VERSION ""

NS_ :

BS_:

BU_: CLU AMP H_U CGW TMU

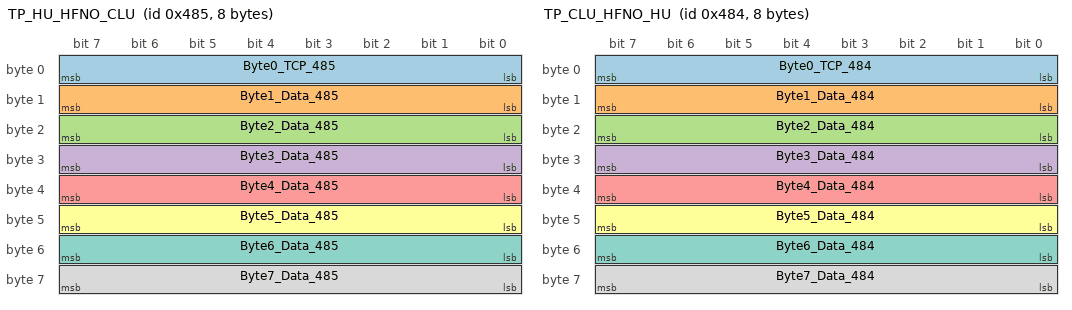
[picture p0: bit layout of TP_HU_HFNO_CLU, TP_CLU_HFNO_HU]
BO_ 1157 TP_HU_HFNO_CLU: 8 H_U
 SG_ Byte0_TCP_485 : 7|8@0+ (1,0) [0|0] ""  CLU
 SG_ Byte1_Data_485 : 15|8@0+ (1,0) [0|0] ""  CLU
 SG_ Byte2_Data_485 : 23|8@0+ (1,0) [0|0] ""  CLU
 SG_ Byte3_Data_485 : 31|8@0+ (1,0) [0|0] ""  CLU
 SG_ Byte4_Data_485 : 39|8@0+ (1,0) [0|0] ""  CLU
 SG_ Byte5_Data_485 : 47|8@0+ (1,0) [0|0] ""  CLU
 SG_ Byte6_Data_485 : 55|8@0+ (1,0) [0|0] ""  CLU
 SG_ Byte7_Data_485 : 63|8@0+ (1,0) [0|0] ""  CLU

BO_ 1156 TP_CLU_HFNO_HU: 8 CLU
 SG_ Byte0_TCP_484 : 7|8@0+ (1,0) [0|0] ""  H_U
 SG_ Byte1_Data_484 : 15|8@0+ (1,0) [0|0] ""  H_U
 SG_ Byte2_Data_484 : 23|8@0+ (1,0) [0|0] ""  H_U
 SG_ Byte3_Data_484 : 31|8@0+ (1,0) [0|0] ""  H_U
 SG_ Byte4_Data_484 : 39|8@0+ (1,0) [0|0] ""  H_U
 SG_ Byte5_Data_484 : 47|8@0+ (1,0) [0|0] ""  H_U
 SG_ Byte6_Data_484 : 55|8@0+ (1,0) [0|0] ""  H_U
 SG_ Byte7_Data_484 : 63|8@0+ (1,0) [0|0] ""  H_U

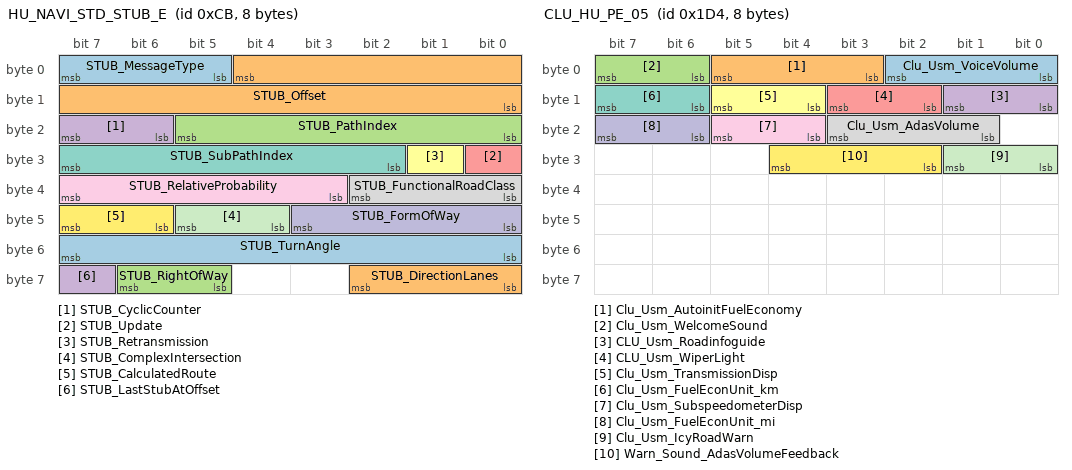
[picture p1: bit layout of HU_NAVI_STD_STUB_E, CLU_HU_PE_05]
BO_ 203 HU_NAVI_STD_STUB_E: 8 H_U
 SG_ STUB_MessageType : 7|3@0+ (1,0) [0|0] ""  CGW,CLU
 SG_ STUB_Offset : 4|13@0+ (1,0) [0|0] "m"  CGW,CLU
 SG_ STUB_PathIndex : 21|6@0+ (1,0) [0|0] ""  CGW,CLU
 SG_ STUB_CyclicCounter : 23|2@0+ (1,0) [0|0] ""  CGW,CLU
 SG_ STUB_Update : 24|1@0+ (1,0) [0|0] ""  CGW,CLU
 SG_ STUB_Retransmission : 25|1@0+ (1,0) [0|0] ""  CGW,CLU
 SG_ STUB_SubPathIndex : 31|6@0+ (1,0) [0|0] ""  CGW,CLU
 SG_ STUB_FunctionalRoadClass : 34|3@0+ (1,0) [0|0] ""  CGW,CLU
 SG_ STUB_RelativeProbability : 39|5@0+ (3.333,0) [0|0] "%"  CGW,CLU
 SG_ STUB_FormOfWay : 43|4@0+ (1,0) [0|0] ""  CGW,CLU
 SG_ STUB_ComplexIntersection : 45|2@0+ (1,0) [0|0] ""  CGW,CLU
 SG_ STUB_CalculatedRoute : 47|2@0+ (1,0) [0|0] ""  CGW,CLU
 SG_ STUB_TurnAngle : 55|8@0+ (1.417,0) [0|0] ""  CGW,CLU
 SG_ STUB_DirectionLanes : 58|3@0+ (1,0) [0|0] ""  CGW,CLU
 SG_ STUB_RightOfWay : 62|2@0+ (1,0) [0|0] ""  CGW,CLU
 SG_ STUB_LastStubAtOffset : 63|1@0+ (1,0) [0|0] ""  CGW,CLU

BO_ 202 HU_NAVI_STD_SEG_E: 8 H_U
 SG_ SEG_MessageType : 7|3@0+ (1,0) [0|0] ""  CGW,CLU
 SG_ SEG_Offset : 4|13@0+ (1,0) [0|0] "m"  CGW,CLU
 SG_ SEG_PathIndex : 21|6@0+ (1,0) [0|0] ""  CGW,CLU
 SG_ SEG_CyclicCounter : 23|2@0+ (1,0) [0|0] ""  CGW,CLU
 SG_ SEG_Update : 24|1@0+ (1,0) [0|0] ""  CGW,CLU
 SG_ SEG_Retransmission : 25|1@0+ (1,0) [0|0] ""  CGW,CLU
 SG_ SEG_BuiltUpArea : 27|2@0+ (1,0) [0|0] ""  CGW,CLU
 SG_ SEG_Bridge : 29|2@0+ (1,0) [0|0] ""  CGW,CLU
 SG_ SEG_Tunnel : 31|2@0+ (1,0) [0|0] ""  CGW,CLU
 SG_ SEG_FunctionalRoadClass : 34|3@0+ (1,0) [0|0] ""  CGW,CLU
 SG_ SEG_RelativeProbability : 39|5@0+ (3.333,0) [0|0] "%"  CGW,CLU
 SG_ SEG_FormOfWay : 43|4@0+ (1,0) [0|0] ""  CGW,CLU
 SG_ SEG_ComplexIntersection : 45|2@0+ (1,0) [0|0] ""  CGW,CLU
 SG_ SEG_CalculatedRoute : 47|2@0+ (1,0) [0|0] ""  CGW,CLU
 SG_ SEG_SpeedLimitType : 50|3@0+ (1,0) [0|0] ""  CGW,CLU
 SG_ SEG_SpeedLimit : 55|5@0+ (1,0) [0|0] ""  CGW,CLU
 SG_ SEG_DirectionLanes : 58|3@0+ (1,0) [0|0] ""  CGW,CLU
 SG_ SEG_SpeedLimitUnder5 : 62|3@0+ (1,0) [0|0] ""  CGW,CLU

BO_ 468 CLU_HU_PE_05: 8 CLU
 SG_ Clu_Usm_VoiceVolume : 2|3@0+ (1,0) [0|7] ""  H_U
 SG_ Clu_Usm_AutoinitFuelEconomy : 5|3@0+ (1,0) [0|7] ""  H_U
 SG_ Clu_Usm_WelcomeSound : 7|2@0+ (1,0) [0|3] ""  H_U
 SG_ CLU_Usm_Roadinfoguide : 9|2@0+ (1,0) [0|3] ""  H_U
 SG_ CLU_Usm_WiperLight : 11|2@0+ (1,0) [0|3] ""  H_U
 SG_ Clu_Usm_TransmissionDisp : 13|2@0+ (1,0) [0|3] ""  H_U
 SG_ Clu_Usm_FuelEconUnit_km : 15|2@0+ (1,0) [0|3] ""  H_U
 SG_ Clu_Usm_AdasVolume : 19|3@0+ (1,0) [0|7] ""  AMP,H_U
 SG_ Clu_Usm_SubspeedometerDisp : 21|2@0+ (1,0) [0|3] ""  H_U
 SG_ Clu_Usm_FuelEconUnit_mi : 23|2@0+ (1,0) [0|3] ""  H_U
 SG_ Clu_Usm_IcyRoadWarn : 25|2@0+ (1,0) [0|0] ""  H_U
 SG_ Warn_Sound_AdasVolumeFeedback : 28|3@0+ (1,0) [0|7] ""  AMP,H_U

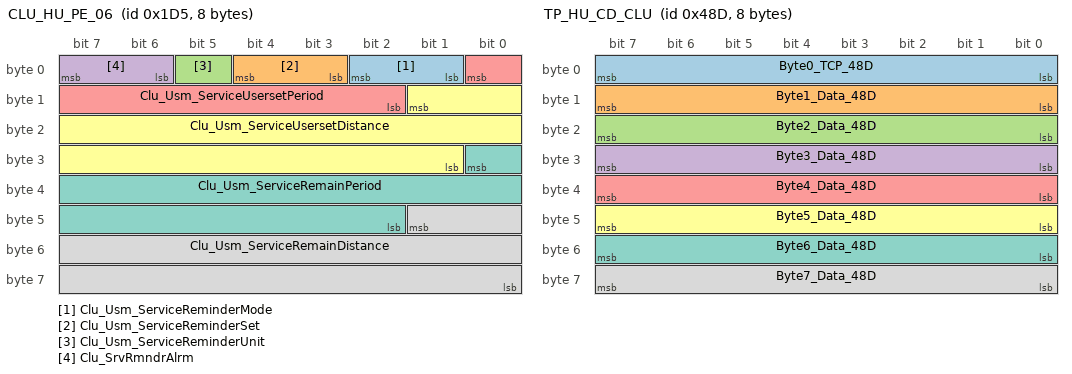
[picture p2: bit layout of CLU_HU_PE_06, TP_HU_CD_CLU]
BO_ 469 CLU_HU_PE_06: 8 CLU
 SG_ Clu_Usm_ServiceReminderMode : 2|2@0+ (1,0) [0|3] ""  H_U
 SG_ Clu_Usm_ServiceReminderSet : 4|2@0+ (1,0) [0|3] ""  H_U
 SG_ Clu_Usm_ServiceReminderUnit : 5|1@0+ (1,0) [0|1] ""  H_U
 SG_ Clu_SrvRmndrAlrm : 7|2@0+ (1,0) [0|0] ""  H_U
 SG_ Clu_Usm_ServiceUsersetPeriod : 0|7@0+ (1,0) [0|127] ""  H_U
 SG_ Clu_Usm_ServiceUsersetDistance : 9|17@0+ (1,0) [0|131071] ""  H_U
 SG_ Clu_Usm_ServiceRemainPeriod : 24|15@0+ (1,0) [0|32767] ""  H_U
 SG_ Clu_Usm_ServiceRemainDistance : 41|18@0+ (1,0) [0|262143] ""  H_U

BO_ 1165 TP_HU_CD_CLU: 8 H_U
 SG_ Byte0_TCP_48D : 7|8@0+ (1,0) [0|0] ""  CLU
 SG_ Byte1_Data_48D : 15|8@0+ (1,0) [0|0] ""  CLU
 SG_ Byte2_Data_48D : 23|8@0+ (1,0) [0|0] ""  CLU
 SG_ Byte3_Data_48D : 31|8@0+ (1,0) [0|0] ""  CLU
 SG_ Byte4_Data_48D : 39|8@0+ (1,0) [0|0] ""  CLU
 SG_ Byte5_Data_48D : 47|8@0+ (1,0) [0|0] ""  CLU
 SG_ Byte6_Data_48D : 55|8@0+ (1,0) [0|0] ""  CLU
 SG_ Byte7_Data_48D : 63|8@0+ (1,0) [0|0] ""  CLU

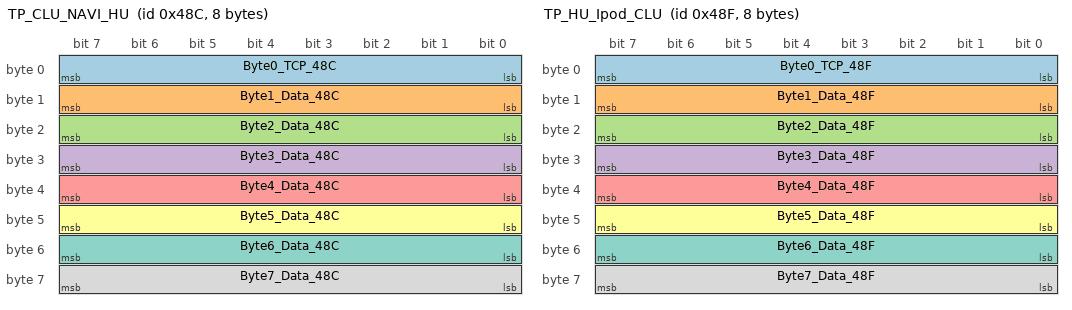
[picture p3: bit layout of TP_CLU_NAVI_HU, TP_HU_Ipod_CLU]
BO_ 1164 TP_CLU_NAVI_HU: 8 CLU
 SG_ Byte0_TCP_48C : 7|8@0+ (1,0) [0|0] ""  H_U
 SG_ Byte1_Data_48C : 15|8@0+ (1,0) [0|0] ""  H_U
 SG_ Byte2_Data_48C : 23|8@0+ (1,0) [0|0] ""  H_U
 SG_ Byte3_Data_48C : 31|8@0+ (1,0) [0|0] ""  H_U
 SG_ Byte4_Data_48C : 39|8@0+ (1,0) [0|0] ""  H_U
 SG_ Byte5_Data_48C : 47|8@0+ (1,0) [0|0] ""  H_U
 SG_ Byte6_Data_48C : 55|8@0+ (1,0) [0|0] ""  H_U
 SG_ Byte7_Data_48C : 63|8@0+ (1,0) [0|0] ""  H_U

BO_ 1167 TP_HU_Ipod_CLU: 8 H_U
 SG_ Byte0_TCP_48F : 7|8@0+ (1,0) [0|0] ""  CLU
 SG_ Byte1_Data_48F : 15|8@0+ (1,0) [0|0] ""  CLU
 SG_ Byte2_Data_48F : 23|8@0+ (1,0) [0|0] ""  CLU
 SG_ Byte3_Data_48F : 31|8@0+ (1,0) [0|0] ""  CLU
 SG_ Byte4_Data_48F : 39|8@0+ (1,0) [0|0] ""  CLU
 SG_ Byte5_Data_48F : 47|8@0+ (1,0) [0|0] ""  CLU
 SG_ Byte6_Data_48F : 55|8@0+ (1,0) [0|0] ""  CLU
 SG_ Byte7_Data_48F : 63|8@0+ (1,0) [0|0] ""  CLU

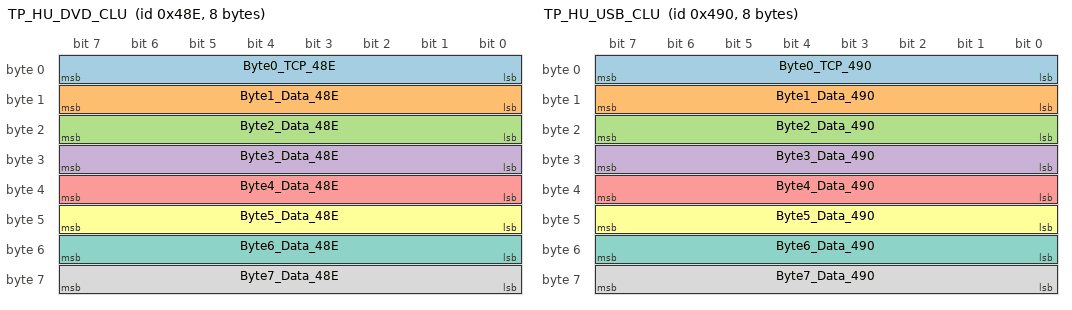
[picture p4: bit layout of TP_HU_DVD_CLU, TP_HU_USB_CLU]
BO_ 1166 TP_HU_DVD_CLU: 8 H_U
 SG_ Byte0_TCP_48E : 7|8@0+ (1,0) [0|0] ""  CLU
 SG_ Byte1_Data_48E : 15|8@0+ (1,0) [0|0] ""  CLU
 SG_ Byte2_Data_48E : 23|8@0+ (1,0) [0|0] ""  CLU
 SG_ Byte3_Data_48E : 31|8@0+ (1,0) [0|0] ""  CLU
 SG_ Byte4_Data_48E : 39|8@0+ (1,0) [0|0] ""  CLU
 SG_ Byte5_Data_48E : 47|8@0+ (1,0) [0|0] ""  CLU
 SG_ Byte6_Data_48E : 55|8@0+ (1,0) [0|0] ""  CLU
 SG_ Byte7_Data_48E : 63|8@0+ (1,0) [0|0] ""  CLU

BO_ 1168 TP_HU_USB_CLU: 8 H_U
 SG_ Byte0_TCP_490 : 7|8@0+ (1,0) [0|0] ""  CLU
 SG_ Byte1_Data_490 : 15|8@0+ (1,0) [0|0] ""  CLU
 SG_ Byte2_Data_490 : 23|8@0+ (1,0) [0|0] ""  CLU
 SG_ Byte3_Data_490 : 31|8@0+ (1,0) [0|0] ""  CLU
 SG_ Byte4_Data_490 : 39|8@0+ (1,0) [0|0] ""  CLU
 SG_ Byte5_Data_490 : 47|8@0+ (1,0) [0|0] ""  CLU
 SG_ Byte6_Data_490 : 55|8@0+ (1,0) [0|0] ""  CLU
 SG_ Byte7_Data_490 : 63|8@0+ (1,0) [0|0] ""  CLU

BO_ 1408 AMP_HU_P_01: 8 AMP
 SG_ AMP_Support_ElecSound : 57|2@0+ (1,0) [0|0] ""  CLU,H_U

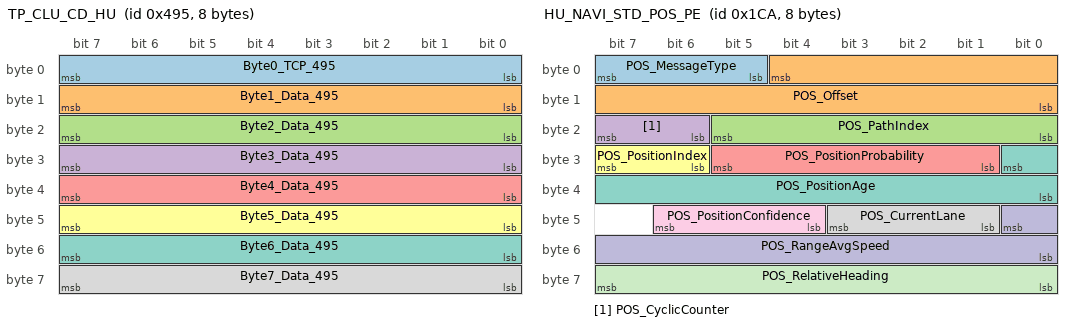
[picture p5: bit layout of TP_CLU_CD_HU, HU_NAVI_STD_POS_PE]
BO_ 1173 TP_CLU_CD_HU: 8 CLU
 SG_ Byte0_TCP_495 : 7|8@0+ (1,0) [0|0] ""  H_U
 SG_ Byte1_Data_495 : 15|8@0+ (1,0) [0|0] ""  H_U
 SG_ Byte2_Data_495 : 23|8@0+ (1,0) [0|0] ""  H_U
 SG_ Byte3_Data_495 : 31|8@0+ (1,0) [0|0] ""  H_U
 SG_ Byte4_Data_495 : 39|8@0+ (1,0) [0|0] ""  H_U
 SG_ Byte5_Data_495 : 47|8@0+ (1,0) [0|0] ""  H_U
 SG_ Byte6_Data_495 : 55|8@0+ (1,0) [0|0] ""  H_U
 SG_ Byte7_Data_495 : 63|8@0+ (1,0) [0|0] ""  H_U

BO_ 458 HU_NAVI_STD_POS_PE: 8 H_U
 SG_ POS_MessageType : 7|3@0+ (1,0) [0|0] ""  CGW,CLU
 SG_ POS_Offset : 4|13@0+ (1,0) [0|0] "m"  CGW,CLU
 SG_ POS_PathIndex : 21|6@0+ (1,0) [0|0] ""  CGW,CLU
 SG_ POS_CyclicCounter : 23|2@0+ (1,0) [0|0] ""  CGW,CLU
 SG_ POS_PositionProbability : 29|5@0+ (3.333,0) [0|0] "%"  CGW,CLU
 SG_ POS_PositionIndex : 31|2@0+ (1,0) [0|0] ""  CGW,CLU
 SG_ POS_PositionAge : 24|9@0+ (5,0) [0|0] "ms"  CGW,CLU
 SG_ POS_CurrentLane : 43|3@0+ (1,0) [0|0] ""  CGW,CLU
 SG_ POS_PositionConfidence : 46|3@0+ (1,0) [0|0] ""  CGW,CLU
 SG_ POS_RangeAvgSpeed : 40|9@0+ (1,0) [0|0] "km/h"  CGW,CLU
 SG_ POS_RelativeHeading : 63|8@0+ (1.417,0) [0|0] ""  CGW,CLU

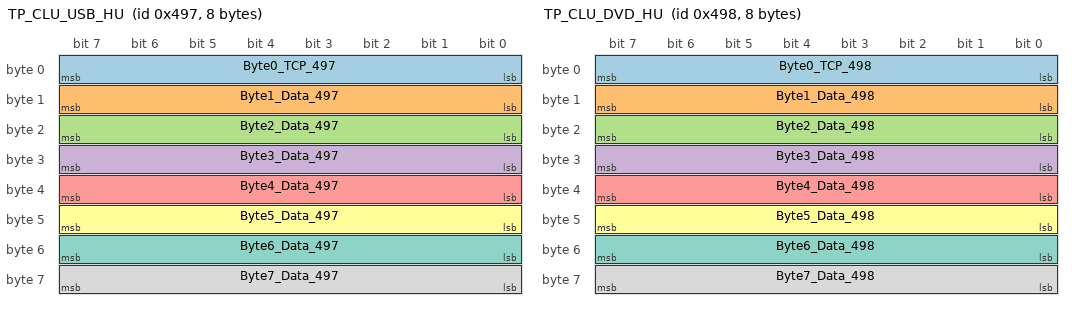
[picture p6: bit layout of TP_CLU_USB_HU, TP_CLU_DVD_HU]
BO_ 1175 TP_CLU_USB_HU: 8 CLU
 SG_ Byte0_TCP_497 : 7|8@0+ (1,0) [0|0] ""  H_U
 SG_ Byte1_Data_497 : 15|8@0+ (1,0) [0|0] ""  H_U
 SG_ Byte2_Data_497 : 23|8@0+ (1,0) [0|0] ""  H_U
 SG_ Byte3_Data_497 : 31|8@0+ (1,0) [0|0] ""  H_U
 SG_ Byte4_Data_497 : 39|8@0+ (1,0) [0|0] ""  H_U
 SG_ Byte5_Data_497 : 47|8@0+ (1,0) [0|0] ""  H_U
 SG_ Byte6_Data_497 : 55|8@0+ (1,0) [0|0] ""  H_U
 SG_ Byte7_Data_497 : 63|8@0+ (1,0) [0|0] ""  H_U

BO_ 1176 TP_CLU_DVD_HU: 8 CLU
 SG_ Byte0_TCP_498 : 7|8@0+ (1,0) [0|0] ""  H_U
 SG_ Byte1_Data_498 : 15|8@0+ (1,0) [0|0] ""  H_U
 SG_ Byte2_Data_498 : 23|8@0+ (1,0) [0|0] ""  H_U
 SG_ Byte3_Data_498 : 31|8@0+ (1,0) [0|0] ""  H_U
 SG_ Byte4_Data_498 : 39|8@0+ (1,0) [0|0] ""  H_U
 SG_ Byte5_Data_498 : 47|8@0+ (1,0) [0|0] ""  H_U
 SG_ Byte6_Data_498 : 55|8@0+ (1,0) [0|0] ""  H_U
 SG_ Byte7_Data_498 : 63|8@0+ (1,0) [0|0] ""  H_U

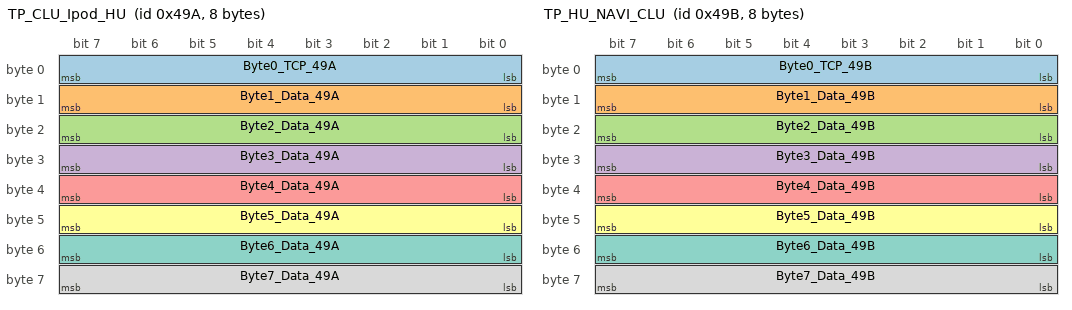
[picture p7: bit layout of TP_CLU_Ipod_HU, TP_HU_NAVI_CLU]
BO_ 1178 TP_CLU_Ipod_HU: 8 CLU
 SG_ Byte0_TCP_49A : 7|8@0+ (1,0) [0|0] ""  H_U
 SG_ Byte1_Data_49A : 15|8@0+ (1,0) [0|0] ""  H_U
 SG_ Byte2_Data_49A : 23|8@0+ (1,0) [0|0] ""  H_U
 SG_ Byte3_Data_49A : 31|8@0+ (1,0) [0|0] ""  H_U
 SG_ Byte4_Data_49A : 39|8@0+ (1,0) [0|0] ""  H_U
 SG_ Byte5_Data_49A : 47|8@0+ (1,0) [0|0] ""  H_U
 SG_ Byte6_Data_49A : 55|8@0+ (1,0) [0|0] ""  H_U
 SG_ Byte7_Data_49A : 63|8@0+ (1,0) [0|0] ""  H_U

BO_ 1179 TP_HU_NAVI_CLU: 8 H_U
 SG_ Byte0_TCP_49B : 7|8@0+ (1,0) [0|0] ""  CLU
 SG_ Byte1_Data_49B : 15|8@0+ (1,0) [0|0] ""  CLU
 SG_ Byte2_Data_49B : 23|8@0+ (1,0) [0|0] ""  CLU
 SG_ Byte3_Data_49B : 31|8@0+ (1,0) [0|0] ""  CLU
 SG_ Byte4_Data_49B : 39|8@0+ (1,0) [0|0] ""  CLU
 SG_ Byte5_Data_49B : 47|8@0+ (1,0) [0|0] ""  CLU
 SG_ Byte6_Data_49B : 55|8@0+ (1,0) [0|0] ""  CLU
 SG_ Byte7_Data_49B : 63|8@0+ (1,0) [0|0] ""  CLU

BO_ 88 HU_RVM_E_00: 8 H_U
 SG_ HU_RVM_CameraOff : 1|2@0+ (1,0) [0|0] ""  CGW,CLU

BO_ 448 HU_DATC_PE_00: 8 H_U
 SG_ HU_VRActivity : 33|2@0+ (1,0) [0|0] ""  CGW,CLU,TMU
 SG_ HU_PhoneActivity : 35|2@0+ (1,0) [0|0] ""  CGW,CLU,TMU

BO_ 102 HU_USM_E_02: 8 H_U
 SG_ CF_AVN_PTGSpeedNValueSet : 39|2@0+ (1,0) [0|0] ""  CGW,CLU
 SG_ CF_Avn_HAPTICWARNINGNValueSet : 54|3@0+ (1,0) [0|0] ""  CGW,CLU

BO_ 101 HU_USM_E_01: 8 H_U
 SG_ CF_AVN_LFANValueSet : 4|2@0+ (1,0) [0|0] ""  CGW,CLU
 SG_ CF_AVN_FCANValueSet : 7|3@0+ (1,0) [0|0] ""  CGW,CLU
 SG_ CF_AVN_HDANValueSet : 9|2@0+ (1,0) [0|0] ""  CGW,CLU
 SG_ CF_AVN_DAWModeNValueSet : 12|3@0+ (1,0) [0|0] ""  CGW,CLU
 SG_ CF_AVN_SCCDrvModeNValueSet : 15|3@0+ (1,0) [0|0] ""  CGW,CLU
 SG_ CF_AVN_NSCCCamNValueSet : 19|2@0+ (1,0) [0|0] ""  CGW,CLU
 SG_ CF_AVN_SEANValueSet : 21|2@0+ (1,0) [0|0] ""  CGW,CLU
 SG_ CF_AVN_BCWNValueSet : 23|2@0+ (1,0) [0|0] ""  CGW,CLU
 SG_ CF_AVN_WarningTimingNValueSet : 26|3@0+ (1,0) [0|0] ""  CGW,CLU
 SG_ CF_AVN_ISLWNValueSet : 28|2@0+ (1,0) [0|0] ""  CGW,CLU
 SG_ CF_AVN_BCANValueSet : 31|3@0+ (1,0) [0|0] ""  CGW,CLU
 SG_ CF_AVN_RCCWNValueSet : 41|2@0+ (1,0) [0|0] ""  CGW,CLU
 SG_ CF_AVN_BCWSndWanNValueSet : 43|2@0+ (1,0) [0|0] ""  CGW,CLU
 SG_ CF_AVN_NSCCCrvNValueSet : 45|2@0+ (1,0) [0|0] ""  CGW,CLU
 SG_ CF_SccFrVehDptNotiNValueSet : 49|2@0+ (1,0) [0|0] ""  CGW,CLU
 SG_ CF_AVN_LkaModeNValueSet : 54|3@0+ (1,0) [0|0] ""  CGW,CLU
 SG_ CF_AVN_AdasVolumeNValueSet : 58|3@0+ (1,0) [0|0] ""  CLU

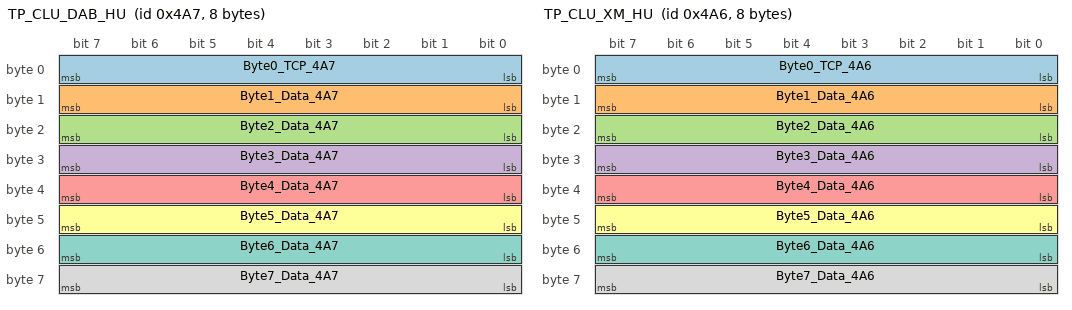
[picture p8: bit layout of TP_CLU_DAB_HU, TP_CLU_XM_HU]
BO_ 1191 TP_CLU_DAB_HU: 8 CLU
 SG_ Byte0_TCP_4A7 : 7|8@0+ (1,0) [0|0] ""  H_U
 SG_ Byte1_Data_4A7 : 15|8@0+ (1,0) [0|0] ""  H_U
 SG_ Byte2_Data_4A7 : 23|8@0+ (1,0) [0|0] ""  H_U
 SG_ Byte3_Data_4A7 : 31|8@0+ (1,0) [0|0] ""  H_U
 SG_ Byte4_Data_4A7 : 39|8@0+ (1,0) [0|0] ""  H_U
 SG_ Byte5_Data_4A7 : 47|8@0+ (1,0) [0|0] ""  H_U
 SG_ Byte6_Data_4A7 : 55|8@0+ (1,0) [0|0] ""  H_U
 SG_ Byte7_Data_4A7 : 63|8@0+ (1,0) [0|0] ""  H_U

BO_ 369 HU_Car_PE_01: 8 H_U
 SG_ HU_VehiclePwr : 3|4@0+ (1,0) [0|0] ""  AMP,CLU,TMU

BO_ 1190 TP_CLU_XM_HU: 8 CLU
 SG_ Byte0_TCP_4A6 : 7|8@0+ (1,0) [0|0] ""  H_U
 SG_ Byte1_Data_4A6 : 15|8@0+ (1,0) [0|0] ""  H_U
 SG_ Byte2_Data_4A6 : 23|8@0+ (1,0) [0|0] ""  H_U
 SG_ Byte3_Data_4A6 : 31|8@0+ (1,0) [0|0] ""  H_U
 SG_ Byte4_Data_4A6 : 39|8@0+ (1,0) [0|0] ""  H_U
 SG_ Byte5_Data_4A6 : 47|8@0+ (1,0) [0|0] ""  H_U
 SG_ Byte6_Data_4A6 : 55|8@0+ (1,0) [0|0] ""  H_U
 SG_ Byte7_Data_4A6 : 63|8@0+ (1,0) [0|0] ""  H_U

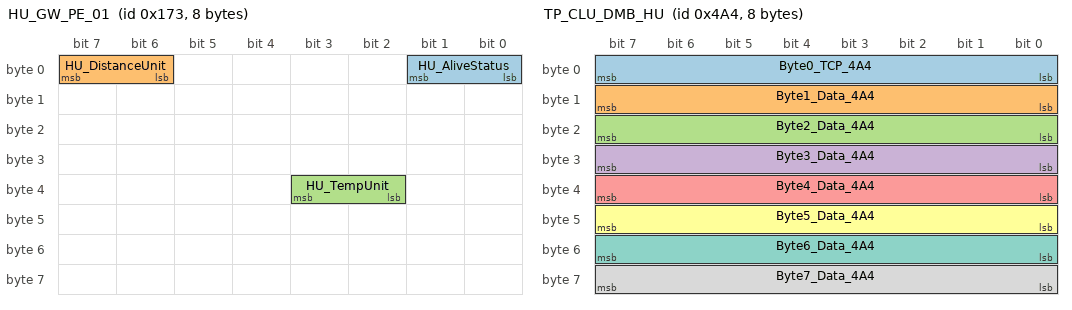
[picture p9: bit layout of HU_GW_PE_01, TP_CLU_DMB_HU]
BO_ 371 HU_GW_PE_01: 8 H_U
 SG_ HU_AliveStatus : 1|2@0+ (1,0) [0|0] ""  CGW,CLU,TMU
 SG_ HU_DistanceUnit : 7|2@0+ (1,0) [0|0] ""  CLU,TMU
 SG_ HU_TempUnit : 35|2@0+ (1,0) [0|0] ""  CGW,CLU

BO_ 1188 TP_CLU_DMB_HU: 8 CLU
 SG_ Byte0_TCP_4A4 : 7|8@0+ (1,0) [0|0] ""  H_U
 SG_ Byte1_Data_4A4 : 15|8@0+ (1,0) [0|0] ""  H_U
 SG_ Byte2_Data_4A4 : 23|8@0+ (1,0) [0|0] ""  H_U
 SG_ Byte3_Data_4A4 : 31|8@0+ (1,0) [0|0] ""  H_U
 SG_ Byte4_Data_4A4 : 39|8@0+ (1,0) [0|0] ""  H_U
 SG_ Byte5_Data_4A4 : 47|8@0+ (1,0) [0|0] ""  H_U
 SG_ Byte6_Data_4A4 : 55|8@0+ (1,0) [0|0] ""  H_U
 SG_ Byte7_Data_4A4 : 63|8@0+ (1,0) [0|0] ""  H_U

BO_ 104 HU_USM_E_04: 8 H_U
 SG_ CF_AVN_CluVoiceVolume : 2|3@0+ (1,0) [0|0] ""  CLU
 SG_ CF_AVN_CluAutoInitFuelEconomy : 5|3@0+ (1,0) [0|0] ""  CLU
 SG_ CF_AVN_CluWelcomeSnd : 7|2@0+ (1,0) [0|0] ""  CLU
 SG_ CF_AVN_CluRoadInfoGuide : 9|2@0+ (1,0) [0|0] ""  CLU
 SG_ CF_AVN_CluWiperLight : 11|2@0+ (1,0) [0|0] ""  CLU
 SG_ CF_AVN_CluTransmissionDisp : 13|2@0+ (1,0) [0|0] ""  CLU
 SG_ CF_AVN_CluServiceReminderSet : 15|2@0+ (1,0) [0|0] ""  CLU
 SG_ CF_AVN_CluUserSettingPeriod : 22|7@0+ (1,0) [0|0] ""  CLU
 SG_ CF_AVN_CluFuelEconUnit_km : 26|2@0+ (1,0) [0|0] ""  CGW,CLU
 SG_ CF_AVN_CluFuelEconUnit_mi : 28|2@0+ (1,0) [0|0] ""  CGW,CLU
 SG_ CF_AVN_CluSubspeedOdometerDisp : 30|2@0+ (1,0) [0|0] ""  CGW,CLU
 SG_ CF_AVN_CluUserSettingDistance : 24|17@0+ (1,0) [0|0] ""  CLU
 SG_ CF_AVN_EVReset : 49|2@0+ (1,0) [0|0] ""  CGW,CLU
 SG_ CF_AVN_CluUSMReset : 57|2@0+ (1,0) [0|0] ""  CGW,CLU
 SG_ CF_AVN_CluServiceReminderReset : 59|2@0+ (1,0) [0|0] ""  CLU
 SG_ CF_AVN_IcyRoadWarn : 61|2@0+ (1,0) [0|0] ""  CLU
 SG_ CF_AVN_UnitReset : 63|2@0+ (1,0) [0|0] ""  CGW,CLU

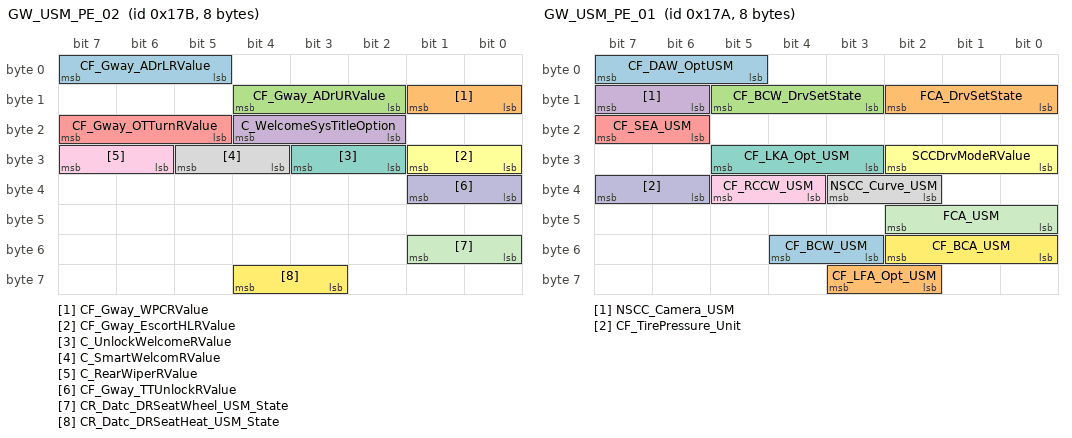
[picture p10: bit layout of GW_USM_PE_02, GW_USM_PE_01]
BO_ 379 GW_USM_PE_02: 8 CGW
 SG_ CF_Gway_ADrLRValue : 7|3@0+ (1,0) [0|0] ""  CLU,H_U
 SG_ CF_Gway_WPCRValue : 9|2@0+ (1,0) [0|0] ""  CLU,H_U
 SG_ CF_Gway_ADrURValue : 12|3@0+ (1,0) [0|0] ""  CLU,H_U
 SG_ C_WelcomeSysTitleOption : 20|3@0+ (1,0) [0|0] ""  CLU,H_U
 SG_ CF_Gway_OTTurnRValue : 23|3@0+ (1,0) [0|0] ""  CLU,H_U
 SG_ CF_Gway_EscortHLRValue : 25|2@0+ (1,0) [0|0] ""  CLU,H_U
 SG_ C_UnlockWelcomeRValue : 27|2@0+ (1,0) [0|0] ""  CLU,H_U
 SG_ C_SmartWelcomRValue : 29|2@0+ (1,0) [0|0] ""  CLU,H_U
 SG_ C_RearWiperRValue : 31|2@0+ (1,0) [0|0] ""  CLU,H_U
 SG_ CF_Gway_TTUnlockRValue : 33|2@0+ (1,0) [0|0] ""  CLU,H_U
 SG_ CR_Datc_DRSeatWheel_USM_State : 49|2@0+ (1,0) [0|0] ""  CLU,H_U
 SG_ CR_Datc_DRSeatHeat_USM_State : 60|2@0+ (1,0) [0|0] ""  CLU,H_U

BO_ 378 GW_USM_PE_01: 8 CGW
 SG_ CF_DAW_OptUSM : 7|3@0+ (1,0) [0|0] ""  CLU,H_U
 SG_ FCA_DrvSetState : 10|3@0+ (1,0) [0|0] ""  CLU,H_U
 SG_ CF_BCW_DrvSetState : 13|3@0+ (1,0) [0|0] ""  CLU,H_U
 SG_ NSCC_Camera_USM : 15|2@0+ (1,0) [0|0] ""  CLU,H_U
 SG_ CF_SEA_USM : 23|2@0+ (1,0) [0|0] ""  CLU,H_U
 SG_ SCCDrvModeRValue : 26|3@0+ (1,0) [0|0] ""  CLU,H_U
 SG_ CF_LKA_Opt_USM : 29|3@0+ (1,0) [0|0] ""  CLU,H_U
 SG_ NSCC_Curve_USM : 35|2@0+ (1,0) [0|0] ""  CLU,H_U
 SG_ CF_RCCW_USM : 37|2@0+ (1,0) [0|0] ""  CLU,H_U
 SG_ CF_TirePressure_Unit : 39|2@0+ (1,0) [0|0] ""  CLU,H_U
 SG_ FCA_USM : 42|3@0+ (1,0) [0|0] ""  CLU,H_U
 SG_ CF_BCA_USM : 50|3@0+ (1,0) [0|0] ""  CLU,H_U
 SG_ CF_BCW_USM : 52|2@0+ (1,0) [0|0] ""  CLU,H_U
 SG_ CF_LFA_Opt_USM : 59|2@0+ (1,0) [0|0] ""  CLU,H_U

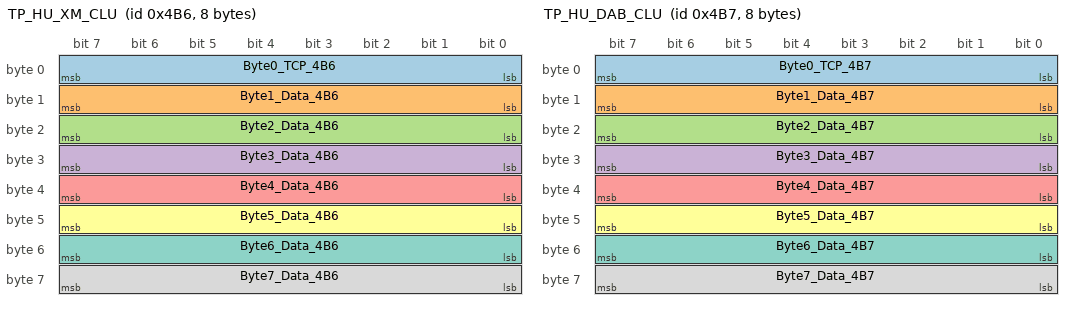
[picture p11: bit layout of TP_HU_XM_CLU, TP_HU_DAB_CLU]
BO_ 1206 TP_HU_XM_CLU: 8 H_U
 SG_ Byte0_TCP_4B6 : 7|8@0+ (1,0) [0|0] ""  CLU
 SG_ Byte1_Data_4B6 : 15|8@0+ (1,0) [0|0] ""  CLU
 SG_ Byte2_Data_4B6 : 23|8@0+ (1,0) [0|0] ""  CLU
 SG_ Byte3_Data_4B6 : 31|8@0+ (1,0) [0|0] ""  CLU
 SG_ Byte4_Data_4B6 : 39|8@0+ (1,0) [0|0] ""  CLU
 SG_ Byte5_Data_4B6 : 47|8@0+ (1,0) [0|0] ""  CLU
 SG_ Byte6_Data_4B6 : 55|8@0+ (1,0) [0|0] ""  CLU
 SG_ Byte7_Data_4B6 : 63|8@0+ (1,0) [0|0] ""  CLU

BO_ 1207 TP_HU_DAB_CLU: 8 H_U
 SG_ Byte0_TCP_4B7 : 7|8@0+ (1,0) [0|0] ""  CLU
 SG_ Byte1_Data_4B7 : 15|8@0+ (1,0) [0|0] ""  CLU
 SG_ Byte2_Data_4B7 : 23|8@0+ (1,0) [0|0] ""  CLU
 SG_ Byte3_Data_4B7 : 31|8@0+ (1,0) [0|0] ""  CLU
 SG_ Byte4_Data_4B7 : 39|8@0+ (1,0) [0|0] ""  CLU
 SG_ Byte5_Data_4B7 : 47|8@0+ (1,0) [0|0] ""  CLU
 SG_ Byte6_Data_4B7 : 55|8@0+ (1,0) [0|0] ""  CLU
 SG_ Byte7_Data_4B7 : 63|8@0+ (1,0) [0|0] ""  CLU

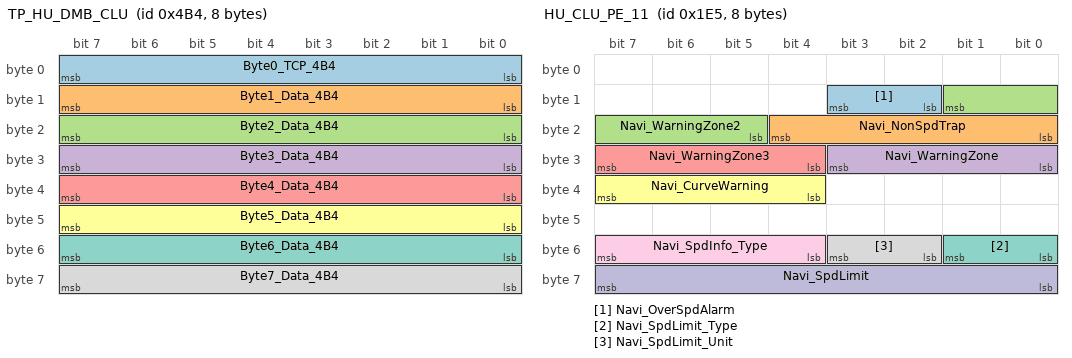
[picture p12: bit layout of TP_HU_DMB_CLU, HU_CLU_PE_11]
BO_ 1204 TP_HU_DMB_CLU: 8 H_U
 SG_ Byte0_TCP_4B4 : 7|8@0+ (1,0) [0|0] ""  CLU
 SG_ Byte1_Data_4B4 : 15|8@0+ (1,0) [0|0] ""  CLU
 SG_ Byte2_Data_4B4 : 23|8@0+ (1,0) [0|0] ""  CLU
 SG_ Byte3_Data_4B4 : 31|8@0+ (1,0) [0|0] ""  CLU
 SG_ Byte4_Data_4B4 : 39|8@0+ (1,0) [0|0] ""  CLU
 SG_ Byte5_Data_4B4 : 47|8@0+ (1,0) [0|0] ""  CLU
 SG_ Byte6_Data_4B4 : 55|8@0+ (1,0) [0|0] ""  CLU
 SG_ Byte7_Data_4B4 : 63|8@0+ (1,0) [0|0] ""  CLU

BO_ 491 GW_DDM_PE: 8 CGW
 SG_ C_OSMirrorStatus : 11|2@0+ (1,0) [0|0] ""  AMP,CLU,H_U,TMU

BO_ 485 HU_CLU_PE_11: 8 H_U
 SG_ Navi_OverSpdAlarm : 11|2@0+ (1,0) [0|0] ""  CGW,CLU
 SG_ Navi_NonSpdTrap : 20|5@0+ (1,0) [0|0] ""  CLU
 SG_ Navi_WarningZone2 : 9|5@0+ (1,0) [0|0] ""  CLU
 SG_ Navi_WarningZone : 27|4@0+ (1,0) [0|0] ""  CLU
 SG_ Navi_WarningZone3 : 31|4@0+ (1,0) [0|0] ""  CLU
 SG_ Navi_CurveWarning : 39|4@0+ (1,0) [0|0] ""  CLU
 SG_ Navi_SpdLimit_Type : 49|2@0+ (1,0) [0|0] ""  CLU
 SG_ Navi_SpdLimit_Unit : 51|2@0+ (1,0) [0|0] ""  CLU
 SG_ Navi_SpdInfo_Type : 55|4@0+ (1,0) [0|0] ""  CLU
 SG_ Navi_SpdLimit : 63|8@0+ (1,0) [1|254] ""  CLU

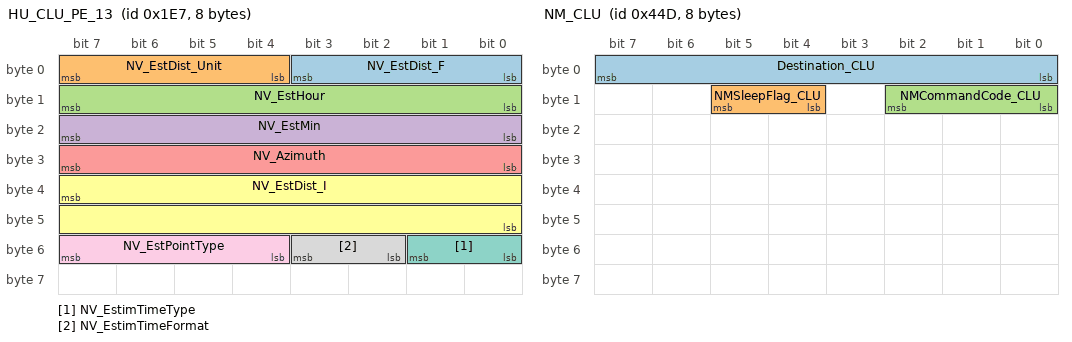
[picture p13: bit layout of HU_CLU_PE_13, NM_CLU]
BO_ 487 HU_CLU_PE_13: 8 H_U
 SG_ NV_EstDist_F : 3|4@0+ (1,0) [0|0] ""  CGW,CLU
 SG_ NV_EstDist_Unit : 7|4@0+ (1,0) [0|0] ""  CGW,CLU
 SG_ NV_EstHour : 15|8@0+ (1,0) [0|0] ""  CGW,CLU
 SG_ NV_EstMin : 23|8@0+ (1,0) [0|0] ""  CGW,CLU
 SG_ NV_Azimuth : 31|8@0+ (7.5,0) [0|352.5] "Degree"  CGW,CLU
 SG_ NV_EstDist_I : 39|16@0+ (1,0) [0|0] ""  CGW,CLU
 SG_ NV_EstimTimeType : 49|2@0+ (1,0) [0|0] ""  CGW,CLU
 SG_ NV_EstimTimeFormat : 51|2@0+ (1,0) [0|0] ""  CGW,CLU
 SG_ NV_EstPointType : 55|4@0+ (1,0) [0|0] ""  CGW,CLU

BO_ 362 GW_CarInfo_PE: 8 CGW
 SG_ C_AV_Tail : 1|2@0+ (1,0) [0|0] ""  AMP,CLU,H_U
 SG_ C_IGN1 : 21|2@0+ (1,0) [0|0] ""  AMP,CLU,H_U,TMU

BO_ 1101 NM_CLU: 8 CLU
 SG_ Destination_CLU : 7|8@0+ (1,0) [0|0] ""  AMP,H_U,CGW,TMU
 SG_ NMSleepFlag_CLU : 13|2@0+ (1,0) [0|0] ""  AMP,H_U,CGW,TMU
 SG_ NMCommandCode_CLU : 10|3@0+ (1,0) [0|0] ""  AMP,H_U,CGW,TMU

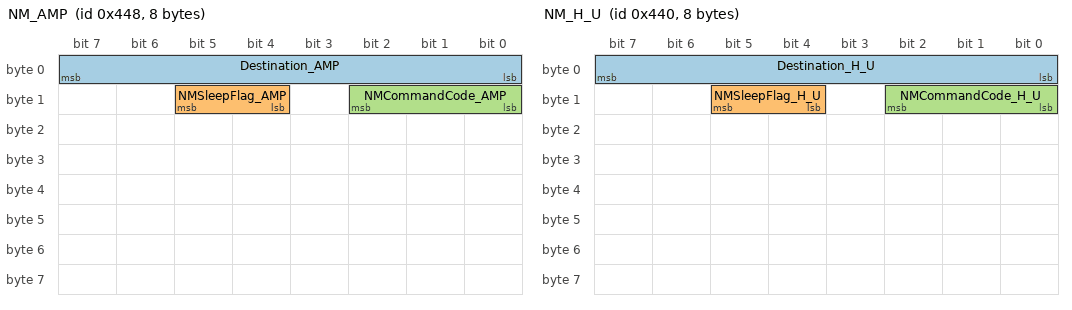
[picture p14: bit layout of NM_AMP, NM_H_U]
BO_ 1096 NM_AMP: 8 AMP
 SG_ Destination_AMP : 7|8@0+ (1,0) [0|0] ""  CLU,H_U,CGW,TMU
 SG_ NMSleepFlag_AMP : 13|2@0+ (1,0) [0|0] ""  CLU,H_U,CGW,TMU
 SG_ NMCommandCode_AMP : 10|3@0+ (1,0) [0|0] ""  CLU,H_U,CGW,TMU

BO_ 1088 NM_H_U: 8 H_U
 SG_ Destination_H_U : 7|8@0+ (1,0) [0|0] ""  CLU,AMP,CGW,TMU
 SG_ NMSleepFlag_H_U : 13|2@0+ (1,0) [0|0] ""  CLU,AMP,CGW,TMU
 SG_ NMCommandCode_H_U : 10|3@0+ (1,0) [0|0] ""  CLU,AMP,CGW,TMU

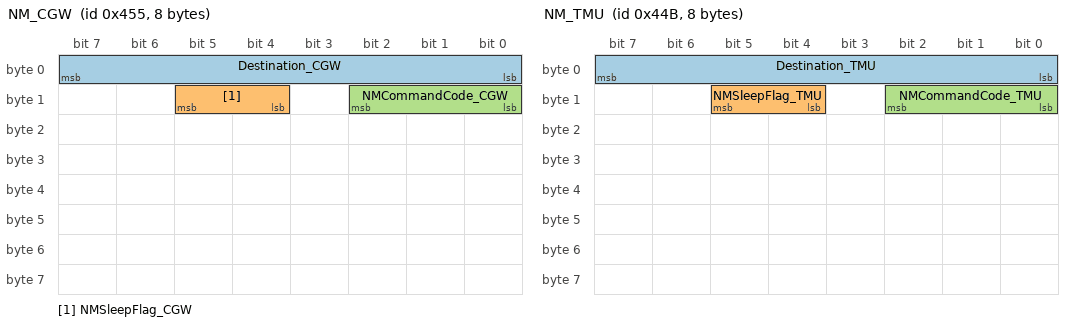
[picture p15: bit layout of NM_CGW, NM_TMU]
BO_ 1109 NM_CGW: 8 CGW
 SG_ Destination_CGW : 7|8@0+ (1,0) [0|0] ""  CLU,AMP,H_U,TMU
 SG_ NMSleepFlag_CGW : 13|2@0+ (1,0) [0|0] ""  CLU,AMP,H_U,TMU
 SG_ NMCommandCode_CGW : 10|3@0+ (1,0) [0|0] ""  CLU,AMP,H_U,TMU

BO_ 1099 NM_TMU: 8 TMU
 SG_ Destination_TMU : 7|8@0+ (1,0) [0|0] ""  CLU,AMP,H_U,CGW
 SG_ NMSleepFlag_TMU : 13|2@0+ (1,0) [0|0] ""  CLU,AMP,H_U,CGW
 SG_ NMCommandCode_TMU : 10|3@0+ (1,0) [0|0] ""  CLU,AMP,H_U,CGW

CM_ BO_ 1408 "[P] Periodic";
CM_ SG_ 1408 AMP_Support_ElecSound "inform to H/U & CLU whether amp support premium electric sound or not";
CM_ BO_ 362 "[PE] Periodic and On Event";
CM_ SG_ 362 C_AV_Tail "Autolight Info";
CM_ SG_ 362 C_IGN1 "Information for IGN1 Status";
CM_ BO_ 491 "[PE] Periodic and On Event";
CM_ SG_ 491 C_OSMirrorStatus "Assist Outside Mirror fold Unfold state";
CM_ BO_ 378 "[PE] Periodic and On Event";
CM_ SG_ 378 CF_DAW_OptUSM "This signal indicates the selected mode of LCA/BSD sound output.";
CM_ SG_ 378 FCA_DrvSetState "This signal represents the lastest FCA setup value of USM.";
CM_ SG_ 378 CF_BCW_DrvSetState "This signal represents the lastest BCW setup value of USM.";
CM_ SG_ 378 NSCC_Camera_USM "This signal describes thes of SCC with Navigation function.(speed camera control)";
CM_ SG_ 378 CF_SEA_USM "This signal represents the lastest SEA setup value of USM.";
CM_ SG_ 378 SCCDrvModeRValue "Drive mode return value";
CM_ SG_ 378 CF_LKA_Opt_USM "LKA System Option & USM setting Information to AVN/Cluster";
CM_ SG_ 378 NSCC_Curve_USM "This signal describes the status fo SCC with Navigation fucntion.(curvature control)";
CM_ SG_ 378 CF_RCCW_USM "This signal is feedback of RCCW USM";
CM_ SG_ 378 CF_TirePressure_Unit "Response of Tire Air Pressure Unit";
CM_ SG_ 378 FCA_USM "This signal is feedback of FCA USM";
CM_ SG_ 378 CF_BCA_USM "This signal is feedback of BCA USM";
CM_ SG_ 378 CF_BCW_USM "This signal is feedback of BCW USM";
CM_ SG_ 378 CF_LFA_Opt_USM "USM response for LFA On/Off";
CM_ BO_ 379 "[PE] Periodic and On Event";
CM_ SG_ 379 CF_Gway_ADrLRValue "This signal is used to send information of current setting value of Auto Door Lock option for UMS function.";
CM_ SG_ 379 CF_Gway_WPCRValue "USM response value of WPC(Wireless Phone Chager)";
CM_ SG_ 379 CF_Gway_ADrURValue "This signal is used to send information of current setting value of Auto Door Unlock option for UMS function.";
CM_ SG_ 379 C_WelcomeSysTitleOption "USM Welcome System Title Option";
CM_ SG_ 379 CF_Gway_OTTurnRValue "This signal is used to send information of current setting value of each option for UMS function.";
CM_ SG_ 379 CF_Gway_EscortHLRValue "This signal is used to send information of current setting value of each option for UMS function.";
CM_ SG_ 379 C_UnlockWelcomeRValue "Current setting value for Door Unlock Welcome Setting Option";
CM_ SG_ 379 C_SmartWelcomRValue "Current setting value for Smart Key Welcome Setting Option";
CM_ SG_ 379 C_RearWiperRValue "Feedback Value for Rear wiper in reverse";
CM_ SG_ 379 CF_Gway_TTUnlockRValue "Feedback Value For Two Turn Unlock";
CM_ SG_ 379 CR_Datc_DRSeatWheel_USM_State "SteeringWheel USM State";
CM_ SG_ 379 CR_Datc_DRSeatHeat_USM_State "Driver Seat Heat/Vent USM State";
CM_ BO_ 468 "[PE] Periodic and On Event";
CM_ SG_ 468 Clu_Usm_VoiceVolume "cluster setting status for cluster voice volume";
CM_ SG_ 468 Clu_Usm_AutoinitFuelEconomy "cluster setting for cluster fuel economy";
CM_ SG_ 468 Clu_Usm_WelcomeSound "cluster setting status for cluster welcome sound";
CM_ SG_ 468 CLU_Usm_Roadinfoguide "Cluster setting status for cluster navi road information(DIS Warning)";
CM_ SG_ 468 CLU_Usm_WiperLight "Cluster setting status for cluster wiper&light switch display.";
CM_ SG_ 468 Clu_Usm_TransmissionDisp "Cluster setting status for cluster transmission display";
CM_ SG_ 468 Clu_Usm_FuelEconUnit_km "Cluster setting status for cluster Fuel Economy unit (km)";
CM_ SG_ 468 Clu_Usm_AdasVolume "cluster setting status for ADAS warning volume";
CM_ SG_ 468 Clu_Usm_SubspeedometerDisp "cluster setting status for cluster subspeedometer display for full-TFT LCD cluster";
CM_ SG_ 468 Clu_Usm_FuelEconUnit_mi "Cluster setting status for cluster Fuel Economy Unit (mile)";
CM_ SG_ 468 Clu_Usm_IcyRoadWarn "Cluster setting status for cluster icy road warning";
CM_ SG_ 468 Warn_Sound_AdasVolumeFeedback "this signal for Amp AdasVolume feedback sound";
CM_ BO_ 469 "[PE] Periodic and On Event";
CM_ SG_ 469 Clu_Usm_ServiceReminderMode "Cluster setting status for cluster service reminder mode";
CM_ SG_ 469 Clu_Usm_ServiceReminderSet "Cluster setting status for cluster service reminder set";
CM_ SG_ 469 Clu_Usm_ServiceReminderUnit "Cluster setting status for cluster service reminder unit";
CM_ SG_ 469 Clu_SrvRmndrAlrm "Request of service reminder alarm";
CM_ SG_ 469 Clu_Usm_ServiceUsersetPeriod "Cluster setting status for cluster service reminder user setting period";
CM_ SG_ 469 Clu_Usm_ServiceUsersetDistance "Cluster setting status for cluster service reminder user setting distance";
CM_ SG_ 469 Clu_Usm_ServiceRemainPeriod "Cluster setting status for cluster service reminder remaining period

BIT 14 : 0(+), 1(-)
BIT 0~13 : 0~9999 days";
CM_ SG_ 469 Clu_Usm_ServiceRemainDistance "Cluster setting status for cluster service reminder remaining distance

BIT 17 : 0(+), 1(-)
BIT 0~16 : 0~99999";
CM_ BO_ 1173 "[TP] TP Message";
CM_ BO_ 1191 "[TP] TP Message";
CM_ BO_ 1188 "[TP] TP Message";
CM_ SG_ 1188 Byte0_TCP_4A4 "Contents releted with DMB";
CM_ SG_ 1188 Byte1_Data_4A4 "Contents releted with DMB";
CM_ SG_ 1188 Byte2_Data_4A4 "Contents releted with DMB";
CM_ SG_ 1188 Byte3_Data_4A4 "Contents releted with DMB";
CM_ SG_ 1188 Byte4_Data_4A4 "Contents releted with DMB";
CM_ SG_ 1188 Byte5_Data_4A4 "Contents releted with DMB";
CM_ SG_ 1188 Byte6_Data_4A4 "Contents releted with DMB";
CM_ SG_ 1188 Byte7_Data_4A4 "Contents releted with DMB";
CM_ BO_ 1176 "[TP] TP Message";
CM_ BO_ 1156 "[TP] TP Message";
CM_ BO_ 1178 "[TP] TP Message";
CM_ BO_ 1164 "[TP] TP Message";
CM_ BO_ 1175 "[TP] TP Message";
CM_ BO_ 1190 "[TP] TP Message";
CM_ SG_ 1190 Byte0_TCP_4A6 "Channel Name of XM Satellite Radio";
CM_ SG_ 1190 Byte1_Data_4A6 "Channel Name of XM Satellite Radio";
CM_ SG_ 1190 Byte2_Data_4A6 "Channel Name of XM Satellite Radio";
CM_ SG_ 1190 Byte3_Data_4A6 "Channel Name of XM Satellite Radio";
CM_ SG_ 1190 Byte4_Data_4A6 "Channel Name of XM Satellite Radio";
CM_ SG_ 1190 Byte5_Data_4A6 "Channel Name of XM Satellite Radio";
CM_ SG_ 1190 Byte6_Data_4A6 "Channel Name of XM Satellite Radio";
CM_ SG_ 1190 Byte7_Data_4A6 "Channel Name of XM Satellite Radio";
CM_ BO_ 485 "[PE] Periodic and On Event";
CM_ SG_ 485 Navi_OverSpdAlarm "Command for Alarm of Over speed";
CM_ SG_ 485 Navi_NonSpdTrap "Inform Non Speed-Traps";
CM_ SG_ 485 Navi_WarningZone2 "Inform warning zones";
CM_ SG_ 485 Navi_WarningZone "Inform warning zones";
CM_ SG_ 485 Navi_WarningZone3 "Inform warning zones";
CM_ SG_ 485 Navi_CurveWarning "Information for Warning a curve";
CM_ SG_ 485 Navi_SpdLimit_Type "Information for Type of Speed Limit Warning";
CM_ SG_ 485 Navi_SpdLimit_Unit "Informatin for Unit of Speed Limit Warning";
CM_ SG_ 485 Navi_SpdInfo_Type "Information for Type of Warning related with Speed";
CM_ SG_ 485 Navi_SpdLimit "Information for Speed of Speed Limit Warning";
CM_ BO_ 487 "[PE] Periodic and On Event";
CM_ SG_ 487 NV_EstDist_F "Information for distance to destination or stops (Under decimal point)";
CM_ SG_ 487 NV_EstDist_Unit "Information for distance unit
Unit for NV_EstDist_F & Nv_EstDist_F";
CM_ SG_ 487 NV_EstHour "Information for Estimate Time of Arrival / Necessary Time (Hour)";
CM_ SG_ 487 NV_EstMin "Information for Estimate Time of Arrival / Necessary Time (Minutes)";
CM_ SG_ 487 NV_Azimuth "Information for north azimuth angle
- 48 directions (7.5 deg. Interval)";
CM_ SG_ 487 NV_EstDist_I "Information for distance to destination or stops (Over decimal point)";
CM_ SG_ 487 NV_EstimTimeType "Information for Estimated time type
1. ETA(Estimated Time to Arrive)
2. RTA(Remaining Time to Arrive) - (Necessary Time)";
CM_ SG_ 487 NV_EstimTimeFormat "Information for Time Format of Estimated Arrival Time (12H/24H)";
CM_ SG_ 487 NV_EstPointType "Informatio for Destination / Waypoint Type";
CM_ BO_ 369 "[PE] Periodic and On Event";
CM_ SG_ 369 HU_VehiclePwr "Information for the H/U power status for ADM(Accessary Delay Mode)";
CM_ BO_ 448 "[PE] Periodic and On Event";
CM_ SG_ 448 HU_VRActivity "Information for Acitivity of VR (For All area)";
CM_ SG_ 448 HU_PhoneActivity "Information for Acitivity of Phone Call (For All area)";
CM_ BO_ 371 "[PE] Periodic and On Event";
CM_ SG_ 371 HU_AliveStatus "Information of the status of Head Unit
0x00 : Headunit is booting so, Headunit cant display any state
0x01 : Headunit is normal state, Headunit could display according to MM CAN  command.
0x02 : Headunit is doing their internal process, so Headunit cant communicate with other node.
For CLU/SCC/eCall
-AVN System transmission signal";
CM_ SG_ 371 HU_DistanceUnit "Request to set CLU Distance Unit";
CM_ SG_ 371 HU_TempUnit "Request to set DATC/CLU temperature unit";
CM_ BO_ 458 "[PE] Periodic and On Event";
CM_ SG_ 458 POS_MessageType "Information for Position Message Type";
CM_ SG_ 458 POS_Offset "Information for Position moving distance during Position Age.
-Transmitting Map Matching Moving Distance(m) of Vehicles for 1000ms by this signal";
CM_ SG_ 458 POS_PathIndex "Information for Index of current path: If this number differs from one specified in previous POSITION message, vehicle left the original path.";
CM_ SG_ 458 POS_CyclicCounter "Information for Cyclic counter of this message type: Reconstructor can use this value to detect missing messages.";
CM_ SG_ 458 POS_PositionProbability "Information for Position Probability calculated by Positioning module of Av2HP(ADASIS Version2 Horizon Provider)";
CM_ SG_ 458 POS_PositionIndex "If Av2HP supports positioning alternatives, contains index of this Position Candidate. Candidate 0 is always most probable position candidate, candidate 1 second etc.
If Av2HP does not support positioning alternatives, it will be always 0";
CM_ SG_ 458 POS_PositionAge "Information for Position transmission age.
Time difference between the moment the message is sent and the moment the vehicle position is calculated by the positioning sub-system.";
CM_ SG_ 458 POS_CurrentLane "Information for Current Lane";
CM_ SG_ 458 POS_PositionConfidence "Information for Position Confidence
This field contains Av2HP implementation specific values. Use 0 for highest confidence, 6 for lowest confidence";
CM_ SG_ 458 POS_RangeAvgSpeed "Information for Range camera average speed
(km/h)
This is used when entering the range camera area.";
CM_ SG_ 458 POS_RelativeHeading "Information for Relative Heading";
CM_ BO_ 202 "[EC] On Event and On Change";
CM_ SG_ 202 SEG_MessageType "Information for Segment Message Type for Map Based ADAS.";
CM_ SG_ 202 SEG_Offset "Information for Offset of this Segment from current position";
CM_ SG_ 202 SEG_PathIndex "Information for Index of path of which this segment is part";
CM_ SG_ 202 SEG_CyclicCounter "Information for Cyclic counter of this message type: Reconstructor can use this value to detect missing messages";
CM_ SG_ 202 SEG_Update "Updated information of already transmitted Segment";
CM_ SG_ 202 SEG_Retransmission "Information for Retransmission Flag: If true, this message was sent already at least once before.";
CM_ SG_ 202 SEG_BuiltUpArea "Information for Segment Built up Area Information";
CM_ SG_ 202 SEG_Bridge "Information for Segment Bridge";
CM_ SG_ 202 SEG_Tunnel "Information for Segment Tunnel";
CM_ SG_ 202 SEG_FunctionalRoadClass "Information for Functional Road Class indicates relative importance of the road in the routing network and lower values indicate higher priority";
CM_ SG_ 202 SEG_RelativeProbability "Information for Relative probability of this segment in relation to the previous segment on the same path";
CM_ SG_ 202 SEG_FormOfWay "Information for Link Class Value of Segment";
CM_ SG_ 202 SEG_ComplexIntersection "Information for Segment Complex Intersection";
CM_ SG_ 202 SEG_CalculatedRoute "Information for Calculated Route: MPP/On Route/Off Route(Recalculating Route)
-MPP: Predicted Route(Not the Link from Searched Route). Used if users don¡¯t set Destination. Used with Current Link Information.
-On Route: Link from Searched Route. Used with Current Link Information.
-Off Route: Used when trying to enter the Rest Area. 'SEG_CalculatedRoute', 'SEG_FormOfWay' and 'SEG_FunctionalRoadClass' are used together. But if it is impossible to decide values of 'SEG_FormOfWay' and 'SEG_FunctionalRoadClass', transmitt Unknown Value. If additional Information happens in forward unit distance, retransmitt it by Event.";
CM_ SG_ 202 SEG_SpeedLimitType "Information for Type of Link Speed Limit in effect";
CM_ SG_ 202 SEG_SpeedLimit "Information for Current Link Speed Limit expressed as km/h or mph according to META_SpeedUnit";
CM_ SG_ 202 SEG_DirectionLanes "Information for the Number of lanes in driving direction";
CM_ SG_ 202 SEG_SpeedLimitUnder5 "Current Link Speed Limit of less than 5 kph or mph (according to META_SpeedUnit)

104 KPH = SEG_SpeedLimit (0x15:100KPH) + SEG_SpeedLimitUnder5(0x4:4KPH)";
CM_ BO_ 203 "[EC] On Event and On Change";
CM_ SG_ 203 STUB_MessageType "Information for Stub Message Type";
CM_ SG_ 203 STUB_Offset "Information for Offset of this Stub from current position";
CM_ SG_ 203 STUB_PathIndex "Information for Index of parent path: zero indicates this STUB starts first path in the Horizon.";
CM_ SG_ 203 STUB_CyclicCounter "Information for Cyclic counter of this message type: Reconstructor can use this value to detect missing messages";
CM_ SG_ 203 STUB_Update "Updated information of already transmitted Stub";
CM_ SG_ 203 STUB_Retransmission "Information for Retransmission Flag: If true, this message has been sent at least once before.";
CM_ SG_ 203 STUB_SubPathIndex "Information for Index of new path";
CM_ SG_ 203 STUB_FunctionalRoadClass "Information for Functional Road Class(Unknown, 0~6, N/A) of new path indicates relative importance of the road in the routing network and lower values indicate higher priority.";
CM_ SG_ 203 STUB_RelativeProbability "Information for Relative probability of the new path on the crossing
-Value of Relative Probability about Predicted Proceeding Direction must be always larger than 50";
CM_ SG_ 203 STUB_FormOfWay "Information for New path Form of Way: Link Class";
CM_ SG_ 203 STUB_ComplexIntersection "Information for Complex Intersection";
CM_ SG_ 203 STUB_CalculatedRoute "Information for Calculated Route: MPP/On Route/Off Route(Recalculating Route)";
CM_ SG_ 203 STUB_TurnAngle "Information for Angle of new path relative to parent path";
CM_ SG_ 203 STUB_DirectionLanes "Information for the Number of lanes in driving direction";
CM_ SG_ 203 STUB_RightOfWay "Information for Right of Way";
CM_ SG_ 203 STUB_LastStubAtOffset "Information for Last Stub Flag in parent path: Value true indicates that this STUB message is last one that refers to given parent path and offset; value false says that more STUB messages will be sent";
CM_ BO_ 88 "[EC] On Event and On Change";
CM_ SG_ 88 HU_RVM_CameraOff "This signal is for rear camera view state off.
This signal is only used in rear camera which support 'Driving Assist View Mode'
HU send 0x1 value to RVM when need to turn off the Driving Assist View Mode";
CM_ BO_ 101 "[EC] On Event and On Change";
CM_ SG_ 101 CF_AVN_LFANValueSet "USM request for LFA On/Off";
CM_ SG_ 101 CF_AVN_FCANValueSet "This signal is used for a request to set the value of USM Menus. This signal requests to change status of AEB.";
CM_ SG_ 101 CF_AVN_HDANValueSet "USM request for HDA On/Off";
CM_ SG_ 101 CF_AVN_DAWModeNValueSet "This signal is used for a request to set the value of USM Menus.

If USM setting is changed, the message is sent 3 times.";
CM_ SG_ 101 CF_AVN_SCCDrvModeNValueSet "This signal is used for a request to set the value of USM Menus. This signal requests to change SCC driving mode.
When this signal change, the message is sent 3 times.";
CM_ SG_ 101 CF_AVN_NSCCCamNValueSet "This signal is used for a request to set the value of USM Menus. This signal requests to change status of SCC interlocked with Navi Camera function.

When this signal change, the message is sent 3 times.";
CM_ SG_ 101 CF_AVN_SEANValueSet "Request to set Safe Exit Assist";
CM_ SG_ 101 CF_AVN_BCWNValueSet "Reqeust to set BCW system state";
CM_ SG_ 101 CF_AVN_WarningTimingNValueSet "Reqeust to set Warning Timing state";
CM_ SG_ 101 CF_AVN_ISLWNValueSet "This signal is used for a request to set the value of USM Menus. This signal requests to set ISLW status.
When this signal change, the message is sent 3 times.";
CM_ SG_ 101 CF_AVN_BCANValueSet "Reqeust to set BCA system state";
CM_ SG_ 101 CF_AVN_RCCWNValueSet "Reqeust to set RCCW system state";
CM_ SG_ 101 CF_AVN_BCWSndWanNValueSet "Request to set BCW Sound Warning System state";
CM_ SG_ 101 CF_AVN_NSCCCrvNValueSet "This signal is used for a request to set the value of USM Menus. This signal requests to change status of SCC interlocked with Navi Curve function. When this signal change, the message is sent 3 times.";
CM_ SG_ 101 CF_SccFrVehDptNotiNValueSet "USM request for SCC front vehicle departure notifiaction On/Off";
CM_ SG_ 101 CF_AVN_LkaModeNValueSet "This signal is used for a request to set the value of USM Menus. This signal requests to set LKA control mode.
When this signal change, the message is sent 3 times.";
CM_ SG_ 101 CF_AVN_AdasVolumeNValueSet "Request to set ADAS warning volume level";
CM_ BO_ 102 "[EC] On Event and On Change";
CM_ SG_ 102 CF_AVN_PTGSpeedNValueSet "Setting Value For Power Tailgate Speed";
CM_ SG_ 102 CF_Avn_HAPTICWARNINGNValueSet "USM request for Steering Wheel Haptic Warning";
CM_ BO_ 104 "[EC] On Event and On Change";
CM_ SG_ 104 CF_AVN_CluVoiceVolume "Request to set CLU Volume level";
CM_ SG_ 104 CF_AVN_CluAutoInitFuelEconomy "Request to set CLU auto initailizing fuel economy";
CM_ SG_ 104 CF_AVN_CluWelcomeSnd "Request to set CLU welcome soun";
CM_ SG_ 104 CF_AVN_CluRoadInfoGuide "Request to set CLU road info guidance";
CM_ SG_ 104 CF_AVN_CluWiperLight "Request to set CLU wiper & light mode";
CM_ SG_ 104 CF_AVN_CluTransmissionDisp "Request to set CLU transmission display";
CM_ SG_ 104 CF_AVN_CluServiceReminderSet "Request to set CLU service notification";
CM_ SG_ 104 CF_AVN_CluUserSettingPeriod "Request to set CLU sservice period set by user";
CM_ SG_ 104 CF_AVN_CluFuelEconUnit_km "Cluster setting status for cluster Fuel Economy unit (km)";
CM_ SG_ 104 CF_AVN_CluFuelEconUnit_mi "Cluster setting status for cluster Fuel Economy Unit (mile)";
CM_ SG_ 104 CF_AVN_CluSubspeedOdometerDisp "Request to set CLU Subscale Odometer";
CM_ SG_ 104 CF_AVN_CluUserSettingDistance "Request to set CLU service distance set by user";
CM_ SG_ 104 CF_AVN_EVReset "Request to reset EV Service (0x1 : EV USM Reset)";
CM_ SG_ 104 CF_AVN_CluUSMReset "Request to reset all USM service";
CM_ SG_ 104 CF_AVN_CluServiceReminderReset "Request to reset CLU service reminder";
CM_ SG_ 104 CF_AVN_IcyRoadWarn "Request to set CLU icy road warning";
CM_ SG_ 104 CF_AVN_UnitReset "Request to reset Unit setting";
CM_ BO_ 1165 "[TP] TP Message";
CM_ BO_ 1207 "[TP] TP Message";
CM_ BO_ 1204 "[TP] TP Message";
CM_ SG_ 1204 Byte0_TCP_4B4 "Contents releted with DMB";
CM_ SG_ 1204 Byte1_Data_4B4 "Contents releted with DMB";
CM_ SG_ 1204 Byte2_Data_4B4 "Contents releted with DMB";
CM_ SG_ 1204 Byte3_Data_4B4 "Contents releted with DMB";
CM_ SG_ 1204 Byte4_Data_4B4 "Contents releted with DMB";
CM_ SG_ 1204 Byte5_Data_4B4 "Contents releted with DMB";
CM_ SG_ 1204 Byte6_Data_4B4 "Contents releted with DMB";
CM_ SG_ 1204 Byte7_Data_4B4 "Contents releted with DMB";
CM_ BO_ 1166 "[TP] TP Message";
CM_ BO_ 1157 "[TP] TP Message";
CM_ BO_ 1167 "[TP] TP Message";
CM_ BO_ 1179 "[TP] TP Message";
CM_ BO_ 1168 "[TP] TP Message";
CM_ BO_ 1206 "[TP] TP Message";
CM_ SG_ 1206 Byte0_TCP_4B6 "Channel Name of XM Satellite Radio";
CM_ SG_ 1206 Byte1_Data_4B6 "Channel Name of XM Satellite Radio";
CM_ SG_ 1206 Byte2_Data_4B6 "Channel Name of XM Satellite Radio";
CM_ SG_ 1206 Byte3_Data_4B6 "Channel Name of XM Satellite Radio";
CM_ SG_ 1206 Byte4_Data_4B6 "Channel Name of XM Satellite Radio";
CM_ SG_ 1206 Byte5_Data_4B6 "Channel Name of XM Satellite Radio";
CM_ SG_ 1206 Byte6_Data_4B6 "Channel Name of XM Satellite Radio";
CM_ SG_ 1206 Byte7_Data_4B6 "Channel Name of XM Satellite Radio";
CM_ BO_ 1101 "NM Message";
CM_ BO_ 1096 "NM Message";
CM_ BO_ 1088 "NM Message";
CM_ BO_ 1109 "NM Message";
CM_ BO_ 1099 "NM Message";
BA_DEF_ SG_ "Gatewaysignal" ENUM "No","M-B","B-M","M-C","C-M","M-C-B" ;
BA_DEF_ SG_ "GenSigEnvVarType" ENUM "Int","Float","undef" ;
BA_DEF_ SG_ "GenSigSendType" ENUM "Cyclic","OnWrite","OnWriteWithRepetition","OnChange","OnChangeWithRepetition","IfActive","IfActiveWithRepetition","NoSigSendType" ;
BA_DEF_ SG_ "GenSigStartValue" INT 0 0 ;
BA_DEF_ SG_ "GwSigLatencyTime" INT 0 65535 ;
BA_DEF_ SG_ "GwSigMissingSourceType" ENUM "Undef","OldValue","DefaultValue","InitialValue" ;
BA_DEF_ SG_ "NmNetworkRequest" ENUM "No","Yes" ;
BA_DEF_ SG_ "NmNetworkRequestHoldingTime" INT 0 65535 ;
BA_DEF_ SG_ "Purpose" ENUM "<t.b.d.>","Function","Diagnostic","Development","NM" ;
BA_DEF_ SG_ "SignalCategory" HEX 10 15 ;
BA_DEF_ SG_ "TimeoutValue" STRING ;
BA_DEF_ SG_ "UpdateRateMax" INT 0 0 ;
BA_DEF_ SG_ "UpdateRateMin" INT 0 0 ;
BA_DEF_ SG_ "Validity" ENUM "B+","ACC","IGN1","IGN2" ;
BA_DEF_ BO_ "DiagState" ENUM "No","Yes" ;
BA_DEF_ BO_ "GenMsgCycleTime" INT 0 100000 ;
BA_DEF_ BO_ "GenMsgCycleTimeFast" INT 0 500 ;
BA_DEF_ BO_ "GenMsgDelayTime" INT 0 20 ;
BA_DEF_ BO_ "GenMsgEVName" STRING ;
BA_DEF_ BO_ "GenMsgILSupport" ENUM "No","Yes" ;
BA_DEF_ BO_ "GenMsgNrOfRepetition" INT 0 3 ;
BA_DEF_ BO_ "GenMsgSendType" ENUM "Cyclic","not_used","not_used","not_used","not_used","not_used","not_used","not_used","NoMsgSendType" ;
BA_DEF_ BO_ "GenMsgStartDelayTime" INT 0 2000 ;
BA_DEF_ BO_ "NmMessage" ENUM "No","Yes" ;
BA_DEF_ BO_ "RoutingType" ENUM "<n.a.>","Direct","Indirect" ;
BA_DEF_ BO_ "TpMessage" ENUM "No","Yes" ;
BA_DEF_ BO_ "TpTxIndex" INT 0 255 ;
BA_DEF_ SG_ "SigDescription" STRING ;
BA_DEF_ SG_ "Platform" STRING ;
BA_DEF_ SG_ "SigOldType" ENUM "No","Yes" ;
BA_DEF_REL_ BU_SG_REL_ "GenSigTimeoutTime" INT 0 7000 ;
BA_DEF_DEF_ "Gatewaysignal" "No" ;
BA_DEF_DEF_ "GenSigEnvVarType" "undef" ;
BA_DEF_DEF_ "GenSigSendType" "NoSigSendType" ;
BA_DEF_DEF_ "GenSigStartValue" 0 ;
BA_DEF_DEF_ "GwSigLatencyTime" 40 ;
BA_DEF_DEF_ "GwSigMissingSourceType" "Undef" ;
BA_DEF_DEF_ "NmNetworkRequest" "No" ;
BA_DEF_DEF_ "NmNetworkRequestHoldingTime" 0 ;
BA_DEF_DEF_ "Purpose" "<t.b.d.>" ;
BA_DEF_DEF_ "SignalCategory" 12 ;
BA_DEF_DEF_ "TimeoutValue" "" ;
BA_DEF_DEF_ "UpdateRateMax" 0 ;
BA_DEF_DEF_ "UpdateRateMin" 0 ;
BA_DEF_DEF_ "Validity" "ACC" ;
BA_DEF_DEF_ "DiagState" "No" ;
BA_DEF_DEF_ "GenMsgCycleTime" 0 ;
BA_DEF_DEF_ "GenMsgCycleTimeFast" 0 ;
BA_DEF_DEF_ "GenMsgDelayTime" 20 ;
BA_DEF_DEF_ "GenMsgEVName" "@Signame" ;
BA_DEF_DEF_ "GenMsgILSupport" "Yes" ;
BA_DEF_DEF_ "GenMsgNrOfRepetition" 0 ;
BA_DEF_DEF_ "GenMsgSendType" "NoMsgSendType" ;
BA_DEF_DEF_ "GenMsgStartDelayTime" 0 ;
BA_DEF_DEF_ "NmMessage" "No" ;
BA_DEF_DEF_ "RoutingType" "<n.a.>" ;
BA_DEF_DEF_ "TpMessage" "No" ;
BA_DEF_DEF_ "TpTxIndex" 0 ;
BA_DEF_DEF_ "SigDescription" "" ;
BA_DEF_DEF_ "Platform" "Standard AVN 4.0,Standard Audio 3.0,Premium AVN 3.0" ;
BA_DEF_DEF_ "SigOldType" "No" ;
BA_DEF_DEF_REL_ "GenSigTimeoutTime" 700 ;
BA_ "GenMsgSendType" BO_ 1408 0;
BA_ "GenMsgCycleTime" BO_ 1408 200;
BA_ "Platform" SG_ 1408 AMP_Support_ElecSound "";
BA_ "GenSigStartValue" SG_ 1408 AMP_Support_ElecSound 3;
BA_ "NmNetworkRequest" SG_ 1408 AMP_Support_ElecSound 1;
BA_ "GenMsgSendType" BO_ 362 0;
BA_ "GenMsgCycleTime" BO_ 362 200;
BA_ "GenMsgStartDelayTime" BO_ 362 90;
BA_ "Platform" SG_ 362 C_AV_Tail "";
BA_ "GenSigSendType" SG_ 362 C_AV_Tail 3;
BA_ "GenSigStartValue" SG_ 362 C_AV_Tail 3;
BA_ "Gatewaysignal" SG_ 362 C_AV_Tail 4;
BA_ "TimeoutValue" SG_ 362 C_AV_Tail "0x3";
BA_ "GenMsgNrOfRepetition" BO_ 362 3;
BA_ "GenMsgCycleTimeFast" BO_ 362 40;
BA_REL_ "GenSigTimeoutTime" BU_SG_REL_ AMP SG_ 362 C_IGN1 1500;
BA_REL_ "GenSigTimeoutTime" BU_SG_REL_ CLU SG_ 362 C_IGN1 1500;
BA_REL_ "GenSigTimeoutTime" BU_SG_REL_ H_U SG_ 362 C_IGN1 1500;
BA_REL_ "GenSigTimeoutTime" BU_SG_REL_ TMU SG_ 362 C_IGN1 1500;
BA_ "Platform" SG_ 362 C_IGN1 "";
BA_ "GenSigSendType" SG_ 362 C_IGN1 4;
BA_ "GenSigStartValue" SG_ 362 C_IGN1 3;
BA_ "Gatewaysignal" SG_ 362 C_IGN1 2;
BA_ "NmNetworkRequest" SG_ 362 C_IGN1 1;
BA_ "TimeoutValue" SG_ 362 C_IGN1 "0x3";
BA_ "Validity" SG_ 362 C_IGN1 0;
BA_ "GenMsgSendType" BO_ 491 0;
BA_ "GenMsgCycleTime" BO_ 491 200;
BA_ "Platform" SG_ 491 C_OSMirrorStatus "";
BA_ "GenSigSendType" SG_ 491 C_OSMirrorStatus 3;
BA_ "GenSigStartValue" SG_ 491 C_OSMirrorStatus 3;
BA_ "Gatewaysignal" SG_ 491 C_OSMirrorStatus 2;
BA_ "TimeoutValue" SG_ 491 C_OSMirrorStatus "Old Value";
BA_ "Validity" SG_ 491 C_OSMirrorStatus 0;
BA_ "GenMsgSendType" BO_ 378 0;
BA_ "GenMsgCycleTime" BO_ 378 200;
BA_ "GenMsgStartDelayTime" BO_ 378 40;
BA_REL_ "GenSigTimeoutTime" BU_SG_REL_ CLU SG_ 378 CF_DAW_OptUSM 2000;
BA_REL_ "GenSigTimeoutTime" BU_SG_REL_ H_U SG_ 378 CF_DAW_OptUSM 2000;
BA_ "Platform" SG_ 378 CF_DAW_OptUSM "D-Audio,Integrated AVN1.0 High,Integrated AVN1.0 Mid,Premium AVN 2.0";
BA_ "GenSigSendType" SG_ 378 CF_DAW_OptUSM 3;
BA_ "TimeoutValue" SG_ 378 CF_DAW_OptUSM "Invalid";
BA_ "Validity" SG_ 378 CF_DAW_OptUSM 2;
BA_REL_ "GenSigTimeoutTime" BU_SG_REL_ CLU SG_ 378 FCA_DrvSetState 2000;
BA_REL_ "GenSigTimeoutTime" BU_SG_REL_ H_U SG_ 378 FCA_DrvSetState 2000;
BA_ "Platform" SG_ 378 FCA_DrvSetState "D-Audio,Integrated AVN1.0 High,Integrated AVN1.0 Mid,Premium AVN 2.0";
BA_ "GenSigSendType" SG_ 378 FCA_DrvSetState 3;
BA_ "TimeoutValue" SG_ 378 FCA_DrvSetState "Invalid";
BA_ "Validity" SG_ 378 FCA_DrvSetState 2;
BA_REL_ "GenSigTimeoutTime" BU_SG_REL_ CLU SG_ 378 CF_BCW_DrvSetState 2000;
BA_REL_ "GenSigTimeoutTime" BU_SG_REL_ H_U SG_ 378 CF_BCW_DrvSetState 2000;
BA_ "Platform" SG_ 378 CF_BCW_DrvSetState "D-Audio,Integrated AVN1.0 High,Integrated AVN1.0 Mid,Premium AVN 2.0";
BA_ "GenSigSendType" SG_ 378 CF_BCW_DrvSetState 3;
BA_ "TimeoutValue" SG_ 378 CF_BCW_DrvSetState "Invalid";
BA_ "Validity" SG_ 378 CF_BCW_DrvSetState 2;
BA_REL_ "GenSigTimeoutTime" BU_SG_REL_ CLU SG_ 378 NSCC_Camera_USM 2000;
BA_REL_ "GenSigTimeoutTime" BU_SG_REL_ H_U SG_ 378 NSCC_Camera_USM 2000;
BA_ "Platform" SG_ 378 NSCC_Camera_USM "D-Audio,Integrated AVN1.0 High,Integrated AVN1.0 Mid,Premium AVN 2.0";
BA_ "GenSigSendType" SG_ 378 NSCC_Camera_USM 3;
BA_ "TimeoutValue" SG_ 378 NSCC_Camera_USM "Invalid";
BA_ "Validity" SG_ 378 NSCC_Camera_USM 2;
BA_REL_ "GenSigTimeoutTime" BU_SG_REL_ CLU SG_ 378 CF_SEA_USM 2000;
BA_REL_ "GenSigTimeoutTime" BU_SG_REL_ H_U SG_ 378 CF_SEA_USM 2000;
BA_ "Platform" SG_ 378 CF_SEA_USM "D-Audio,Integrated AVN1.0 High,Integrated AVN1.0 Mid,Premium AVN 2.0";
BA_ "GenSigSendType" SG_ 378 CF_SEA_USM 3;
BA_ "TimeoutValue" SG_ 378 CF_SEA_USM "Invalid";
BA_ "Validity" SG_ 378 CF_SEA_USM 2;
BA_REL_ "GenSigTimeoutTime" BU_SG_REL_ CLU SG_ 378 SCCDrvModeRValue 2000;
BA_REL_ "GenSigTimeoutTime" BU_SG_REL_ H_U SG_ 378 SCCDrvModeRValue 2000;
BA_ "Platform" SG_ 378 SCCDrvModeRValue "D-Audio,Integrated AVN1.0 High,Integrated AVN1.0 Mid,Premium AVN 2.0";
BA_ "GenSigSendType" SG_ 378 SCCDrvModeRValue 3;
BA_ "Gatewaysignal" SG_ 378 SCCDrvModeRValue 4;
BA_ "TimeoutValue" SG_ 378 SCCDrvModeRValue "Invalid";
BA_ "Validity" SG_ 378 SCCDrvModeRValue 2;
BA_REL_ "GenSigTimeoutTime" BU_SG_REL_ CLU SG_ 378 CF_LKA_Opt_USM 2000;
BA_REL_ "GenSigTimeoutTime" BU_SG_REL_ H_U SG_ 378 CF_LKA_Opt_USM 2000;
BA_ "Platform" SG_ 378 CF_LKA_Opt_USM "D-Audio,Integrated AVN1.0 High,Integrated AVN1.0 Mid,Premium AVN 2.0";
BA_ "GenSigSendType" SG_ 378 CF_LKA_Opt_USM 3;
BA_ "TimeoutValue" SG_ 378 CF_LKA_Opt_USM "Invalid";
BA_ "Validity" SG_ 378 CF_LKA_Opt_USM 2;
BA_REL_ "GenSigTimeoutTime" BU_SG_REL_ CLU SG_ 378 NSCC_Curve_USM 2000;
BA_REL_ "GenSigTimeoutTime" BU_SG_REL_ H_U SG_ 378 NSCC_Curve_USM 2000;
BA_ "Platform" SG_ 378 NSCC_Curve_USM "D-Audio,Integrated AVN1.0 High,Integrated AVN1.0 Mid,Premium AVN 2.0";
BA_ "GenSigSendType" SG_ 378 NSCC_Curve_USM 3;
BA_ "TimeoutValue" SG_ 378 NSCC_Curve_USM "Invalid";
BA_ "Validity" SG_ 378 NSCC_Curve_USM 2;
BA_REL_ "GenSigTimeoutTime" BU_SG_REL_ CLU SG_ 378 CF_RCCW_USM 2000;
BA_REL_ "GenSigTimeoutTime" BU_SG_REL_ H_U SG_ 378 CF_RCCW_USM 2000;
BA_ "Platform" SG_ 378 CF_RCCW_USM "D-Audio,Integrated AVN1.0 High,Integrated AVN1.0 Mid,Premium AVN 2.0";
BA_ "GenSigSendType" SG_ 378 CF_RCCW_USM 3;
BA_ "TimeoutValue" SG_ 378 CF_RCCW_USM "Invalid";
BA_ "Validity" SG_ 378 CF_RCCW_USM 2;
BA_REL_ "GenSigTimeoutTime" BU_SG_REL_ CLU SG_ 378 CF_TirePressure_Unit 2000;
BA_REL_ "GenSigTimeoutTime" BU_SG_REL_ H_U SG_ 378 CF_TirePressure_Unit 2000;
BA_ "Platform" SG_ 378 CF_TirePressure_Unit "D-Audio,Integrated AVN1.0 High,Integrated AVN1.0 Mid,Premium AVN 2.0";
BA_ "GenSigSendType" SG_ 378 CF_TirePressure_Unit 3;
BA_ "TimeoutValue" SG_ 378 CF_TirePressure_Unit "Invalid";
BA_ "Validity" SG_ 378 CF_TirePressure_Unit 2;
BA_REL_ "GenSigTimeoutTime" BU_SG_REL_ CLU SG_ 378 FCA_USM 2000;
BA_REL_ "GenSigTimeoutTime" BU_SG_REL_ H_U SG_ 378 FCA_USM 2000;
BA_ "Platform" SG_ 378 FCA_USM "";
BA_ "GenSigSendType" SG_ 378 FCA_USM 3;
BA_ "TimeoutValue" SG_ 378 FCA_USM "Invalid";
BA_ "Validity" SG_ 378 FCA_USM 2;
BA_REL_ "GenSigTimeoutTime" BU_SG_REL_ CLU SG_ 378 CF_BCA_USM 2000;
BA_REL_ "GenSigTimeoutTime" BU_SG_REL_ H_U SG_ 378 CF_BCA_USM 2000;
BA_ "Platform" SG_ 378 CF_BCA_USM "D-Audio,Integrated AVN1.0 High,Integrated AVN1.0 Mid,Premium AVN 2.0";
BA_ "GenSigSendType" SG_ 378 CF_BCA_USM 3;
BA_ "TimeoutValue" SG_ 378 CF_BCA_USM "Invalid";
BA_ "Validity" SG_ 378 CF_BCA_USM 2;
BA_REL_ "GenSigTimeoutTime" BU_SG_REL_ CLU SG_ 378 CF_BCW_USM 2000;
BA_REL_ "GenSigTimeoutTime" BU_SG_REL_ H_U SG_ 378 CF_BCW_USM 2000;
BA_ "Platform" SG_ 378 CF_BCW_USM "D-Audio,Integrated AVN1.0 High,Integrated AVN1.0 Mid,Premium AVN 2.0";
BA_ "GenSigSendType" SG_ 378 CF_BCW_USM 3;
BA_ "TimeoutValue" SG_ 378 CF_BCW_USM "Invalid";
BA_ "Validity" SG_ 378 CF_BCW_USM 2;
BA_REL_ "GenSigTimeoutTime" BU_SG_REL_ CLU SG_ 378 CF_LFA_Opt_USM 2000;
BA_REL_ "GenSigTimeoutTime" BU_SG_REL_ H_U SG_ 378 CF_LFA_Opt_USM 2000;
BA_ "Platform" SG_ 378 CF_LFA_Opt_USM "D-Audio,Integrated AVN1.0 High,Integrated AVN1.0 Mid,Premium AVN 2.0";
BA_ "GenSigSendType" SG_ 378 CF_LFA_Opt_USM 3;
BA_ "TimeoutValue" SG_ 378 CF_LFA_Opt_USM "Invalid";
BA_ "Validity" SG_ 378 CF_LFA_Opt_USM 2;
BA_ "GenMsgSendType" BO_ 379 0;
BA_ "GenMsgCycleTime" BO_ 379 200;
BA_ "GenMsgStartDelayTime" BO_ 379 40;
BA_REL_ "GenSigTimeoutTime" BU_SG_REL_ CLU SG_ 379 CF_Gway_ADrLRValue 2000;
BA_REL_ "GenSigTimeoutTime" BU_SG_REL_ H_U SG_ 379 CF_Gway_ADrLRValue 2000;
BA_ "Platform" SG_ 379 CF_Gway_ADrLRValue "D-Audio,Integrated AVN1.0 High,Integrated AVN1.0 Mid,Premium AVN 2.0";
BA_ "GenSigSendType" SG_ 379 CF_Gway_ADrLRValue 3;
BA_ "Gatewaysignal" SG_ 379 CF_Gway_ADrLRValue 2;
BA_ "TimeoutValue" SG_ 379 CF_Gway_ADrLRValue "Invalid";
BA_ "Validity" SG_ 379 CF_Gway_ADrLRValue 2;
BA_REL_ "GenSigTimeoutTime" BU_SG_REL_ CLU SG_ 379 CF_Gway_WPCRValue 2000;
BA_REL_ "GenSigTimeoutTime" BU_SG_REL_ H_U SG_ 379 CF_Gway_WPCRValue 2000;
BA_ "Platform" SG_ 379 CF_Gway_WPCRValue "D-Audio,Integrated AVN1.0 High,Integrated AVN1.0 Mid,Premium AVN 2.0";
BA_ "GenSigSendType" SG_ 379 CF_Gway_WPCRValue 3;
BA_ "Gatewaysignal" SG_ 379 CF_Gway_WPCRValue 2;
BA_ "TimeoutValue" SG_ 379 CF_Gway_WPCRValue "Invalid";
BA_ "Validity" SG_ 379 CF_Gway_WPCRValue 2;
BA_REL_ "GenSigTimeoutTime" BU_SG_REL_ CLU SG_ 379 CF_Gway_ADrURValue 2000;
BA_REL_ "GenSigTimeoutTime" BU_SG_REL_ H_U SG_ 379 CF_Gway_ADrURValue 2000;
BA_ "Platform" SG_ 379 CF_Gway_ADrURValue "D-Audio,Integrated AVN1.0 High,Integrated AVN1.0 Mid,Premium AVN 2.0";
BA_ "GenSigSendType" SG_ 379 CF_Gway_ADrURValue 3;
BA_ "Gatewaysignal" SG_ 379 CF_Gway_ADrURValue 2;
BA_ "TimeoutValue" SG_ 379 CF_Gway_ADrURValue "Invalid";
BA_ "Validity" SG_ 379 CF_Gway_ADrURValue 2;
BA_REL_ "GenSigTimeoutTime" BU_SG_REL_ CLU SG_ 379 C_WelcomeSysTitleOption 2000;
BA_REL_ "GenSigTimeoutTime" BU_SG_REL_ H_U SG_ 379 C_WelcomeSysTitleOption 2000;
BA_ "Platform" SG_ 379 C_WelcomeSysTitleOption "D-Audio,Integrated AVN1.0 High,Integrated AVN1.0 Mid,Premium AVN 2.0";
BA_ "GenSigSendType" SG_ 379 C_WelcomeSysTitleOption 3;
BA_ "TimeoutValue" SG_ 379 C_WelcomeSysTitleOption "Invalid";
BA_ "Validity" SG_ 379 C_WelcomeSysTitleOption 2;
BA_REL_ "GenSigTimeoutTime" BU_SG_REL_ CLU SG_ 379 CF_Gway_OTTurnRValue 2000;
BA_REL_ "GenSigTimeoutTime" BU_SG_REL_ H_U SG_ 379 CF_Gway_OTTurnRValue 2000;
BA_ "Platform" SG_ 379 CF_Gway_OTTurnRValue "D-Audio,Integrated AVN1.0 High,Integrated AVN1.0 Mid,Premium AVN 2.0";
BA_ "GenSigSendType" SG_ 379 CF_Gway_OTTurnRValue 3;
BA_ "Gatewaysignal" SG_ 379 CF_Gway_OTTurnRValue 2;
BA_ "TimeoutValue" SG_ 379 CF_Gway_OTTurnRValue "Invalid";
BA_ "Validity" SG_ 379 CF_Gway_OTTurnRValue 2;
BA_REL_ "GenSigTimeoutTime" BU_SG_REL_ CLU SG_ 379 CF_Gway_EscortHLRValue 2000;
BA_REL_ "GenSigTimeoutTime" BU_SG_REL_ H_U SG_ 379 CF_Gway_EscortHLRValue 2000;
BA_ "Platform" SG_ 379 CF_Gway_EscortHLRValue "D-Audio,Integrated AVN1.0 High,Integrated AVN1.0 Mid,Premium AVN 2.0";
BA_ "GenSigSendType" SG_ 379 CF_Gway_EscortHLRValue 3;
BA_ "Gatewaysignal" SG_ 379 CF_Gway_EscortHLRValue 2;
BA_ "TimeoutValue" SG_ 379 CF_Gway_EscortHLRValue "Invalid";
BA_ "Validity" SG_ 379 CF_Gway_EscortHLRValue 2;
BA_REL_ "GenSigTimeoutTime" BU_SG_REL_ CLU SG_ 379 C_UnlockWelcomeRValue 2000;
BA_REL_ "GenSigTimeoutTime" BU_SG_REL_ H_U SG_ 379 C_UnlockWelcomeRValue 2000;
BA_ "Platform" SG_ 379 C_UnlockWelcomeRValue "D-Audio,Integrated AVN1.0 High,Integrated AVN1.0 Mid,Premium AVN 2.0";
BA_ "GenSigSendType" SG_ 379 C_UnlockWelcomeRValue 3;
BA_ "TimeoutValue" SG_ 379 C_UnlockWelcomeRValue "Invalid";
BA_ "Validity" SG_ 379 C_UnlockWelcomeRValue 2;
BA_REL_ "GenSigTimeoutTime" BU_SG_REL_ CLU SG_ 379 C_SmartWelcomRValue 2000;
BA_REL_ "GenSigTimeoutTime" BU_SG_REL_ H_U SG_ 379 C_SmartWelcomRValue 2000;
BA_ "Platform" SG_ 379 C_SmartWelcomRValue "D-Audio,Integrated AVN1.0 High,Integrated AVN1.0 Mid,Premium AVN 2.0";
BA_ "GenSigSendType" SG_ 379 C_SmartWelcomRValue 3;
BA_ "TimeoutValue" SG_ 379 C_SmartWelcomRValue "Invalid";
BA_ "Validity" SG_ 379 C_SmartWelcomRValue 2;
BA_REL_ "GenSigTimeoutTime" BU_SG_REL_ CLU SG_ 379 C_RearWiperRValue 2000;
BA_REL_ "GenSigTimeoutTime" BU_SG_REL_ H_U SG_ 379 C_RearWiperRValue 2000;
BA_ "Platform" SG_ 379 C_RearWiperRValue "D-Audio,Integrated AVN1.0 High,Integrated AVN1.0 Mid,Premium AVN 2.0";
BA_ "GenSigSendType" SG_ 379 C_RearWiperRValue 3;
BA_ "TimeoutValue" SG_ 379 C_RearWiperRValue "Invalid";
BA_ "Validity" SG_ 379 C_RearWiperRValue 2;
BA_REL_ "GenSigTimeoutTime" BU_SG_REL_ CLU SG_ 379 CF_Gway_TTUnlockRValue 2000;
BA_REL_ "GenSigTimeoutTime" BU_SG_REL_ H_U SG_ 379 CF_Gway_TTUnlockRValue 2000;
BA_ "Platform" SG_ 379 CF_Gway_TTUnlockRValue "D-Audio,Integrated AVN1.0 High,Integrated AVN1.0 Mid,Premium AVN 2.0";
BA_ "GenSigSendType" SG_ 379 CF_Gway_TTUnlockRValue 3;
BA_ "TimeoutValue" SG_ 379 CF_Gway_TTUnlockRValue "Invalid";
BA_ "Validity" SG_ 379 CF_Gway_TTUnlockRValue 2;
BA_REL_ "GenSigTimeoutTime" BU_SG_REL_ CLU SG_ 379 CR_Datc_DRSeatWheel_USM_State 2000;
BA_REL_ "GenSigTimeoutTime" BU_SG_REL_ H_U SG_ 379 CR_Datc_DRSeatWheel_USM_State 2000;
BA_ "Platform" SG_ 379 CR_Datc_DRSeatWheel_USM_State "D-Audio,Integrated AVN1.0 High,Integrated AVN1.0 Mid,Premium AVN 2.0";
BA_ "GenSigSendType" SG_ 379 CR_Datc_DRSeatWheel_USM_State 3;
BA_ "TimeoutValue" SG_ 379 CR_Datc_DRSeatWheel_USM_State "Invalid";
BA_ "Validity" SG_ 379 CR_Datc_DRSeatWheel_USM_State 2;
BA_REL_ "GenSigTimeoutTime" BU_SG_REL_ CLU SG_ 379 CR_Datc_DRSeatHeat_USM_State 2000;
BA_REL_ "GenSigTimeoutTime" BU_SG_REL_ H_U SG_ 379 CR_Datc_DRSeatHeat_USM_State 2000;
BA_ "Platform" SG_ 379 CR_Datc_DRSeatHeat_USM_State "";
BA_ "GenSigSendType" SG_ 379 CR_Datc_DRSeatHeat_USM_State 3;
BA_ "TimeoutValue" SG_ 379 CR_Datc_DRSeatHeat_USM_State "Invalid";
BA_ "Validity" SG_ 379 CR_Datc_DRSeatHeat_USM_State 2;
BA_ "GenMsgSendType" BO_ 468 0;
BA_ "GenMsgCycleTime" BO_ 468 200;
BA_ "SigDescription" SG_ 468 Clu_Usm_VoiceVolume "USM setting applied AVN (LH~)";
BA_ "Platform" SG_ 468 Clu_Usm_VoiceVolume "";
BA_ "GenSigSendType" SG_ 468 Clu_Usm_VoiceVolume 3;
BA_ "Validity" SG_ 468 Clu_Usm_VoiceVolume 2;
BA_ "SigDescription" SG_ 468 Clu_Usm_AutoinitFuelEconomy "USM setting applied AVN (LH~)";
BA_ "Platform" SG_ 468 Clu_Usm_AutoinitFuelEconomy "";
BA_ "GenSigSendType" SG_ 468 Clu_Usm_AutoinitFuelEconomy 3;
BA_ "Validity" SG_ 468 Clu_Usm_AutoinitFuelEconomy 2;
BA_ "SigDescription" SG_ 468 Clu_Usm_WelcomeSound "USM setting applied AVN (LH~)";
BA_ "Platform" SG_ 468 Clu_Usm_WelcomeSound "";
BA_ "GenSigSendType" SG_ 468 Clu_Usm_WelcomeSound 3;
BA_ "Validity" SG_ 468 Clu_Usm_WelcomeSound 2;
BA_ "SigDescription" SG_ 468 CLU_Usm_Roadinfoguide "USM setting applied AVN (LH~)";
BA_ "Platform" SG_ 468 CLU_Usm_Roadinfoguide "";
BA_ "GenSigSendType" SG_ 468 CLU_Usm_Roadinfoguide 3;
BA_ "Validity" SG_ 468 CLU_Usm_Roadinfoguide 2;
BA_ "SigDescription" SG_ 468 CLU_Usm_WiperLight "USM setting applied AVN (LH~)";
BA_ "Platform" SG_ 468 CLU_Usm_WiperLight "";
BA_ "GenSigSendType" SG_ 468 CLU_Usm_WiperLight 3;
BA_ "Validity" SG_ 468 CLU_Usm_WiperLight 2;
BA_ "SigDescription" SG_ 468 Clu_Usm_TransmissionDisp "USM setting applied AVN (LH~)";
BA_ "Platform" SG_ 468 Clu_Usm_TransmissionDisp "";
BA_ "GenSigSendType" SG_ 468 Clu_Usm_TransmissionDisp 3;
BA_ "Validity" SG_ 468 Clu_Usm_TransmissionDisp 2;
BA_ "SigDescription" SG_ 468 Clu_Usm_FuelEconUnit_km "USM setting applied AVN (LH~)";
BA_ "Platform" SG_ 468 Clu_Usm_FuelEconUnit_km "";
BA_ "GenSigSendType" SG_ 468 Clu_Usm_FuelEconUnit_km 3;
BA_ "Validity" SG_ 468 Clu_Usm_FuelEconUnit_km 2;
BA_ "SigDescription" SG_ 468 Clu_Usm_AdasVolume "USM setting applied AVN (RJ~)";
BA_ "Platform" SG_ 468 Clu_Usm_AdasVolume "";
BA_ "GenSigSendType" SG_ 468 Clu_Usm_AdasVolume 3;
BA_ "Validity" SG_ 468 Clu_Usm_AdasVolume 2;
BA_ "SigDescription" SG_ 468 Clu_Usm_SubspeedometerDisp "USM setting applied AVN (RJ~)";
BA_ "Platform" SG_ 468 Clu_Usm_SubspeedometerDisp "";
BA_ "GenSigSendType" SG_ 468 Clu_Usm_SubspeedometerDisp 3;
BA_ "Validity" SG_ 468 Clu_Usm_SubspeedometerDisp 2;
BA_ "SigDescription" SG_ 468 Clu_Usm_FuelEconUnit_mi "USM setting applied AVN (LH~)";
BA_ "Platform" SG_ 468 Clu_Usm_FuelEconUnit_mi "";
BA_ "GenSigSendType" SG_ 468 Clu_Usm_FuelEconUnit_mi 3;
BA_ "Validity" SG_ 468 Clu_Usm_FuelEconUnit_mi 2;
BA_REL_ "GenSigTimeoutTime" BU_SG_REL_ H_U SG_ 468 Clu_Usm_IcyRoadWarn 2000;
BA_ "Platform" SG_ 468 Clu_Usm_IcyRoadWarn "D-Audio,Integrated AVN1.0 High,Integrated AVN1.0 Mid,Premium AVN 2.0";
BA_ "GenSigSendType" SG_ 468 Clu_Usm_IcyRoadWarn 3;
BA_ "TimeoutValue" SG_ 468 Clu_Usm_IcyRoadWarn "Invalid";
BA_ "Validity" SG_ 468 Clu_Usm_IcyRoadWarn 2;
BA_ "SigDescription" SG_ 468 Warn_Sound_AdasVolumeFeedback "Amp AdasVolume feedback sound";
BA_ "Platform" SG_ 468 Warn_Sound_AdasVolumeFeedback "";
BA_ "GenSigSendType" SG_ 468 Warn_Sound_AdasVolumeFeedback 3;
BA_ "TimeoutValue" SG_ 468 Warn_Sound_AdasVolumeFeedback "0x0";
BA_ "Validity" SG_ 468 Warn_Sound_AdasVolumeFeedback 2;
BA_ "GenMsgSendType" BO_ 469 0;
BA_ "GenMsgCycleTime" BO_ 469 200;
BA_ "SigDescription" SG_ 469 Clu_Usm_ServiceReminderMode "USM setting applied AVN (LH~)";
BA_ "Platform" SG_ 469 Clu_Usm_ServiceReminderMode "";
BA_ "GenSigSendType" SG_ 469 Clu_Usm_ServiceReminderMode 3;
BA_ "Validity" SG_ 469 Clu_Usm_ServiceReminderMode 2;
BA_ "SigDescription" SG_ 469 Clu_Usm_ServiceReminderSet "USM setting applied AVN (LH~)";
BA_ "Platform" SG_ 469 Clu_Usm_ServiceReminderSet "";
BA_ "GenSigSendType" SG_ 469 Clu_Usm_ServiceReminderSet 3;
BA_ "Validity" SG_ 469 Clu_Usm_ServiceReminderSet 2;
BA_ "SigDescription" SG_ 469 Clu_Usm_ServiceReminderUnit "USM setting applied AVN (LH~)";
BA_ "Platform" SG_ 469 Clu_Usm_ServiceReminderUnit "";
BA_ "GenSigSendType" SG_ 469 Clu_Usm_ServiceReminderUnit 3;
BA_ "Validity" SG_ 469 Clu_Usm_ServiceReminderUnit 2;
BA_ "Platform" SG_ 469 Clu_SrvRmndrAlrm "";
BA_ "GenSigSendType" SG_ 469 Clu_SrvRmndrAlrm 3;
BA_ "GenSigStartValue" SG_ 469 Clu_SrvRmndrAlrm 3;
BA_ "TimeoutValue" SG_ 469 Clu_SrvRmndrAlrm "Old value";
BA_ "SigDescription" SG_ 469 Clu_Usm_ServiceUsersetPeriod "USM setting applied AVN (LH~)";
BA_ "Platform" SG_ 469 Clu_Usm_ServiceUsersetPeriod "";
BA_ "GenSigSendType" SG_ 469 Clu_Usm_ServiceUsersetPeriod 3;
BA_ "Validity" SG_ 469 Clu_Usm_ServiceUsersetPeriod 2;
BA_ "SigDescription" SG_ 469 Clu_Usm_ServiceUsersetDistance "USM setting applied AVN (LH~)";
BA_ "Platform" SG_ 469 Clu_Usm_ServiceUsersetDistance "";
BA_ "GenSigSendType" SG_ 469 Clu_Usm_ServiceUsersetDistance 3;
BA_ "Validity" SG_ 469 Clu_Usm_ServiceUsersetDistance 2;
BA_ "SigDescription" SG_ 469 Clu_Usm_ServiceRemainPeriod "USM setting applied AVN (LH~)";
BA_ "Platform" SG_ 469 Clu_Usm_ServiceRemainPeriod "";
BA_ "GenSigSendType" SG_ 469 Clu_Usm_ServiceRemainPeriod 3;
BA_ "Validity" SG_ 469 Clu_Usm_ServiceRemainPeriod 2;
BA_ "SigDescription" SG_ 469 Clu_Usm_ServiceRemainDistance "USM setting applied AVN (LH~)";
BA_ "Platform" SG_ 469 Clu_Usm_ServiceRemainDistance "";
BA_ "GenSigSendType" SG_ 469 Clu_Usm_ServiceRemainDistance 3;
BA_ "Validity" SG_ 469 Clu_Usm_ServiceRemainDistance 2;
BA_ "GenMsgILSupport" BO_ 1173 0;
BA_ "TpMessage" BO_ 1173 1;
BA_ "TpTxIndex" BO_ 1173 2;
BA_REL_ "GenSigTimeoutTime" BU_SG_REL_ H_U SG_ 1173 Byte0_TCP_495 0;
BA_ "Platform" SG_ 1173 Byte0_TCP_495 "";
BA_ "GenMsgILSupport" BO_ 1173 0;
BA_ "TpMessage" BO_ 1173 1;
BA_ "TpTxIndex" BO_ 1173 2;
BA_REL_ "GenSigTimeoutTime" BU_SG_REL_ H_U SG_ 1173 Byte1_Data_495 0;
BA_ "Platform" SG_ 1173 Byte1_Data_495 "";
BA_ "GenMsgILSupport" BO_ 1173 0;
BA_ "TpMessage" BO_ 1173 1;
BA_ "TpTxIndex" BO_ 1173 2;
BA_REL_ "GenSigTimeoutTime" BU_SG_REL_ H_U SG_ 1173 Byte2_Data_495 0;
BA_ "Platform" SG_ 1173 Byte2_Data_495 "";
BA_ "GenMsgILSupport" BO_ 1173 0;
BA_ "TpMessage" BO_ 1173 1;
BA_ "TpTxIndex" BO_ 1173 2;
BA_REL_ "GenSigTimeoutTime" BU_SG_REL_ H_U SG_ 1173 Byte3_Data_495 0;
BA_ "Platform" SG_ 1173 Byte3_Data_495 "";
BA_ "GenMsgILSupport" BO_ 1173 0;
BA_ "TpMessage" BO_ 1173 1;
BA_ "TpTxIndex" BO_ 1173 2;
BA_REL_ "GenSigTimeoutTime" BU_SG_REL_ H_U SG_ 1173 Byte4_Data_495 0;
BA_ "Platform" SG_ 1173 Byte4_Data_495 "";
BA_ "GenMsgILSupport" BO_ 1173 0;
BA_ "TpMessage" BO_ 1173 1;
BA_ "TpTxIndex" BO_ 1173 2;
BA_REL_ "GenSigTimeoutTime" BU_SG_REL_ H_U SG_ 1173 Byte5_Data_495 0;
BA_ "Platform" SG_ 1173 Byte5_Data_495 "";
BA_ "GenMsgILSupport" BO_ 1173 0;
BA_ "TpMessage" BO_ 1173 1;
BA_ "TpTxIndex" BO_ 1173 2;
BA_REL_ "GenSigTimeoutTime" BU_SG_REL_ H_U SG_ 1173 Byte6_Data_495 0;
BA_ "Platform" SG_ 1173 Byte6_Data_495 "";
BA_ "GenMsgILSupport" BO_ 1173 0;
BA_ "TpMessage" BO_ 1173 1;
BA_ "TpTxIndex" BO_ 1173 2;
BA_REL_ "GenSigTimeoutTime" BU_SG_REL_ H_U SG_ 1173 Byte7_Data_495 0;
BA_ "Platform" SG_ 1173 Byte7_Data_495 "";
BA_ "GenMsgILSupport" BO_ 1191 0;
BA_ "TpMessage" BO_ 1191 1;
BA_ "TpTxIndex" BO_ 1191 40;
BA_REL_ "GenSigTimeoutTime" BU_SG_REL_ H_U SG_ 1191 Byte0_TCP_4A7 0;
BA_ "Platform" SG_ 1191 Byte0_TCP_4A7 "";
BA_ "GenMsgILSupport" BO_ 1191 0;
BA_ "TpMessage" BO_ 1191 1;
BA_ "TpTxIndex" BO_ 1191 40;
BA_REL_ "GenSigTimeoutTime" BU_SG_REL_ H_U SG_ 1191 Byte1_Data_4A7 0;
BA_ "Platform" SG_ 1191 Byte1_Data_4A7 "";
BA_ "GenMsgILSupport" BO_ 1191 0;
BA_ "TpMessage" BO_ 1191 1;
BA_ "TpTxIndex" BO_ 1191 40;
BA_REL_ "GenSigTimeoutTime" BU_SG_REL_ H_U SG_ 1191 Byte2_Data_4A7 0;
BA_ "Platform" SG_ 1191 Byte2_Data_4A7 "";
BA_ "GenMsgILSupport" BO_ 1191 0;
BA_ "TpMessage" BO_ 1191 1;
BA_ "TpTxIndex" BO_ 1191 40;
BA_REL_ "GenSigTimeoutTime" BU_SG_REL_ H_U SG_ 1191 Byte3_Data_4A7 0;
BA_ "Platform" SG_ 1191 Byte3_Data_4A7 "";
BA_ "GenMsgILSupport" BO_ 1191 0;
BA_ "TpMessage" BO_ 1191 1;
BA_ "TpTxIndex" BO_ 1191 40;
BA_REL_ "GenSigTimeoutTime" BU_SG_REL_ H_U SG_ 1191 Byte4_Data_4A7 0;
BA_ "Platform" SG_ 1191 Byte4_Data_4A7 "";
BA_ "GenMsgILSupport" BO_ 1191 0;
BA_ "TpMessage" BO_ 1191 1;
BA_ "TpTxIndex" BO_ 1191 40;
BA_REL_ "GenSigTimeoutTime" BU_SG_REL_ H_U SG_ 1191 Byte5_Data_4A7 0;
BA_ "Platform" SG_ 1191 Byte5_Data_4A7 "";
BA_ "GenMsgILSupport" BO_ 1191 0;
BA_ "TpMessage" BO_ 1191 1;
BA_ "TpTxIndex" BO_ 1191 40;
BA_REL_ "GenSigTimeoutTime" BU_SG_REL_ H_U SG_ 1191 Byte6_Data_4A7 0;
BA_ "Platform" SG_ 1191 Byte6_Data_4A7 "";
BA_ "GenMsgILSupport" BO_ 1191 0;
BA_ "TpMessage" BO_ 1191 1;
BA_ "TpTxIndex" BO_ 1191 40;
BA_REL_ "GenSigTimeoutTime" BU_SG_REL_ H_U SG_ 1191 Byte7_Data_4A7 0;
BA_ "Platform" SG_ 1191 Byte7_Data_4A7 "";
BA_ "GenMsgILSupport" BO_ 1188 0;
BA_ "TpMessage" BO_ 1188 1;
BA_ "TpTxIndex" BO_ 1188 3;
BA_REL_ "GenSigTimeoutTime" BU_SG_REL_ H_U SG_ 1188 Byte0_TCP_4A4 0;
BA_ "Platform" SG_ 1188 Byte0_TCP_4A4 "";
BA_ "GenMsgILSupport" BO_ 1188 0;
BA_ "TpMessage" BO_ 1188 1;
BA_ "TpTxIndex" BO_ 1188 3;
BA_REL_ "GenSigTimeoutTime" BU_SG_REL_ H_U SG_ 1188 Byte1_Data_4A4 0;
BA_ "Platform" SG_ 1188 Byte1_Data_4A4 "";
BA_ "GenMsgILSupport" BO_ 1188 0;
BA_ "TpMessage" BO_ 1188 1;
BA_ "TpTxIndex" BO_ 1188 3;
BA_REL_ "GenSigTimeoutTime" BU_SG_REL_ H_U SG_ 1188 Byte2_Data_4A4 0;
BA_ "Platform" SG_ 1188 Byte2_Data_4A4 "";
BA_ "GenMsgILSupport" BO_ 1188 0;
BA_ "TpMessage" BO_ 1188 1;
BA_ "TpTxIndex" BO_ 1188 3;
BA_REL_ "GenSigTimeoutTime" BU_SG_REL_ H_U SG_ 1188 Byte3_Data_4A4 0;
BA_ "Platform" SG_ 1188 Byte3_Data_4A4 "";
BA_ "GenMsgILSupport" BO_ 1188 0;
BA_ "TpMessage" BO_ 1188 1;
BA_ "TpTxIndex" BO_ 1188 3;
BA_REL_ "GenSigTimeoutTime" BU_SG_REL_ H_U SG_ 1188 Byte4_Data_4A4 0;
BA_ "Platform" SG_ 1188 Byte4_Data_4A4 "";
BA_ "GenMsgILSupport" BO_ 1188 0;
BA_ "TpMessage" BO_ 1188 1;
BA_ "TpTxIndex" BO_ 1188 3;
BA_REL_ "GenSigTimeoutTime" BU_SG_REL_ H_U SG_ 1188 Byte5_Data_4A4 0;
BA_ "Platform" SG_ 1188 Byte5_Data_4A4 "";
BA_ "GenMsgILSupport" BO_ 1188 0;
BA_ "TpMessage" BO_ 1188 1;
BA_ "TpTxIndex" BO_ 1188 3;
BA_REL_ "GenSigTimeoutTime" BU_SG_REL_ H_U SG_ 1188 Byte6_Data_4A4 0;
BA_ "Platform" SG_ 1188 Byte6_Data_4A4 "";
BA_ "GenMsgILSupport" BO_ 1188 0;
BA_ "TpMessage" BO_ 1188 1;
BA_ "TpTxIndex" BO_ 1188 3;
BA_REL_ "GenSigTimeoutTime" BU_SG_REL_ H_U SG_ 1188 Byte7_Data_4A4 0;
BA_ "Platform" SG_ 1188 Byte7_Data_4A4 "";
BA_ "GenMsgILSupport" BO_ 1176 0;
BA_ "TpMessage" BO_ 1176 1;
BA_ "TpTxIndex" BO_ 1176 28;
BA_REL_ "GenSigTimeoutTime" BU_SG_REL_ H_U SG_ 1176 Byte0_TCP_498 0;
BA_ "Platform" SG_ 1176 Byte0_TCP_498 "";
BA_ "GenMsgILSupport" BO_ 1176 0;
BA_ "TpMessage" BO_ 1176 1;
BA_ "TpTxIndex" BO_ 1176 28;
BA_REL_ "GenSigTimeoutTime" BU_SG_REL_ H_U SG_ 1176 Byte1_Data_498 0;
BA_ "Platform" SG_ 1176 Byte1_Data_498 "";
BA_ "GenMsgILSupport" BO_ 1176 0;
BA_ "TpMessage" BO_ 1176 1;
BA_ "TpTxIndex" BO_ 1176 28;
BA_REL_ "GenSigTimeoutTime" BU_SG_REL_ H_U SG_ 1176 Byte2_Data_498 0;
BA_ "Platform" SG_ 1176 Byte2_Data_498 "";
BA_ "GenMsgILSupport" BO_ 1176 0;
BA_ "TpMessage" BO_ 1176 1;
BA_ "TpTxIndex" BO_ 1176 28;
BA_REL_ "GenSigTimeoutTime" BU_SG_REL_ H_U SG_ 1176 Byte3_Data_498 0;
BA_ "Platform" SG_ 1176 Byte3_Data_498 "";
BA_ "GenMsgILSupport" BO_ 1176 0;
BA_ "TpMessage" BO_ 1176 1;
BA_ "TpTxIndex" BO_ 1176 28;
BA_REL_ "GenSigTimeoutTime" BU_SG_REL_ H_U SG_ 1176 Byte4_Data_498 0;
BA_ "Platform" SG_ 1176 Byte4_Data_498 "";
BA_ "GenMsgILSupport" BO_ 1176 0;
BA_ "TpMessage" BO_ 1176 1;
BA_ "TpTxIndex" BO_ 1176 28;
BA_REL_ "GenSigTimeoutTime" BU_SG_REL_ H_U SG_ 1176 Byte5_Data_498 0;
BA_ "Platform" SG_ 1176 Byte5_Data_498 "";
BA_ "GenMsgILSupport" BO_ 1176 0;
BA_ "TpMessage" BO_ 1176 1;
BA_ "TpTxIndex" BO_ 1176 28;
BA_REL_ "GenSigTimeoutTime" BU_SG_REL_ H_U SG_ 1176 Byte6_Data_498 0;
BA_ "Platform" SG_ 1176 Byte6_Data_498 "";
BA_ "GenMsgILSupport" BO_ 1176 0;
BA_ "TpMessage" BO_ 1176 1;
BA_ "TpTxIndex" BO_ 1176 28;
BA_REL_ "GenSigTimeoutTime" BU_SG_REL_ H_U SG_ 1176 Byte7_Data_498 0;
BA_ "Platform" SG_ 1176 Byte7_Data_498 "";
BA_ "GenMsgILSupport" BO_ 1156 0;
BA_ "TpMessage" BO_ 1156 1;
BA_ "TpTxIndex" BO_ 1156 10;
BA_REL_ "GenSigTimeoutTime" BU_SG_REL_ H_U SG_ 1156 Byte0_TCP_484 0;
BA_ "Platform" SG_ 1156 Byte0_TCP_484 "";
BA_ "GenMsgILSupport" BO_ 1156 0;
BA_ "TpMessage" BO_ 1156 1;
BA_ "TpTxIndex" BO_ 1156 10;
BA_REL_ "GenSigTimeoutTime" BU_SG_REL_ H_U SG_ 1156 Byte1_Data_484 0;
BA_ "Platform" SG_ 1156 Byte1_Data_484 "";
BA_ "GenMsgILSupport" BO_ 1156 0;
BA_ "TpMessage" BO_ 1156 1;
BA_ "TpTxIndex" BO_ 1156 10;
BA_REL_ "GenSigTimeoutTime" BU_SG_REL_ H_U SG_ 1156 Byte2_Data_484 0;
BA_ "Platform" SG_ 1156 Byte2_Data_484 "";
BA_ "GenMsgILSupport" BO_ 1156 0;
BA_ "TpMessage" BO_ 1156 1;
BA_ "TpTxIndex" BO_ 1156 10;
BA_REL_ "GenSigTimeoutTime" BU_SG_REL_ H_U SG_ 1156 Byte3_Data_484 0;
BA_ "Platform" SG_ 1156 Byte3_Data_484 "";
BA_ "GenMsgILSupport" BO_ 1156 0;
BA_ "TpMessage" BO_ 1156 1;
BA_ "TpTxIndex" BO_ 1156 10;
BA_REL_ "GenSigTimeoutTime" BU_SG_REL_ H_U SG_ 1156 Byte4_Data_484 0;
BA_ "Platform" SG_ 1156 Byte4_Data_484 "";
BA_ "GenMsgILSupport" BO_ 1156 0;
BA_ "TpMessage" BO_ 1156 1;
BA_ "TpTxIndex" BO_ 1156 10;
BA_REL_ "GenSigTimeoutTime" BU_SG_REL_ H_U SG_ 1156 Byte5_Data_484 0;
BA_ "Platform" SG_ 1156 Byte5_Data_484 "";
BA_ "GenMsgILSupport" BO_ 1156 0;
BA_ "TpMessage" BO_ 1156 1;
BA_ "TpTxIndex" BO_ 1156 10;
BA_REL_ "GenSigTimeoutTime" BU_SG_REL_ H_U SG_ 1156 Byte6_Data_484 0;
BA_ "Platform" SG_ 1156 Byte6_Data_484 "";
BA_ "GenMsgILSupport" BO_ 1156 0;
BA_ "TpMessage" BO_ 1156 1;
BA_ "TpTxIndex" BO_ 1156 10;
BA_REL_ "GenSigTimeoutTime" BU_SG_REL_ H_U SG_ 1156 Byte7_Data_484 0;
BA_ "Platform" SG_ 1156 Byte7_Data_484 "";
BA_ "GenMsgILSupport" BO_ 1178 0;
BA_ "TpMessage" BO_ 1178 1;
BA_ "TpTxIndex" BO_ 1178 8;
BA_REL_ "GenSigTimeoutTime" BU_SG_REL_ H_U SG_ 1178 Byte0_TCP_49A 0;
BA_ "Platform" SG_ 1178 Byte0_TCP_49A "";
BA_ "GenMsgILSupport" BO_ 1178 0;
BA_ "TpMessage" BO_ 1178 1;
BA_ "TpTxIndex" BO_ 1178 8;
BA_REL_ "GenSigTimeoutTime" BU_SG_REL_ H_U SG_ 1178 Byte1_Data_49A 0;
BA_ "Platform" SG_ 1178 Byte1_Data_49A "";
BA_ "GenMsgILSupport" BO_ 1178 0;
BA_ "TpMessage" BO_ 1178 1;
BA_ "TpTxIndex" BO_ 1178 8;
BA_REL_ "GenSigTimeoutTime" BU_SG_REL_ H_U SG_ 1178 Byte2_Data_49A 0;
BA_ "Platform" SG_ 1178 Byte2_Data_49A "";
BA_ "GenMsgILSupport" BO_ 1178 0;
BA_ "TpMessage" BO_ 1178 1;
BA_ "TpTxIndex" BO_ 1178 8;
BA_REL_ "GenSigTimeoutTime" BU_SG_REL_ H_U SG_ 1178 Byte3_Data_49A 0;
BA_ "Platform" SG_ 1178 Byte3_Data_49A "";
BA_ "GenMsgILSupport" BO_ 1178 0;
BA_ "TpMessage" BO_ 1178 1;
BA_ "TpTxIndex" BO_ 1178 8;
BA_REL_ "GenSigTimeoutTime" BU_SG_REL_ H_U SG_ 1178 Byte4_Data_49A 0;
BA_ "Platform" SG_ 1178 Byte4_Data_49A "";
BA_ "GenMsgILSupport" BO_ 1178 0;
BA_ "TpMessage" BO_ 1178 1;
BA_ "TpTxIndex" BO_ 1178 8;
BA_REL_ "GenSigTimeoutTime" BU_SG_REL_ H_U SG_ 1178 Byte5_Data_49A 0;
BA_ "Platform" SG_ 1178 Byte5_Data_49A "";
BA_ "GenMsgILSupport" BO_ 1178 0;
BA_ "TpMessage" BO_ 1178 1;
BA_ "TpTxIndex" BO_ 1178 8;
BA_REL_ "GenSigTimeoutTime" BU_SG_REL_ H_U SG_ 1178 Byte6_Data_49A 0;
BA_ "Platform" SG_ 1178 Byte6_Data_49A "";
BA_ "GenMsgILSupport" BO_ 1178 0;
BA_ "TpMessage" BO_ 1178 1;
BA_ "TpTxIndex" BO_ 1178 8;
BA_REL_ "GenSigTimeoutTime" BU_SG_REL_ H_U SG_ 1178 Byte7_Data_49A 0;
BA_ "Platform" SG_ 1178 Byte7_Data_49A "";
BA_ "GenMsgILSupport" BO_ 1164 0;
BA_ "TpMessage" BO_ 1164 1;
BA_ "TpTxIndex" BO_ 1164 9;
BA_REL_ "GenSigTimeoutTime" BU_SG_REL_ H_U SG_ 1164 Byte0_TCP_48C 0;
BA_ "Platform" SG_ 1164 Byte0_TCP_48C "";
BA_ "GenMsgILSupport" BO_ 1164 0;
BA_ "TpMessage" BO_ 1164 1;
BA_ "TpTxIndex" BO_ 1164 9;
BA_REL_ "GenSigTimeoutTime" BU_SG_REL_ H_U SG_ 1164 Byte1_Data_48C 0;
BA_ "Platform" SG_ 1164 Byte1_Data_48C "";
BA_ "GenMsgILSupport" BO_ 1164 0;
BA_ "TpMessage" BO_ 1164 1;
BA_ "TpTxIndex" BO_ 1164 9;
BA_REL_ "GenSigTimeoutTime" BU_SG_REL_ H_U SG_ 1164 Byte2_Data_48C 0;
BA_ "Platform" SG_ 1164 Byte2_Data_48C "";
BA_ "GenMsgILSupport" BO_ 1164 0;
BA_ "TpMessage" BO_ 1164 1;
BA_ "TpTxIndex" BO_ 1164 9;
BA_REL_ "GenSigTimeoutTime" BU_SG_REL_ H_U SG_ 1164 Byte3_Data_48C 0;
BA_ "Platform" SG_ 1164 Byte3_Data_48C "";
BA_ "GenMsgILSupport" BO_ 1164 0;
BA_ "TpMessage" BO_ 1164 1;
BA_ "TpTxIndex" BO_ 1164 9;
BA_REL_ "GenSigTimeoutTime" BU_SG_REL_ H_U SG_ 1164 Byte4_Data_48C 0;
BA_ "Platform" SG_ 1164 Byte4_Data_48C "";
BA_ "GenMsgILSupport" BO_ 1164 0;
BA_ "TpMessage" BO_ 1164 1;
BA_ "TpTxIndex" BO_ 1164 9;
BA_REL_ "GenSigTimeoutTime" BU_SG_REL_ H_U SG_ 1164 Byte5_Data_48C 0;
BA_ "Platform" SG_ 1164 Byte5_Data_48C "";
BA_ "GenMsgILSupport" BO_ 1164 0;
BA_ "TpMessage" BO_ 1164 1;
BA_ "TpTxIndex" BO_ 1164 9;
BA_REL_ "GenSigTimeoutTime" BU_SG_REL_ H_U SG_ 1164 Byte6_Data_48C 0;
BA_ "Platform" SG_ 1164 Byte6_Data_48C "";
BA_ "GenMsgILSupport" BO_ 1164 0;
BA_ "TpMessage" BO_ 1164 1;
BA_ "TpTxIndex" BO_ 1164 9;
BA_REL_ "GenSigTimeoutTime" BU_SG_REL_ H_U SG_ 1164 Byte7_Data_48C 0;
BA_ "Platform" SG_ 1164 Byte7_Data_48C "";
BA_ "GenMsgILSupport" BO_ 1175 0;
BA_ "TpMessage" BO_ 1175 1;
BA_ "TpTxIndex" BO_ 1175 14;
BA_REL_ "GenSigTimeoutTime" BU_SG_REL_ H_U SG_ 1175 Byte0_TCP_497 0;
BA_ "Platform" SG_ 1175 Byte0_TCP_497 "";
BA_ "GenMsgILSupport" BO_ 1175 0;
BA_ "TpMessage" BO_ 1175 1;
BA_ "TpTxIndex" BO_ 1175 14;
BA_REL_ "GenSigTimeoutTime" BU_SG_REL_ H_U SG_ 1175 Byte1_Data_497 0;
BA_ "Platform" SG_ 1175 Byte1_Data_497 "";
BA_ "GenMsgILSupport" BO_ 1175 0;
BA_ "TpMessage" BO_ 1175 1;
BA_ "TpTxIndex" BO_ 1175 14;
BA_REL_ "GenSigTimeoutTime" BU_SG_REL_ H_U SG_ 1175 Byte2_Data_497 0;
BA_ "Platform" SG_ 1175 Byte2_Data_497 "";
BA_ "GenMsgILSupport" BO_ 1175 0;
BA_ "TpMessage" BO_ 1175 1;
BA_ "TpTxIndex" BO_ 1175 14;
BA_REL_ "GenSigTimeoutTime" BU_SG_REL_ H_U SG_ 1175 Byte3_Data_497 0;
BA_ "Platform" SG_ 1175 Byte3_Data_497 "";
BA_ "GenMsgILSupport" BO_ 1175 0;
BA_ "TpMessage" BO_ 1175 1;
BA_ "TpTxIndex" BO_ 1175 14;
BA_REL_ "GenSigTimeoutTime" BU_SG_REL_ H_U SG_ 1175 Byte4_Data_497 0;
BA_ "Platform" SG_ 1175 Byte4_Data_497 "";
BA_ "GenMsgILSupport" BO_ 1175 0;
BA_ "TpMessage" BO_ 1175 1;
BA_ "TpTxIndex" BO_ 1175 14;
BA_REL_ "GenSigTimeoutTime" BU_SG_REL_ H_U SG_ 1175 Byte5_Data_497 0;
BA_ "Platform" SG_ 1175 Byte5_Data_497 "";
BA_ "GenMsgILSupport" BO_ 1175 0;
BA_ "TpMessage" BO_ 1175 1;
BA_ "TpTxIndex" BO_ 1175 14;
BA_REL_ "GenSigTimeoutTime" BU_SG_REL_ H_U SG_ 1175 Byte6_Data_497 0;
BA_ "Platform" SG_ 1175 Byte6_Data_497 "";
BA_ "GenMsgILSupport" BO_ 1175 0;
BA_ "TpMessage" BO_ 1175 1;
BA_ "TpTxIndex" BO_ 1175 14;
BA_REL_ "GenSigTimeoutTime" BU_SG_REL_ H_U SG_ 1175 Byte7_Data_497 0;
BA_ "Platform" SG_ 1175 Byte7_Data_497 "";
BA_ "GenMsgILSupport" BO_ 1190 0;
BA_ "TpMessage" BO_ 1190 1;
BA_ "TpTxIndex" BO_ 1190 4;
BA_REL_ "GenSigTimeoutTime" BU_SG_REL_ H_U SG_ 1190 Byte0_TCP_4A6 0;
BA_ "Platform" SG_ 1190 Byte0_TCP_4A6 "";
BA_ "GenMsgILSupport" BO_ 1190 0;
BA_ "TpMessage" BO_ 1190 1;
BA_ "TpTxIndex" BO_ 1190 4;
BA_REL_ "GenSigTimeoutTime" BU_SG_REL_ H_U SG_ 1190 Byte1_Data_4A6 0;
BA_ "Platform" SG_ 1190 Byte1_Data_4A6 "";
BA_ "GenMsgILSupport" BO_ 1190 0;
BA_ "TpMessage" BO_ 1190 1;
BA_ "TpTxIndex" BO_ 1190 4;
BA_REL_ "GenSigTimeoutTime" BU_SG_REL_ H_U SG_ 1190 Byte2_Data_4A6 0;
BA_ "Platform" SG_ 1190 Byte2_Data_4A6 "";
BA_ "GenMsgILSupport" BO_ 1190 0;
BA_ "TpMessage" BO_ 1190 1;
BA_ "TpTxIndex" BO_ 1190 4;
BA_REL_ "GenSigTimeoutTime" BU_SG_REL_ H_U SG_ 1190 Byte3_Data_4A6 0;
BA_ "Platform" SG_ 1190 Byte3_Data_4A6 "";
BA_ "GenMsgILSupport" BO_ 1190 0;
BA_ "TpMessage" BO_ 1190 1;
BA_ "TpTxIndex" BO_ 1190 4;
BA_REL_ "GenSigTimeoutTime" BU_SG_REL_ H_U SG_ 1190 Byte4_Data_4A6 0;
BA_ "Platform" SG_ 1190 Byte4_Data_4A6 "";
BA_ "GenMsgILSupport" BO_ 1190 0;
BA_ "TpMessage" BO_ 1190 1;
BA_ "TpTxIndex" BO_ 1190 4;
BA_REL_ "GenSigTimeoutTime" BU_SG_REL_ H_U SG_ 1190 Byte5_Data_4A6 0;
BA_ "Platform" SG_ 1190 Byte5_Data_4A6 "";
BA_ "GenMsgILSupport" BO_ 1190 0;
BA_ "TpMessage" BO_ 1190 1;
BA_ "TpTxIndex" BO_ 1190 4;
BA_REL_ "GenSigTimeoutTime" BU_SG_REL_ H_U SG_ 1190 Byte6_Data_4A6 0;
BA_ "Platform" SG_ 1190 Byte6_Data_4A6 "";
BA_ "GenMsgILSupport" BO_ 1190 0;
BA_ "TpMessage" BO_ 1190 1;
BA_ "TpTxIndex" BO_ 1190 4;
BA_REL_ "GenSigTimeoutTime" BU_SG_REL_ H_U SG_ 1190 Byte7_Data_4A6 0;
BA_ "Platform" SG_ 1190 Byte7_Data_4A6 "";
BA_ "GenMsgSendType" BO_ 485 0;
BA_ "GenMsgCycleTime" BO_ 485 200;
BA_ "GenMsgCycleTimeFast" BO_ 485 40;
BA_ "GenMsgNrOfRepetition" BO_ 485 3;
BA_ "GenMsgStartDelayTime" BO_ 485 140;
BA_ "Platform" SG_ 485 Navi_OverSpdAlarm "";
BA_ "GenSigSendType" SG_ 485 Navi_OverSpdAlarm 4;
BA_ "GenSigStartValue" SG_ 485 Navi_OverSpdAlarm 3;
BA_ "Gatewaysignal" SG_ 485 Navi_OverSpdAlarm 1;
BA_ "NmNetworkRequest" SG_ 485 Navi_OverSpdAlarm 1;
BA_ "SignalCategory" SG_ 485 Navi_OverSpdAlarm 13;
BA_ "TimeoutValue" SG_ 485 Navi_OverSpdAlarm "Old value";
BA_ "Platform" SG_ 485 Navi_NonSpdTrap "";
BA_ "GenSigSendType" SG_ 485 Navi_NonSpdTrap 3;
BA_ "GenSigStartValue" SG_ 485 Navi_NonSpdTrap 31;
BA_ "TimeoutValue" SG_ 485 Navi_NonSpdTrap "Old Value";
BA_ "Platform" SG_ 485 Navi_WarningZone2 "";
BA_ "GenSigSendType" SG_ 485 Navi_WarningZone2 3;
BA_ "GenSigStartValue" SG_ 485 Navi_WarningZone2 31;
BA_ "TimeoutValue" SG_ 485 Navi_WarningZone2 "Old Value";
BA_ "Platform" SG_ 485 Navi_WarningZone "";
BA_ "GenSigSendType" SG_ 485 Navi_WarningZone 3;
BA_ "GenSigStartValue" SG_ 485 Navi_WarningZone 15;
BA_ "TimeoutValue" SG_ 485 Navi_WarningZone "Old Value";
BA_ "Platform" SG_ 485 Navi_WarningZone3 "";
BA_ "GenSigSendType" SG_ 485 Navi_WarningZone3 3;
BA_ "GenSigStartValue" SG_ 485 Navi_WarningZone3 15;
BA_ "TimeoutValue" SG_ 485 Navi_WarningZone3 "Old Value";
BA_ "Platform" SG_ 485 Navi_CurveWarning "";
BA_ "GenSigSendType" SG_ 485 Navi_CurveWarning 4;
BA_ "GenSigStartValue" SG_ 485 Navi_CurveWarning 15;
BA_ "NmNetworkRequest" SG_ 485 Navi_CurveWarning 1;
BA_ "SignalCategory" SG_ 485 Navi_CurveWarning 13;
BA_ "TimeoutValue" SG_ 485 Navi_CurveWarning "Old Value";
BA_ "Platform" SG_ 485 Navi_SpdLimit_Type "";
BA_ "GenSigSendType" SG_ 485 Navi_SpdLimit_Type 4;
BA_ "GenSigStartValue" SG_ 485 Navi_SpdLimit_Type 3;
BA_ "NmNetworkRequest" SG_ 485 Navi_SpdLimit_Type 1;
BA_ "TimeoutValue" SG_ 485 Navi_SpdLimit_Type "Old Value";
BA_ "Platform" SG_ 485 Navi_SpdLimit_Unit "";
BA_ "GenSigSendType" SG_ 485 Navi_SpdLimit_Unit 4;
BA_ "GenSigStartValue" SG_ 485 Navi_SpdLimit_Unit 3;
BA_ "NmNetworkRequest" SG_ 485 Navi_SpdLimit_Unit 1;
BA_ "TimeoutValue" SG_ 485 Navi_SpdLimit_Unit "Old Value";
BA_ "SigDescription" SG_ 485 Navi_SpdInfo_Type "±ÇÀå : °í±ÞÇü 2.0, Ç¥ÁØÇü 4.5(DH)ÀÇ ¼öÃâÇâ°ú ÇâÈÄ ÇÃ·§ÆûÀº Navi_FixedSpdTrap, Navi_MobileSpdTrap, Navi)SpdRedlightTrap ½ÅÈ£ ´ë½Å ÀÌ ½ÅÈ£ »ç¿ë.";
BA_ "Platform" SG_ 485 Navi_SpdInfo_Type "";
BA_ "GenSigSendType" SG_ 485 Navi_SpdInfo_Type 3;
BA_ "GenSigStartValue" SG_ 485 Navi_SpdInfo_Type 15;
BA_ "TimeoutValue" SG_ 485 Navi_SpdInfo_Type "Old Value";
BA_ "Platform" SG_ 485 Navi_SpdLimit "";
BA_ "GenSigSendType" SG_ 485 Navi_SpdLimit 4;
BA_ "GenSigStartValue" SG_ 485 Navi_SpdLimit 255;
BA_ "NmNetworkRequest" SG_ 485 Navi_SpdLimit 1;
BA_ "TimeoutValue" SG_ 485 Navi_SpdLimit "Old Value";
BA_ "GenMsgSendType" BO_ 487 0;
BA_ "GenMsgCycleTime" BO_ 487 200;
BA_ "GenMsgStartDelayTime" BO_ 487 170;
BA_ "Platform" SG_ 487 NV_EstDist_F "";
BA_ "GenSigSendType" SG_ 487 NV_EstDist_F 3;
BA_ "GenSigStartValue" SG_ 487 NV_EstDist_F 15;
BA_ "Platform" SG_ 487 NV_EstDist_Unit "";
BA_ "GenSigSendType" SG_ 487 NV_EstDist_Unit 3;
BA_ "GenSigStartValue" SG_ 487 NV_EstDist_Unit 15;
BA_ "Platform" SG_ 487 NV_EstHour "";
BA_ "GenSigSendType" SG_ 487 NV_EstHour 3;
BA_ "GenSigStartValue" SG_ 487 NV_EstHour 255;
BA_ "Platform" SG_ 487 NV_EstMin "";
BA_ "GenSigSendType" SG_ 487 NV_EstMin 3;
BA_ "GenSigStartValue" SG_ 487 NV_EstMin 255;
BA_ "Platform" SG_ 487 NV_Azimuth "";
BA_ "GenSigSendType" SG_ 487 NV_Azimuth 3;
BA_ "GenSigStartValue" SG_ 487 NV_Azimuth 255;
BA_ "Platform" SG_ 487 NV_EstDist_I "";
BA_ "GenSigSendType" SG_ 487 NV_EstDist_I 3;
BA_ "GenSigStartValue" SG_ 487 NV_EstDist_I 65535;
BA_ "Platform" SG_ 487 NV_EstimTimeType "";
BA_ "GenSigSendType" SG_ 487 NV_EstimTimeType 3;
BA_ "GenSigStartValue" SG_ 487 NV_EstimTimeType 3;
BA_ "SignalCategory" SG_ 487 NV_EstimTimeType 13;
BA_ "TimeoutValue" SG_ 487 NV_EstimTimeType "Old Value";
BA_ "Platform" SG_ 487 NV_EstimTimeFormat "";
BA_ "GenSigSendType" SG_ 487 NV_EstimTimeFormat 3;
BA_ "GenSigStartValue" SG_ 487 NV_EstimTimeFormat 3;
BA_ "TimeoutValue" SG_ 487 NV_EstimTimeFormat "Old Value";
BA_ "Platform" SG_ 487 NV_EstPointType "";
BA_ "GenSigSendType" SG_ 487 NV_EstPointType 3;
BA_ "GenSigStartValue" SG_ 487 NV_EstPointType 15;
BA_ "GenMsgSendType" BO_ 369 0;
BA_ "GenMsgCycleTime" BO_ 369 200;
BA_ "GenMsgCycleTimeFast" BO_ 369 40;
BA_ "GenMsgNrOfRepetition" BO_ 369 3;
BA_ "GenMsgStartDelayTime" BO_ 369 120;
BA_ "SigDescription" SG_ 369 HU_VehiclePwr "[Default Value]
0x0
[KBD Wake-up Condition]
Door Open/Door Unlock/Welcome On (Pre-booting from Vehicle interrupt)";
BA_ "Platform" SG_ 369 HU_VehiclePwr "";
BA_ "GenSigSendType" SG_ 369 HU_VehiclePwr 4;
BA_ "NmNetworkRequest" SG_ 369 HU_VehiclePwr 1;
BA_ "NmNetworkRequestHoldingTime" SG_ 369 HU_VehiclePwr 5;
BA_ "TimeoutValue" SG_ 369 HU_VehiclePwr "0x0";
BA_ "Validity" SG_ 369 HU_VehiclePwr 0;
BA_ "GenMsgSendType" BO_ 448 0;
BA_ "GenMsgCycleTime" BO_ 448 1000;
BA_ "GenMsgCycleTimeFast" BO_ 448 40;
BA_ "GenMsgNrOfRepetition" BO_ 448 3;
BA_ "GenMsgStartDelayTime" BO_ 448 220;
BA_REL_ "GenSigTimeoutTime" BU_SG_REL_ CGW SG_ 448 HU_VRActivity 3500;
BA_REL_ "GenSigTimeoutTime" BU_SG_REL_ CLU SG_ 448 HU_VRActivity 3500;
BA_REL_ "GenSigTimeoutTime" BU_SG_REL_ TMU SG_ 448 HU_VRActivity 3500;
BA_ "Platform" SG_ 448 HU_VRActivity "";
BA_ "GenSigSendType" SG_ 448 HU_VRActivity 4;
BA_ "GenSigStartValue" SG_ 448 HU_VRActivity 3;
BA_ "Gatewaysignal" SG_ 448 HU_VRActivity 3;
BA_ "NmNetworkRequest" SG_ 448 HU_VRActivity 1;
BA_ "SignalCategory" SG_ 448 HU_VRActivity 13;
BA_ "TimeoutValue" SG_ 448 HU_VRActivity "Old Value";
BA_REL_ "GenSigTimeoutTime" BU_SG_REL_ CGW SG_ 448 HU_PhoneActivity 3500;
BA_REL_ "GenSigTimeoutTime" BU_SG_REL_ CLU SG_ 448 HU_PhoneActivity 3500;
BA_REL_ "GenSigTimeoutTime" BU_SG_REL_ TMU SG_ 448 HU_PhoneActivity 3500;
BA_ "Platform" SG_ 448 HU_PhoneActivity "";
BA_ "GenSigSendType" SG_ 448 HU_PhoneActivity 4;
BA_ "GenSigStartValue" SG_ 448 HU_PhoneActivity 3;
BA_ "Gatewaysignal" SG_ 448 HU_PhoneActivity 3;
BA_ "NmNetworkRequest" SG_ 448 HU_PhoneActivity 1;
BA_ "SignalCategory" SG_ 448 HU_PhoneActivity 13;
BA_ "TimeoutValue" SG_ 448 HU_PhoneActivity "Old Value";
BA_ "GenMsgSendType" BO_ 371 0;
BA_ "GenMsgCycleTime" BO_ 371 200;
BA_ "GenMsgCycleTimeFast" BO_ 371 40;
BA_ "GenMsgNrOfRepetition" BO_ 371 3;
BA_ "GenMsgStartDelayTime" BO_ 371 140;
BA_ "Platform" SG_ 371 HU_AliveStatus "";
BA_ "GenSigSendType" SG_ 371 HU_AliveStatus 4;
BA_ "GenSigStartValue" SG_ 371 HU_AliveStatus 3;
BA_ "NmNetworkRequest" SG_ 371 HU_AliveStatus 1;
BA_ "TimeoutValue" SG_ 371 HU_AliveStatus "0x00";
BA_ "Validity" SG_ 371 HU_AliveStatus 0;
BA_ "SigDescription" SG_ 371 HU_DistanceUnit "J.H.J. DR Request";
BA_ "Platform" SG_ 371 HU_DistanceUnit "";
BA_ "GenSigSendType" SG_ 371 HU_DistanceUnit 4;
BA_ "GenSigStartValue" SG_ 371 HU_DistanceUnit 3;
BA_ "NmNetworkRequest" SG_ 371 HU_DistanceUnit 1;
BA_ "TimeoutValue" SG_ 371 HU_DistanceUnit "Old";
BA_ "Platform" SG_ 371 HU_TempUnit "DIS 2,Integrated AVN1.0 High,Integrated AVN1.0 Mid,Premium AVN 2.0";
BA_ "GenSigSendType" SG_ 371 HU_TempUnit 3;
BA_ "GenSigStartValue" SG_ 371 HU_TempUnit 3;
BA_ "TimeoutValue" SG_ 371 HU_TempUnit "Invalid";
BA_ "GenMsgSendType" BO_ 458 0;
BA_ "GenMsgCycleTime" BO_ 458 1000;
BA_REL_ "GenSigTimeoutTime" BU_SG_REL_ CGW SG_ 458 POS_MessageType 3500;
BA_REL_ "GenSigTimeoutTime" BU_SG_REL_ CLU SG_ 458 POS_MessageType 3500;
BA_ "SigDescription" SG_ 458 POS_MessageType "[Default Value]
0x1";
BA_ "Platform" SG_ 458 POS_MessageType "";
BA_ "GenSigSendType" SG_ 458 POS_MessageType 3;
BA_ "GenSigStartValue" SG_ 458 POS_MessageType 7;
BA_ "TimeoutValue" SG_ 458 POS_MessageType "Invalid";
BA_ "Validity" SG_ 458 POS_MessageType 2;
BA_REL_ "GenSigTimeoutTime" BU_SG_REL_ CGW SG_ 458 POS_Offset 3500;
BA_REL_ "GenSigTimeoutTime" BU_SG_REL_ CLU SG_ 458 POS_Offset 3500;
BA_ "SigDescription" SG_ 458 POS_Offset "[Default Value]
0x1FFF";
BA_ "Platform" SG_ 458 POS_Offset "";
BA_ "GenSigSendType" SG_ 458 POS_Offset 3;
BA_ "GenSigStartValue" SG_ 458 POS_Offset 8191;
BA_ "TimeoutValue" SG_ 458 POS_Offset "Invalid";
BA_ "Validity" SG_ 458 POS_Offset 2;
BA_REL_ "GenSigTimeoutTime" BU_SG_REL_ CGW SG_ 458 POS_PathIndex 3500;
BA_REL_ "GenSigTimeoutTime" BU_SG_REL_ CLU SG_ 458 POS_PathIndex 3500;
BA_ "SigDescription" SG_ 458 POS_PathIndex "[Default Value]
0x0";
BA_ "Platform" SG_ 458 POS_PathIndex "";
BA_ "GenSigSendType" SG_ 458 POS_PathIndex 3;
BA_ "TimeoutValue" SG_ 458 POS_PathIndex "Old Value";
BA_ "Validity" SG_ 458 POS_PathIndex 2;
BA_REL_ "GenSigTimeoutTime" BU_SG_REL_ CGW SG_ 458 POS_CyclicCounter 3500;
BA_REL_ "GenSigTimeoutTime" BU_SG_REL_ CLU SG_ 458 POS_CyclicCounter 3500;
BA_ "SigDescription" SG_ 458 POS_CyclicCounter "[Default Value]
0x0";
BA_ "Platform" SG_ 458 POS_CyclicCounter "";
BA_ "GenSigSendType" SG_ 458 POS_CyclicCounter 3;
BA_ "TimeoutValue" SG_ 458 POS_CyclicCounter "Old Value";
BA_ "Validity" SG_ 458 POS_CyclicCounter 2;
BA_REL_ "GenSigTimeoutTime" BU_SG_REL_ CGW SG_ 458 POS_PositionProbability 3500;
BA_REL_ "GenSigTimeoutTime" BU_SG_REL_ CLU SG_ 458 POS_PositionProbability 3500;
BA_ "SigDescription" SG_ 458 POS_PositionProbability "[Default Value]
0x1F";
BA_ "Platform" SG_ 458 POS_PositionProbability "";
BA_ "GenSigSendType" SG_ 458 POS_PositionProbability 3;
BA_ "GenSigStartValue" SG_ 458 POS_PositionProbability 31;
BA_ "TimeoutValue" SG_ 458 POS_PositionProbability "Invalid";
BA_ "Validity" SG_ 458 POS_PositionProbability 2;
BA_REL_ "GenSigTimeoutTime" BU_SG_REL_ CGW SG_ 458 POS_PositionIndex 3500;
BA_REL_ "GenSigTimeoutTime" BU_SG_REL_ CLU SG_ 458 POS_PositionIndex 3500;
BA_ "SigDescription" SG_ 458 POS_PositionIndex "[Default Value]
0x3";
BA_ "Platform" SG_ 458 POS_PositionIndex "";
BA_ "GenSigSendType" SG_ 458 POS_PositionIndex 3;
BA_ "GenSigStartValue" SG_ 458 POS_PositionIndex 3;
BA_ "TimeoutValue" SG_ 458 POS_PositionIndex "Invalid";
BA_ "Validity" SG_ 458 POS_PositionIndex 2;
BA_REL_ "GenSigTimeoutTime" BU_SG_REL_ CGW SG_ 458 POS_PositionAge 3500;
BA_REL_ "GenSigTimeoutTime" BU_SG_REL_ CLU SG_ 458 POS_PositionAge 3500;
BA_ "SigDescription" SG_ 458 POS_PositionAge "[Default Value]
0xC8";
BA_ "Platform" SG_ 458 POS_PositionAge "";
BA_ "GenSigSendType" SG_ 458 POS_PositionAge 3;
BA_ "GenSigStartValue" SG_ 458 POS_PositionAge 511;
BA_ "TimeoutValue" SG_ 458 POS_PositionAge "Invalid";
BA_ "Validity" SG_ 458 POS_PositionAge 2;
BA_REL_ "GenSigTimeoutTime" BU_SG_REL_ CGW SG_ 458 POS_CurrentLane 3500;
BA_REL_ "GenSigTimeoutTime" BU_SG_REL_ CLU SG_ 458 POS_CurrentLane 3500;
BA_ "SigDescription" SG_ 458 POS_CurrentLane "[Default Value]
0x7";
BA_ "Platform" SG_ 458 POS_CurrentLane "";
BA_ "GenSigSendType" SG_ 458 POS_CurrentLane 3;
BA_ "GenSigStartValue" SG_ 458 POS_CurrentLane 7;
BA_ "TimeoutValue" SG_ 458 POS_CurrentLane "Invalid";
BA_ "Validity" SG_ 458 POS_CurrentLane 2;
BA_REL_ "GenSigTimeoutTime" BU_SG_REL_ CGW SG_ 458 POS_PositionConfidence 3500;
BA_REL_ "GenSigTimeoutTime" BU_SG_REL_ CLU SG_ 458 POS_PositionConfidence 3500;
BA_ "SigDescription" SG_ 458 POS_PositionConfidence "[Default Value]
0x7";
BA_ "Platform" SG_ 458 POS_PositionConfidence "";
BA_ "GenSigSendType" SG_ 458 POS_PositionConfidence 3;
BA_ "GenSigStartValue" SG_ 458 POS_PositionConfidence 7;
BA_ "TimeoutValue" SG_ 458 POS_PositionConfidence "Invalid";
BA_ "Validity" SG_ 458 POS_PositionConfidence 2;
BA_REL_ "GenSigTimeoutTime" BU_SG_REL_ CGW SG_ 458 POS_RangeAvgSpeed 3500;
BA_REL_ "GenSigTimeoutTime" BU_SG_REL_ CLU SG_ 458 POS_RangeAvgSpeed 3500;
BA_ "SigDescription" SG_ 458 POS_RangeAvgSpeed "[Default Value]
0x0";
BA_ "Platform" SG_ 458 POS_RangeAvgSpeed "";
BA_ "GenSigSendType" SG_ 458 POS_RangeAvgSpeed 3;
BA_ "GenSigStartValue" SG_ 458 POS_RangeAvgSpeed 511;
BA_ "TimeoutValue" SG_ 458 POS_RangeAvgSpeed "Invalid";
BA_ "Validity" SG_ 458 POS_RangeAvgSpeed 2;
BA_REL_ "GenSigTimeoutTime" BU_SG_REL_ CGW SG_ 458 POS_RelativeHeading 3500;
BA_REL_ "GenSigTimeoutTime" BU_SG_REL_ CLU SG_ 458 POS_RelativeHeading 3500;
BA_ "SigDescription" SG_ 458 POS_RelativeHeading "[Default Value]
0xFF";
BA_ "Platform" SG_ 458 POS_RelativeHeading "";
BA_ "GenSigSendType" SG_ 458 POS_RelativeHeading 3;
BA_ "GenSigStartValue" SG_ 458 POS_RelativeHeading 255;
BA_ "TimeoutValue" SG_ 458 POS_RelativeHeading "Invalid";
BA_ "Validity" SG_ 458 POS_RelativeHeading 2;
BA_ "GenMsgCycleTimeFast" BO_ 202 40;
BA_ "GenMsgNrOfRepetition" BO_ 202 3;
BA_REL_ "GenSigTimeoutTime" BU_SG_REL_ CGW SG_ 202 SEG_MessageType 0;
BA_REL_ "GenSigTimeoutTime" BU_SG_REL_ CLU SG_ 202 SEG_MessageType 0;
BA_ "SigDescription" SG_ 202 SEG_MessageType "[Default Value]
0x2";
BA_ "Platform" SG_ 202 SEG_MessageType "";
BA_ "GenSigSendType" SG_ 202 SEG_MessageType 4;
BA_ "GenSigStartValue" SG_ 202 SEG_MessageType 7;
BA_ "NmNetworkRequest" SG_ 202 SEG_MessageType 1;
BA_ "Validity" SG_ 202 SEG_MessageType 2;
BA_REL_ "GenSigTimeoutTime" BU_SG_REL_ CGW SG_ 202 SEG_Offset 0;
BA_REL_ "GenSigTimeoutTime" BU_SG_REL_ CLU SG_ 202 SEG_Offset 0;
BA_ "SigDescription" SG_ 202 SEG_Offset "[Default Value]
0x1FFF";
BA_ "Platform" SG_ 202 SEG_Offset "";
BA_ "GenSigSendType" SG_ 202 SEG_Offset 4;
BA_ "GenSigStartValue" SG_ 202 SEG_Offset 8191;
BA_ "NmNetworkRequest" SG_ 202 SEG_Offset 1;
BA_ "Validity" SG_ 202 SEG_Offset 2;
BA_REL_ "GenSigTimeoutTime" BU_SG_REL_ CGW SG_ 202 SEG_PathIndex 0;
BA_REL_ "GenSigTimeoutTime" BU_SG_REL_ CLU SG_ 202 SEG_PathIndex 0;
BA_ "SigDescription" SG_ 202 SEG_PathIndex "[Default Value]
0x0";
BA_ "Platform" SG_ 202 SEG_PathIndex "";
BA_ "GenSigSendType" SG_ 202 SEG_PathIndex 4;
BA_ "NmNetworkRequest" SG_ 202 SEG_PathIndex 1;
BA_ "Validity" SG_ 202 SEG_PathIndex 2;
BA_REL_ "GenSigTimeoutTime" BU_SG_REL_ CGW SG_ 202 SEG_CyclicCounter 0;
BA_REL_ "GenSigTimeoutTime" BU_SG_REL_ CLU SG_ 202 SEG_CyclicCounter 0;
BA_ "SigDescription" SG_ 202 SEG_CyclicCounter "[Default Value]
0x0";
BA_ "Platform" SG_ 202 SEG_CyclicCounter "";
BA_ "GenSigSendType" SG_ 202 SEG_CyclicCounter 4;
BA_ "NmNetworkRequest" SG_ 202 SEG_CyclicCounter 1;
BA_ "Validity" SG_ 202 SEG_CyclicCounter 2;
BA_REL_ "GenSigTimeoutTime" BU_SG_REL_ CGW SG_ 202 SEG_Update 0;
BA_REL_ "GenSigTimeoutTime" BU_SG_REL_ CLU SG_ 202 SEG_Update 0;
BA_ "SigDescription" SG_ 202 SEG_Update "[Default Value]
0x0";
BA_ "Platform" SG_ 202 SEG_Update "";
BA_ "GenSigSendType" SG_ 202 SEG_Update 4;
BA_ "NmNetworkRequest" SG_ 202 SEG_Update 1;
BA_ "Validity" SG_ 202 SEG_Update 2;
BA_REL_ "GenSigTimeoutTime" BU_SG_REL_ CGW SG_ 202 SEG_Retransmission 0;
BA_REL_ "GenSigTimeoutTime" BU_SG_REL_ CLU SG_ 202 SEG_Retransmission 0;
BA_ "SigDescription" SG_ 202 SEG_Retransmission "[Default Value]
0x0";
BA_ "Platform" SG_ 202 SEG_Retransmission "";
BA_ "GenSigSendType" SG_ 202 SEG_Retransmission 4;
BA_ "NmNetworkRequest" SG_ 202 SEG_Retransmission 1;
BA_ "Validity" SG_ 202 SEG_Retransmission 2;
BA_REL_ "GenSigTimeoutTime" BU_SG_REL_ CGW SG_ 202 SEG_BuiltUpArea 0;
BA_REL_ "GenSigTimeoutTime" BU_SG_REL_ CLU SG_ 202 SEG_BuiltUpArea 0;
BA_ "SigDescription" SG_ 202 SEG_BuiltUpArea "[Default Value]
0x3";
BA_ "Platform" SG_ 202 SEG_BuiltUpArea "";
BA_ "GenSigSendType" SG_ 202 SEG_BuiltUpArea 4;
BA_ "GenSigStartValue" SG_ 202 SEG_BuiltUpArea 3;
BA_ "NmNetworkRequest" SG_ 202 SEG_BuiltUpArea 1;
BA_ "Validity" SG_ 202 SEG_BuiltUpArea 2;
BA_REL_ "GenSigTimeoutTime" BU_SG_REL_ CGW SG_ 202 SEG_Bridge 0;
BA_REL_ "GenSigTimeoutTime" BU_SG_REL_ CLU SG_ 202 SEG_Bridge 0;
BA_ "SigDescription" SG_ 202 SEG_Bridge "[Default Value]
0x2";
BA_ "Platform" SG_ 202 SEG_Bridge "";
BA_ "GenSigSendType" SG_ 202 SEG_Bridge 4;
BA_ "GenSigStartValue" SG_ 202 SEG_Bridge 3;
BA_ "NmNetworkRequest" SG_ 202 SEG_Bridge 1;
BA_ "Validity" SG_ 202 SEG_Bridge 2;
BA_REL_ "GenSigTimeoutTime" BU_SG_REL_ CGW SG_ 202 SEG_Tunnel 0;
BA_REL_ "GenSigTimeoutTime" BU_SG_REL_ CLU SG_ 202 SEG_Tunnel 0;
BA_ "SigDescription" SG_ 202 SEG_Tunnel "[Default Value]
0x2";
BA_ "Platform" SG_ 202 SEG_Tunnel "";
BA_ "GenSigSendType" SG_ 202 SEG_Tunnel 4;
BA_ "GenSigStartValue" SG_ 202 SEG_Tunnel 3;
BA_ "NmNetworkRequest" SG_ 202 SEG_Tunnel 1;
BA_ "Validity" SG_ 202 SEG_Tunnel 2;
BA_REL_ "GenSigTimeoutTime" BU_SG_REL_ CGW SG_ 202 SEG_FunctionalRoadClass 0;
BA_REL_ "GenSigTimeoutTime" BU_SG_REL_ CLU SG_ 202 SEG_FunctionalRoadClass 0;
BA_ "SigDescription" SG_ 202 SEG_FunctionalRoadClass "[Default Vaule]
0x0";
BA_ "Platform" SG_ 202 SEG_FunctionalRoadClass "";
BA_ "GenSigSendType" SG_ 202 SEG_FunctionalRoadClass 4;
BA_ "GenSigStartValue" SG_ 202 SEG_FunctionalRoadClass 7;
BA_ "NmNetworkRequest" SG_ 202 SEG_FunctionalRoadClass 1;
BA_ "Validity" SG_ 202 SEG_FunctionalRoadClass 2;
BA_REL_ "GenSigTimeoutTime" BU_SG_REL_ CGW SG_ 202 SEG_RelativeProbability 0;
BA_REL_ "GenSigTimeoutTime" BU_SG_REL_ CLU SG_ 202 SEG_RelativeProbability 0;
BA_ "SigDescription" SG_ 202 SEG_RelativeProbability "[Default Value]
0x1F";
BA_ "Platform" SG_ 202 SEG_RelativeProbability "";
BA_ "GenSigSendType" SG_ 202 SEG_RelativeProbability 4;
BA_ "GenSigStartValue" SG_ 202 SEG_RelativeProbability 31;
BA_ "NmNetworkRequest" SG_ 202 SEG_RelativeProbability 1;
BA_ "Validity" SG_ 202 SEG_RelativeProbability 2;
BA_REL_ "GenSigTimeoutTime" BU_SG_REL_ CGW SG_ 202 SEG_FormOfWay 0;
BA_REL_ "GenSigTimeoutTime" BU_SG_REL_ CLU SG_ 202 SEG_FormOfWay 0;
BA_ "SigDescription" SG_ 202 SEG_FormOfWay "[Default Value]
0x0";
BA_ "Platform" SG_ 202 SEG_FormOfWay "";
BA_ "GenSigSendType" SG_ 202 SEG_FormOfWay 4;
BA_ "GenSigStartValue" SG_ 202 SEG_FormOfWay 15;
BA_ "NmNetworkRequest" SG_ 202 SEG_FormOfWay 1;
BA_ "Validity" SG_ 202 SEG_FormOfWay 2;
BA_REL_ "GenSigTimeoutTime" BU_SG_REL_ CGW SG_ 202 SEG_ComplexIntersection 0;
BA_REL_ "GenSigTimeoutTime" BU_SG_REL_ CLU SG_ 202 SEG_ComplexIntersection 0;
BA_ "SigDescription" SG_ 202 SEG_ComplexIntersection "[Default Value]
0x3";
BA_ "Platform" SG_ 202 SEG_ComplexIntersection "";
BA_ "GenSigSendType" SG_ 202 SEG_ComplexIntersection 4;
BA_ "GenSigStartValue" SG_ 202 SEG_ComplexIntersection 3;
BA_ "NmNetworkRequest" SG_ 202 SEG_ComplexIntersection 1;
BA_ "Validity" SG_ 202 SEG_ComplexIntersection 2;
BA_REL_ "GenSigTimeoutTime" BU_SG_REL_ CGW SG_ 202 SEG_CalculatedRoute 0;
BA_REL_ "GenSigTimeoutTime" BU_SG_REL_ CLU SG_ 202 SEG_CalculatedRoute 0;
BA_ "SigDescription" SG_ 202 SEG_CalculatedRoute "[Default Value]
0x3";
BA_ "Platform" SG_ 202 SEG_CalculatedRoute "";
BA_ "GenSigSendType" SG_ 202 SEG_CalculatedRoute 4;
BA_ "GenSigStartValue" SG_ 202 SEG_CalculatedRoute 3;
BA_ "NmNetworkRequest" SG_ 202 SEG_CalculatedRoute 1;
BA_ "Validity" SG_ 202 SEG_CalculatedRoute 2;
BA_REL_ "GenSigTimeoutTime" BU_SG_REL_ CGW SG_ 202 SEG_SpeedLimitType 0;
BA_REL_ "GenSigTimeoutTime" BU_SG_REL_ CLU SG_ 202 SEG_SpeedLimitType 0;
BA_ "SigDescription" SG_ 202 SEG_SpeedLimitType "[Default Value]
0x0";
BA_ "Platform" SG_ 202 SEG_SpeedLimitType "";
BA_ "GenSigSendType" SG_ 202 SEG_SpeedLimitType 4;
BA_ "GenSigStartValue" SG_ 202 SEG_SpeedLimitType 7;
BA_ "NmNetworkRequest" SG_ 202 SEG_SpeedLimitType 1;
BA_ "Validity" SG_ 202 SEG_SpeedLimitType 2;
BA_REL_ "GenSigTimeoutTime" BU_SG_REL_ CGW SG_ 202 SEG_SpeedLimit 0;
BA_REL_ "GenSigTimeoutTime" BU_SG_REL_ CLU SG_ 202 SEG_SpeedLimit 0;
BA_ "SigDescription" SG_ 202 SEG_SpeedLimit "[Default Value]
0x0";
BA_ "Platform" SG_ 202 SEG_SpeedLimit "";
BA_ "GenSigSendType" SG_ 202 SEG_SpeedLimit 4;
BA_ "GenSigStartValue" SG_ 202 SEG_SpeedLimit 31;
BA_ "NmNetworkRequest" SG_ 202 SEG_SpeedLimit 1;
BA_ "Validity" SG_ 202 SEG_SpeedLimit 2;
BA_REL_ "GenSigTimeoutTime" BU_SG_REL_ CGW SG_ 202 SEG_DirectionLanes 0;
BA_REL_ "GenSigTimeoutTime" BU_SG_REL_ CLU SG_ 202 SEG_DirectionLanes 0;
BA_ "SigDescription" SG_ 202 SEG_DirectionLanes "[Default Value]
0x0";
BA_ "Platform" SG_ 202 SEG_DirectionLanes "";
BA_ "GenSigSendType" SG_ 202 SEG_DirectionLanes 4;
BA_ "GenSigStartValue" SG_ 202 SEG_DirectionLanes 7;
BA_ "NmNetworkRequest" SG_ 202 SEG_DirectionLanes 1;
BA_ "Validity" SG_ 202 SEG_DirectionLanes 2;
BA_REL_ "GenSigTimeoutTime" BU_SG_REL_ CGW SG_ 202 SEG_SpeedLimitUnder5 0;
BA_REL_ "GenSigTimeoutTime" BU_SG_REL_ CLU SG_ 202 SEG_SpeedLimitUnder5 0;
BA_ "SigDescription" SG_ 202 SEG_SpeedLimitUnder5 "[Default Value]
0x0";
BA_ "Platform" SG_ 202 SEG_SpeedLimitUnder5 "";
BA_ "GenSigSendType" SG_ 202 SEG_SpeedLimitUnder5 4;
BA_ "GenSigStartValue" SG_ 202 SEG_SpeedLimitUnder5 7;
BA_ "NmNetworkRequest" SG_ 202 SEG_SpeedLimitUnder5 1;
BA_ "Validity" SG_ 202 SEG_SpeedLimitUnder5 2;
BA_ "GenMsgCycleTimeFast" BO_ 203 40;
BA_ "GenMsgNrOfRepetition" BO_ 203 3;
BA_REL_ "GenSigTimeoutTime" BU_SG_REL_ CGW SG_ 203 STUB_MessageType 0;
BA_REL_ "GenSigTimeoutTime" BU_SG_REL_ CLU SG_ 203 STUB_MessageType 0;
BA_ "SigDescription" SG_ 203 STUB_MessageType "[Default Value]
0x3";
BA_ "Platform" SG_ 203 STUB_MessageType "";
BA_ "GenSigSendType" SG_ 203 STUB_MessageType 4;
BA_ "GenSigStartValue" SG_ 203 STUB_MessageType 7;
BA_ "NmNetworkRequest" SG_ 203 STUB_MessageType 1;
BA_ "Validity" SG_ 203 STUB_MessageType 2;
BA_REL_ "GenSigTimeoutTime" BU_SG_REL_ CGW SG_ 203 STUB_Offset 0;
BA_REL_ "GenSigTimeoutTime" BU_SG_REL_ CLU SG_ 203 STUB_Offset 0;
BA_ "SigDescription" SG_ 203 STUB_Offset "[Default Value]
0x1FFF";
BA_ "Platform" SG_ 203 STUB_Offset "";
BA_ "GenSigSendType" SG_ 203 STUB_Offset 4;
BA_ "GenSigStartValue" SG_ 203 STUB_Offset 8191;
BA_ "NmNetworkRequest" SG_ 203 STUB_Offset 1;
BA_ "Validity" SG_ 203 STUB_Offset 2;
BA_REL_ "GenSigTimeoutTime" BU_SG_REL_ CGW SG_ 203 STUB_PathIndex 0;
BA_REL_ "GenSigTimeoutTime" BU_SG_REL_ CLU SG_ 203 STUB_PathIndex 0;
BA_ "SigDescription" SG_ 203 STUB_PathIndex "[Default Value]
0x0";
BA_ "Platform" SG_ 203 STUB_PathIndex "";
BA_ "GenSigSendType" SG_ 203 STUB_PathIndex 4;
BA_ "NmNetworkRequest" SG_ 203 STUB_PathIndex 1;
BA_ "Validity" SG_ 203 STUB_PathIndex 2;
BA_REL_ "GenSigTimeoutTime" BU_SG_REL_ CGW SG_ 203 STUB_CyclicCounter 0;
BA_REL_ "GenSigTimeoutTime" BU_SG_REL_ CLU SG_ 203 STUB_CyclicCounter 0;
BA_ "SigDescription" SG_ 203 STUB_CyclicCounter "[Default Value]
0x0";
BA_ "Platform" SG_ 203 STUB_CyclicCounter "";
BA_ "GenSigSendType" SG_ 203 STUB_CyclicCounter 4;
BA_ "NmNetworkRequest" SG_ 203 STUB_CyclicCounter 1;
BA_ "Validity" SG_ 203 STUB_CyclicCounter 2;
BA_REL_ "GenSigTimeoutTime" BU_SG_REL_ CGW SG_ 203 STUB_Update 0;
BA_REL_ "GenSigTimeoutTime" BU_SG_REL_ CLU SG_ 203 STUB_Update 0;
BA_ "SigDescription" SG_ 203 STUB_Update "[Default Value]
0x0";
BA_ "Platform" SG_ 203 STUB_Update "";
BA_ "GenSigSendType" SG_ 203 STUB_Update 4;
BA_ "NmNetworkRequest" SG_ 203 STUB_Update 1;
BA_ "Validity" SG_ 203 STUB_Update 2;
BA_REL_ "GenSigTimeoutTime" BU_SG_REL_ CGW SG_ 203 STUB_Retransmission 0;
BA_REL_ "GenSigTimeoutTime" BU_SG_REL_ CLU SG_ 203 STUB_Retransmission 0;
BA_ "SigDescription" SG_ 203 STUB_Retransmission "[Default Value]
0x0";
BA_ "Platform" SG_ 203 STUB_Retransmission "";
BA_ "GenSigSendType" SG_ 203 STUB_Retransmission 4;
BA_ "NmNetworkRequest" SG_ 203 STUB_Retransmission 1;
BA_ "Validity" SG_ 203 STUB_Retransmission 2;
BA_REL_ "GenSigTimeoutTime" BU_SG_REL_ CGW SG_ 203 STUB_SubPathIndex 0;
BA_REL_ "GenSigTimeoutTime" BU_SG_REL_ CLU SG_ 203 STUB_SubPathIndex 0;
BA_ "SigDescription" SG_ 203 STUB_SubPathIndex "[Default Value]
0x0";
BA_ "Platform" SG_ 203 STUB_SubPathIndex "";
BA_ "GenSigSendType" SG_ 203 STUB_SubPathIndex 4;
BA_ "NmNetworkRequest" SG_ 203 STUB_SubPathIndex 1;
BA_ "Validity" SG_ 203 STUB_SubPathIndex 2;
BA_REL_ "GenSigTimeoutTime" BU_SG_REL_ CGW SG_ 203 STUB_FunctionalRoadClass 0;
BA_REL_ "GenSigTimeoutTime" BU_SG_REL_ CLU SG_ 203 STUB_FunctionalRoadClass 0;
BA_ "SigDescription" SG_ 203 STUB_FunctionalRoadClass "[Default Value]
0x0";
BA_ "Platform" SG_ 203 STUB_FunctionalRoadClass "";
BA_ "GenSigSendType" SG_ 203 STUB_FunctionalRoadClass 4;
BA_ "GenSigStartValue" SG_ 203 STUB_FunctionalRoadClass 7;
BA_ "NmNetworkRequest" SG_ 203 STUB_FunctionalRoadClass 1;
BA_ "Validity" SG_ 203 STUB_FunctionalRoadClass 2;
BA_REL_ "GenSigTimeoutTime" BU_SG_REL_ CGW SG_ 203 STUB_RelativeProbability 0;
BA_REL_ "GenSigTimeoutTime" BU_SG_REL_ CLU SG_ 203 STUB_RelativeProbability 0;
BA_ "SigDescription" SG_ 203 STUB_RelativeProbability "[Default Value]
0x1F";
BA_ "Platform" SG_ 203 STUB_RelativeProbability "";
BA_ "GenSigSendType" SG_ 203 STUB_RelativeProbability 4;
BA_ "GenSigStartValue" SG_ 203 STUB_RelativeProbability 31;
BA_ "NmNetworkRequest" SG_ 203 STUB_RelativeProbability 1;
BA_ "Validity" SG_ 203 STUB_RelativeProbability 2;
BA_REL_ "GenSigTimeoutTime" BU_SG_REL_ CGW SG_ 203 STUB_FormOfWay 0;
BA_REL_ "GenSigTimeoutTime" BU_SG_REL_ CLU SG_ 203 STUB_FormOfWay 0;
BA_ "SigDescription" SG_ 203 STUB_FormOfWay "[Default Value]
0x0";
BA_ "Platform" SG_ 203 STUB_FormOfWay "";
BA_ "GenSigSendType" SG_ 203 STUB_FormOfWay 4;
BA_ "GenSigStartValue" SG_ 203 STUB_FormOfWay 15;
BA_ "NmNetworkRequest" SG_ 203 STUB_FormOfWay 1;
BA_ "Validity" SG_ 203 STUB_FormOfWay 2;
BA_REL_ "GenSigTimeoutTime" BU_SG_REL_ CGW SG_ 203 STUB_ComplexIntersection 0;
BA_REL_ "GenSigTimeoutTime" BU_SG_REL_ CLU SG_ 203 STUB_ComplexIntersection 0;
BA_ "SigDescription" SG_ 203 STUB_ComplexIntersection "[Default Value]
0x3";
BA_ "Platform" SG_ 203 STUB_ComplexIntersection "";
BA_ "GenSigSendType" SG_ 203 STUB_ComplexIntersection 4;
BA_ "GenSigStartValue" SG_ 203 STUB_ComplexIntersection 3;
BA_ "NmNetworkRequest" SG_ 203 STUB_ComplexIntersection 1;
BA_ "Validity" SG_ 203 STUB_ComplexIntersection 2;
BA_REL_ "GenSigTimeoutTime" BU_SG_REL_ CGW SG_ 203 STUB_CalculatedRoute 0;
BA_REL_ "GenSigTimeoutTime" BU_SG_REL_ CLU SG_ 203 STUB_CalculatedRoute 0;
BA_ "SigDescription" SG_ 203 STUB_CalculatedRoute "[Default Value]
0x3";
BA_ "Platform" SG_ 203 STUB_CalculatedRoute "";
BA_ "GenSigSendType" SG_ 203 STUB_CalculatedRoute 4;
BA_ "GenSigStartValue" SG_ 203 STUB_CalculatedRoute 3;
BA_ "NmNetworkRequest" SG_ 203 STUB_CalculatedRoute 1;
BA_ "Validity" SG_ 203 STUB_CalculatedRoute 2;
BA_REL_ "GenSigTimeoutTime" BU_SG_REL_ CGW SG_ 203 STUB_TurnAngle 0;
BA_REL_ "GenSigTimeoutTime" BU_SG_REL_ CLU SG_ 203 STUB_TurnAngle 0;
BA_ "SigDescription" SG_ 203 STUB_TurnAngle "[Default Value]
0xFE";
BA_ "Platform" SG_ 203 STUB_TurnAngle "";
BA_ "GenSigSendType" SG_ 203 STUB_TurnAngle 4;
BA_ "GenSigStartValue" SG_ 203 STUB_TurnAngle 255;
BA_ "NmNetworkRequest" SG_ 203 STUB_TurnAngle 1;
BA_ "Validity" SG_ 203 STUB_TurnAngle 2;
BA_REL_ "GenSigTimeoutTime" BU_SG_REL_ CGW SG_ 203 STUB_DirectionLanes 0;
BA_REL_ "GenSigTimeoutTime" BU_SG_REL_ CLU SG_ 203 STUB_DirectionLanes 0;
BA_ "SigDescription" SG_ 203 STUB_DirectionLanes "[Default Value]
0x0";
BA_ "Platform" SG_ 203 STUB_DirectionLanes "";
BA_ "GenSigSendType" SG_ 203 STUB_DirectionLanes 4;
BA_ "GenSigStartValue" SG_ 203 STUB_DirectionLanes 7;
BA_ "NmNetworkRequest" SG_ 203 STUB_DirectionLanes 1;
BA_ "Validity" SG_ 203 STUB_DirectionLanes 2;
BA_REL_ "GenSigTimeoutTime" BU_SG_REL_ CGW SG_ 203 STUB_RightOfWay 0;
BA_REL_ "GenSigTimeoutTime" BU_SG_REL_ CLU SG_ 203 STUB_RightOfWay 0;
BA_ "SigDescription" SG_ 203 STUB_RightOfWay "[Default Value]
0x3";
BA_ "Platform" SG_ 203 STUB_RightOfWay "";
BA_ "GenSigSendType" SG_ 203 STUB_RightOfWay 4;
BA_ "GenSigStartValue" SG_ 203 STUB_RightOfWay 3;
BA_ "NmNetworkRequest" SG_ 203 STUB_RightOfWay 1;
BA_ "Validity" SG_ 203 STUB_RightOfWay 2;
BA_REL_ "GenSigTimeoutTime" BU_SG_REL_ CGW SG_ 203 STUB_LastStubAtOffset 0;
BA_REL_ "GenSigTimeoutTime" BU_SG_REL_ CLU SG_ 203 STUB_LastStubAtOffset 0;
BA_ "SigDescription" SG_ 203 STUB_LastStubAtOffset "[Default Value]
0x0";
BA_ "Platform" SG_ 203 STUB_LastStubAtOffset "";
BA_ "GenSigSendType" SG_ 203 STUB_LastStubAtOffset 4;
BA_ "NmNetworkRequest" SG_ 203 STUB_LastStubAtOffset 1;
BA_ "Validity" SG_ 203 STUB_LastStubAtOffset 2;
BA_REL_ "GenSigTimeoutTime" BU_SG_REL_ CGW SG_ 88 HU_RVM_CameraOff 0;
BA_REL_ "GenSigTimeoutTime" BU_SG_REL_ CLU SG_ 88 HU_RVM_CameraOff 0;
BA_ "Platform" SG_ 88 HU_RVM_CameraOff "Compact AVN,D-Audio,DIS 2,Economic Audio 3.0,Integrated AVN1.0 High,Integrated AVN1.0 Mid,Premium AVN 2.0,Standard AVN 4.0,Standard Audio 3.0,Standard Audio 4.0,UVO3 (D-Audio Kia)";
BA_ "GenSigSendType" SG_ 88 HU_RVM_CameraOff 3;
BA_ "GenSigStartValue" SG_ 88 HU_RVM_CameraOff 3;
BA_ "Validity" SG_ 88 HU_RVM_CameraOff 2;
BA_REL_ "GenSigTimeoutTime" BU_SG_REL_ CGW SG_ 101 CF_AVN_LFANValueSet 0;
BA_REL_ "GenSigTimeoutTime" BU_SG_REL_ CLU SG_ 101 CF_AVN_LFANValueSet 0;
BA_ "Platform" SG_ 101 CF_AVN_LFANValueSet "D-Audio,Integrated AVN1.0 High,Integrated AVN1.0 Mid,Premium AVN 2.0";
BA_ "GenSigSendType" SG_ 101 CF_AVN_LFANValueSet 3;
BA_ "Validity" SG_ 101 CF_AVN_LFANValueSet 2;
BA_REL_ "GenSigTimeoutTime" BU_SG_REL_ CGW SG_ 101 CF_AVN_FCANValueSet 0;
BA_REL_ "GenSigTimeoutTime" BU_SG_REL_ CLU SG_ 101 CF_AVN_FCANValueSet 0;
BA_ "Platform" SG_ 101 CF_AVN_FCANValueSet "D-Audio,Integrated AVN1.0 High,Integrated AVN1.0 Mid,Premium AVN 2.0";
BA_ "GenSigSendType" SG_ 101 CF_AVN_FCANValueSet 3;
BA_ "TimeoutValue" SG_ 101 CF_AVN_FCANValueSet "Invalid";
BA_ "Validity" SG_ 101 CF_AVN_FCANValueSet 2;
BA_REL_ "GenSigTimeoutTime" BU_SG_REL_ CGW SG_ 101 CF_AVN_HDANValueSet 0;
BA_REL_ "GenSigTimeoutTime" BU_SG_REL_ CLU SG_ 101 CF_AVN_HDANValueSet 0;
BA_ "Platform" SG_ 101 CF_AVN_HDANValueSet "D-Audio,Integrated AVN1.0 High,Integrated AVN1.0 Mid,Premium AVN 2.0";
BA_ "GenSigSendType" SG_ 101 CF_AVN_HDANValueSet 3;
BA_ "Validity" SG_ 101 CF_AVN_HDANValueSet 2;
BA_REL_ "GenSigTimeoutTime" BU_SG_REL_ CGW SG_ 101 CF_AVN_DAWModeNValueSet 0;
BA_REL_ "GenSigTimeoutTime" BU_SG_REL_ CLU SG_ 101 CF_AVN_DAWModeNValueSet 0;
BA_ "Platform" SG_ 101 CF_AVN_DAWModeNValueSet "D-Audio,Integrated AVN1.0 High,Integrated AVN1.0 Mid,Premium AVN 2.0";
BA_ "GenSigSendType" SG_ 101 CF_AVN_DAWModeNValueSet 3;
BA_ "TimeoutValue" SG_ 101 CF_AVN_DAWModeNValueSet "Invalid";
BA_ "Validity" SG_ 101 CF_AVN_DAWModeNValueSet 2;
BA_REL_ "GenSigTimeoutTime" BU_SG_REL_ CGW SG_ 101 CF_AVN_SCCDrvModeNValueSet 0;
BA_REL_ "GenSigTimeoutTime" BU_SG_REL_ CLU SG_ 101 CF_AVN_SCCDrvModeNValueSet 0;
BA_ "Platform" SG_ 101 CF_AVN_SCCDrvModeNValueSet "D-Audio,Integrated AVN1.0 High,Integrated AVN1.0 Mid,Premium AVN 2.0";
BA_ "GenSigSendType" SG_ 101 CF_AVN_SCCDrvModeNValueSet 3;
BA_ "Gatewaysignal" SG_ 101 CF_AVN_SCCDrvModeNValueSet 3;
BA_ "TimeoutValue" SG_ 101 CF_AVN_SCCDrvModeNValueSet "Invalid";
BA_ "Validity" SG_ 101 CF_AVN_SCCDrvModeNValueSet 2;
BA_REL_ "GenSigTimeoutTime" BU_SG_REL_ CGW SG_ 101 CF_AVN_NSCCCamNValueSet 0;
BA_REL_ "GenSigTimeoutTime" BU_SG_REL_ CLU SG_ 101 CF_AVN_NSCCCamNValueSet 0;
BA_ "Platform" SG_ 101 CF_AVN_NSCCCamNValueSet "D-Audio,Integrated AVN1.0 High,Integrated AVN1.0 Mid,Premium AVN 2.0";
BA_ "GenSigSendType" SG_ 101 CF_AVN_NSCCCamNValueSet 3;
BA_ "TimeoutValue" SG_ 101 CF_AVN_NSCCCamNValueSet "Invalid";
BA_ "Validity" SG_ 101 CF_AVN_NSCCCamNValueSet 2;
BA_REL_ "GenSigTimeoutTime" BU_SG_REL_ CGW SG_ 101 CF_AVN_SEANValueSet 0;
BA_REL_ "GenSigTimeoutTime" BU_SG_REL_ CLU SG_ 101 CF_AVN_SEANValueSet 0;
BA_ "Platform" SG_ 101 CF_AVN_SEANValueSet "D-Audio,Integrated AVN1.0 High,Integrated AVN1.0 Mid,Premium AVN 2.0";
BA_ "GenSigSendType" SG_ 101 CF_AVN_SEANValueSet 3;
BA_ "TimeoutValue" SG_ 101 CF_AVN_SEANValueSet "Invalid";
BA_ "Validity" SG_ 101 CF_AVN_SEANValueSet 2;
BA_REL_ "GenSigTimeoutTime" BU_SG_REL_ CGW SG_ 101 CF_AVN_BCWNValueSet 0;
BA_REL_ "GenSigTimeoutTime" BU_SG_REL_ CLU SG_ 101 CF_AVN_BCWNValueSet 0;
BA_ "Platform" SG_ 101 CF_AVN_BCWNValueSet "D-Audio,Integrated AVN1.0 High,Integrated AVN1.0 Mid,Premium AVN 2.0";
BA_ "GenSigSendType" SG_ 101 CF_AVN_BCWNValueSet 3;
BA_ "TimeoutValue" SG_ 101 CF_AVN_BCWNValueSet "Invalid";
BA_ "Validity" SG_ 101 CF_AVN_BCWNValueSet 2;
BA_REL_ "GenSigTimeoutTime" BU_SG_REL_ CGW SG_ 101 CF_AVN_WarningTimingNValueSet 0;
BA_REL_ "GenSigTimeoutTime" BU_SG_REL_ CLU SG_ 101 CF_AVN_WarningTimingNValueSet 0;
BA_ "Platform" SG_ 101 CF_AVN_WarningTimingNValueSet "D-Audio,Integrated AVN1.0 High,Integrated AVN1.0 Mid,Premium AVN 2.0";
BA_ "GenSigSendType" SG_ 101 CF_AVN_WarningTimingNValueSet 3;
BA_ "TimeoutValue" SG_ 101 CF_AVN_WarningTimingNValueSet "Invalid";
BA_ "Validity" SG_ 101 CF_AVN_WarningTimingNValueSet 2;
BA_REL_ "GenSigTimeoutTime" BU_SG_REL_ CGW SG_ 101 CF_AVN_ISLWNValueSet 0;
BA_REL_ "GenSigTimeoutTime" BU_SG_REL_ CLU SG_ 101 CF_AVN_ISLWNValueSet 0;
BA_ "Platform" SG_ 101 CF_AVN_ISLWNValueSet "D-Audio,Integrated AVN1.0 High,Integrated AVN1.0 Mid,Premium AVN 2.0";
BA_ "GenSigSendType" SG_ 101 CF_AVN_ISLWNValueSet 3;
BA_ "Validity" SG_ 101 CF_AVN_ISLWNValueSet 2;
BA_REL_ "GenSigTimeoutTime" BU_SG_REL_ CGW SG_ 101 CF_AVN_BCANValueSet 0;
BA_REL_ "GenSigTimeoutTime" BU_SG_REL_ CLU SG_ 101 CF_AVN_BCANValueSet 0;
BA_ "Platform" SG_ 101 CF_AVN_BCANValueSet "D-Audio,Integrated AVN1.0 High,Integrated AVN1.0 Mid,Premium AVN 2.0";
BA_ "GenSigSendType" SG_ 101 CF_AVN_BCANValueSet 3;
BA_ "TimeoutValue" SG_ 101 CF_AVN_BCANValueSet "Invalid";
BA_ "Validity" SG_ 101 CF_AVN_BCANValueSet 2;
BA_REL_ "GenSigTimeoutTime" BU_SG_REL_ CGW SG_ 101 CF_AVN_RCCWNValueSet 0;
BA_REL_ "GenSigTimeoutTime" BU_SG_REL_ CLU SG_ 101 CF_AVN_RCCWNValueSet 0;
BA_ "Platform" SG_ 101 CF_AVN_RCCWNValueSet "D-Audio,Integrated AVN1.0 High,Integrated AVN1.0 Mid,Premium AVN 2.0";
BA_ "GenSigSendType" SG_ 101 CF_AVN_RCCWNValueSet 3;
BA_ "TimeoutValue" SG_ 101 CF_AVN_RCCWNValueSet "Invalid";
BA_ "Validity" SG_ 101 CF_AVN_RCCWNValueSet 2;
BA_REL_ "GenSigTimeoutTime" BU_SG_REL_ CGW SG_ 101 CF_AVN_BCWSndWanNValueSet 0;
BA_REL_ "GenSigTimeoutTime" BU_SG_REL_ CLU SG_ 101 CF_AVN_BCWSndWanNValueSet 0;
BA_ "Platform" SG_ 101 CF_AVN_BCWSndWanNValueSet "D-Audio,Integrated AVN1.0 High,Integrated AVN1.0 Mid,Premium AVN 2.0";
BA_ "GenSigSendType" SG_ 101 CF_AVN_BCWSndWanNValueSet 3;
BA_ "TimeoutValue" SG_ 101 CF_AVN_BCWSndWanNValueSet "Invalid";
BA_ "Validity" SG_ 101 CF_AVN_BCWSndWanNValueSet 2;
BA_REL_ "GenSigTimeoutTime" BU_SG_REL_ CGW SG_ 101 CF_AVN_NSCCCrvNValueSet 0;
BA_REL_ "GenSigTimeoutTime" BU_SG_REL_ CLU SG_ 101 CF_AVN_NSCCCrvNValueSet 0;
BA_ "Platform" SG_ 101 CF_AVN_NSCCCrvNValueSet "D-Audio,Integrated AVN1.0 High,Integrated AVN1.0 Mid,Premium AVN 2.0";
BA_ "GenSigSendType" SG_ 101 CF_AVN_NSCCCrvNValueSet 3;
BA_ "Validity" SG_ 101 CF_AVN_NSCCCrvNValueSet 2;
BA_REL_ "GenSigTimeoutTime" BU_SG_REL_ CGW SG_ 101 CF_SccFrVehDptNotiNValueSet 0;
BA_REL_ "GenSigTimeoutTime" BU_SG_REL_ CLU SG_ 101 CF_SccFrVehDptNotiNValueSet 0;
BA_ "Platform" SG_ 101 CF_SccFrVehDptNotiNValueSet "D-Audio,Integrated AVN1.0 High,Integrated AVN1.0 Mid,Premium AVN 2.0";
BA_ "GenSigSendType" SG_ 101 CF_SccFrVehDptNotiNValueSet 3;
BA_ "Validity" SG_ 101 CF_SccFrVehDptNotiNValueSet 2;
BA_REL_ "GenSigTimeoutTime" BU_SG_REL_ CGW SG_ 101 CF_AVN_LkaModeNValueSet 0;
BA_REL_ "GenSigTimeoutTime" BU_SG_REL_ CLU SG_ 101 CF_AVN_LkaModeNValueSet 0;
BA_ "Platform" SG_ 101 CF_AVN_LkaModeNValueSet "D-Audio,Integrated AVN1.0 High,Integrated AVN1.0 Mid,Premium AVN 2.0";
BA_ "GenSigSendType" SG_ 101 CF_AVN_LkaModeNValueSet 3;
BA_ "Validity" SG_ 101 CF_AVN_LkaModeNValueSet 2;
BA_REL_ "GenSigTimeoutTime" BU_SG_REL_ CLU SG_ 101 CF_AVN_AdasVolumeNValueSet 0;
BA_ "Platform" SG_ 101 CF_AVN_AdasVolumeNValueSet "D-Audio,Integrated AVN1.0 High,Integrated AVN1.0 Mid,Premium AVN 2.0";
BA_ "GenSigSendType" SG_ 101 CF_AVN_AdasVolumeNValueSet 3;
BA_ "Validity" SG_ 101 CF_AVN_AdasVolumeNValueSet 2;
BA_REL_ "GenSigTimeoutTime" BU_SG_REL_ CGW SG_ 102 CF_AVN_PTGSpeedNValueSet 0;
BA_REL_ "GenSigTimeoutTime" BU_SG_REL_ CLU SG_ 102 CF_AVN_PTGSpeedNValueSet 0;
BA_ "Platform" SG_ 102 CF_AVN_PTGSpeedNValueSet "D-Audio,Integrated AVN1.0 High,Integrated AVN1.0 Mid,Premium AVN 2.0";
BA_ "GenSigSendType" SG_ 102 CF_AVN_PTGSpeedNValueSet 3;
BA_ "Validity" SG_ 102 CF_AVN_PTGSpeedNValueSet 2;
BA_REL_ "GenSigTimeoutTime" BU_SG_REL_ CGW SG_ 102 CF_Avn_HAPTICWARNINGNValueSet 0;
BA_REL_ "GenSigTimeoutTime" BU_SG_REL_ CLU SG_ 102 CF_Avn_HAPTICWARNINGNValueSet 0;
BA_ "Platform" SG_ 102 CF_Avn_HAPTICWARNINGNValueSet "D-Audio,Integrated AVN1.0 High,Integrated AVN1.0 Mid,Premium AVN 2.0";
BA_ "GenSigSendType" SG_ 102 CF_Avn_HAPTICWARNINGNValueSet 3;
BA_ "Validity" SG_ 102 CF_Avn_HAPTICWARNINGNValueSet 2;
BA_REL_ "GenSigTimeoutTime" BU_SG_REL_ CLU SG_ 104 CF_AVN_CluVoiceVolume 0;
BA_ "Platform" SG_ 104 CF_AVN_CluVoiceVolume "";
BA_ "GenSigSendType" SG_ 104 CF_AVN_CluVoiceVolume 3;
BA_ "TimeoutValue" SG_ 104 CF_AVN_CluVoiceVolume "Invalid";
BA_ "Validity" SG_ 104 CF_AVN_CluVoiceVolume 2;
BA_REL_ "GenSigTimeoutTime" BU_SG_REL_ CLU SG_ 104 CF_AVN_CluAutoInitFuelEconomy 0;
BA_ "Platform" SG_ 104 CF_AVN_CluAutoInitFuelEconomy "D-Audio,Integrated AVN1.0 High,Integrated AVN1.0 Mid,Premium AVN 2.0";
BA_ "GenSigSendType" SG_ 104 CF_AVN_CluAutoInitFuelEconomy 3;
BA_ "TimeoutValue" SG_ 104 CF_AVN_CluAutoInitFuelEconomy "Invalid";
BA_ "Validity" SG_ 104 CF_AVN_CluAutoInitFuelEconomy 2;
BA_REL_ "GenSigTimeoutTime" BU_SG_REL_ CLU SG_ 104 CF_AVN_CluWelcomeSnd 0;
BA_ "Platform" SG_ 104 CF_AVN_CluWelcomeSnd "D-Audio,Integrated AVN1.0 High,Integrated AVN1.0 Mid,Premium AVN 2.0";
BA_ "GenSigSendType" SG_ 104 CF_AVN_CluWelcomeSnd 3;
BA_ "TimeoutValue" SG_ 104 CF_AVN_CluWelcomeSnd "Invalid";
BA_ "Validity" SG_ 104 CF_AVN_CluWelcomeSnd 2;
BA_REL_ "GenSigTimeoutTime" BU_SG_REL_ CLU SG_ 104 CF_AVN_CluRoadInfoGuide 0;
BA_ "Platform" SG_ 104 CF_AVN_CluRoadInfoGuide "D-Audio,Integrated AVN1.0 High,Integrated AVN1.0 Mid,Premium AVN 2.0";
BA_ "GenSigSendType" SG_ 104 CF_AVN_CluRoadInfoGuide 3;
BA_ "TimeoutValue" SG_ 104 CF_AVN_CluRoadInfoGuide "Invalid";
BA_ "Validity" SG_ 104 CF_AVN_CluRoadInfoGuide 2;
BA_REL_ "GenSigTimeoutTime" BU_SG_REL_ CLU SG_ 104 CF_AVN_CluWiperLight 0;
BA_ "Platform" SG_ 104 CF_AVN_CluWiperLight "D-Audio,Integrated AVN1.0 High,Integrated AVN1.0 Mid,Premium AVN 2.0";
BA_ "GenSigSendType" SG_ 104 CF_AVN_CluWiperLight 3;
BA_ "TimeoutValue" SG_ 104 CF_AVN_CluWiperLight "Invalid";
BA_ "Validity" SG_ 104 CF_AVN_CluWiperLight 2;
BA_REL_ "GenSigTimeoutTime" BU_SG_REL_ CLU SG_ 104 CF_AVN_CluTransmissionDisp 0;
BA_ "Platform" SG_ 104 CF_AVN_CluTransmissionDisp "D-Audio,Integrated AVN1.0 High,Integrated AVN1.0 Mid,Premium AVN 2.0";
BA_ "GenSigSendType" SG_ 104 CF_AVN_CluTransmissionDisp 3;
BA_ "TimeoutValue" SG_ 104 CF_AVN_CluTransmissionDisp "Invalid";
BA_ "Validity" SG_ 104 CF_AVN_CluTransmissionDisp 2;
BA_REL_ "GenSigTimeoutTime" BU_SG_REL_ CLU SG_ 104 CF_AVN_CluServiceReminderSet 0;
BA_ "Platform" SG_ 104 CF_AVN_CluServiceReminderSet "D-Audio,Integrated AVN1.0 High,Integrated AVN1.0 Mid,Premium AVN 2.0";
BA_ "GenSigSendType" SG_ 104 CF_AVN_CluServiceReminderSet 3;
BA_ "TimeoutValue" SG_ 104 CF_AVN_CluServiceReminderSet "Invalid";
BA_ "Validity" SG_ 104 CF_AVN_CluServiceReminderSet 2;
BA_REL_ "GenSigTimeoutTime" BU_SG_REL_ CLU SG_ 104 CF_AVN_CluUserSettingPeriod 0;
BA_ "Platform" SG_ 104 CF_AVN_CluUserSettingPeriod "D-Audio,Integrated AVN1.0 High,Integrated AVN1.0 Mid,Premium AVN 2.0";
BA_ "GenSigSendType" SG_ 104 CF_AVN_CluUserSettingPeriod 3;
BA_ "TimeoutValue" SG_ 104 CF_AVN_CluUserSettingPeriod "Invalid";
BA_ "Validity" SG_ 104 CF_AVN_CluUserSettingPeriod 2;
BA_REL_ "GenSigTimeoutTime" BU_SG_REL_ CGW SG_ 104 CF_AVN_CluFuelEconUnit_km 0;
BA_REL_ "GenSigTimeoutTime" BU_SG_REL_ CLU SG_ 104 CF_AVN_CluFuelEconUnit_km 0;
BA_ "Platform" SG_ 104 CF_AVN_CluFuelEconUnit_km "D-Audio,Integrated AVN1.0 High,Integrated AVN1.0 Mid,Premium AVN 2.0";
BA_ "GenSigSendType" SG_ 104 CF_AVN_CluFuelEconUnit_km 3;
BA_ "Validity" SG_ 104 CF_AVN_CluFuelEconUnit_km 2;
BA_REL_ "GenSigTimeoutTime" BU_SG_REL_ CGW SG_ 104 CF_AVN_CluFuelEconUnit_mi 0;
BA_REL_ "GenSigTimeoutTime" BU_SG_REL_ CLU SG_ 104 CF_AVN_CluFuelEconUnit_mi 0;
BA_ "Platform" SG_ 104 CF_AVN_CluFuelEconUnit_mi "D-Audio,Integrated AVN1.0 High,Integrated AVN1.0 Mid,Premium AVN 2.0";
BA_ "GenSigSendType" SG_ 104 CF_AVN_CluFuelEconUnit_mi 3;
BA_ "Validity" SG_ 104 CF_AVN_CluFuelEconUnit_mi 2;
BA_REL_ "GenSigTimeoutTime" BU_SG_REL_ CGW SG_ 104 CF_AVN_CluSubspeedOdometerDisp 0;
BA_REL_ "GenSigTimeoutTime" BU_SG_REL_ CLU SG_ 104 CF_AVN_CluSubspeedOdometerDisp 0;
BA_ "Platform" SG_ 104 CF_AVN_CluSubspeedOdometerDisp "D-Audio,Integrated AVN1.0 High,Integrated AVN1.0 Mid,Premium AVN 2.0";
BA_ "GenSigSendType" SG_ 104 CF_AVN_CluSubspeedOdometerDisp 3;
BA_ "TimeoutValue" SG_ 104 CF_AVN_CluSubspeedOdometerDisp "Invalid";
BA_ "Validity" SG_ 104 CF_AVN_CluSubspeedOdometerDisp 2;
BA_REL_ "GenSigTimeoutTime" BU_SG_REL_ CLU SG_ 104 CF_AVN_CluUserSettingDistance 0;
BA_ "Platform" SG_ 104 CF_AVN_CluUserSettingDistance "D-Audio,Integrated AVN1.0 High,Integrated AVN1.0 Mid,Premium AVN 2.0";
BA_ "GenSigSendType" SG_ 104 CF_AVN_CluUserSettingDistance 3;
BA_ "TimeoutValue" SG_ 104 CF_AVN_CluUserSettingDistance "Invalid";
BA_ "Validity" SG_ 104 CF_AVN_CluUserSettingDistance 2;
BA_REL_ "GenSigTimeoutTime" BU_SG_REL_ CGW SG_ 104 CF_AVN_EVReset 0;
BA_REL_ "GenSigTimeoutTime" BU_SG_REL_ CLU SG_ 104 CF_AVN_EVReset 0;
BA_ "SigDescription" SG_ 104 CF_AVN_EVReset "Request to reset EV Service (0x1 : EV USM Reset)";
BA_ "Platform" SG_ 104 CF_AVN_EVReset "0025";
BA_ "GenSigSendType" SG_ 104 CF_AVN_EVReset 3;
BA_ "Validity" SG_ 104 CF_AVN_EVReset 0;
BA_REL_ "GenSigTimeoutTime" BU_SG_REL_ CGW SG_ 104 CF_AVN_CluUSMReset 0;
BA_REL_ "GenSigTimeoutTime" BU_SG_REL_ CLU SG_ 104 CF_AVN_CluUSMReset 0;
BA_ "Platform" SG_ 104 CF_AVN_CluUSMReset "D-Audio,Integrated AVN1.0 High,Integrated AVN1.0 Mid,Premium AVN 2.0";
BA_ "GenSigSendType" SG_ 104 CF_AVN_CluUSMReset 3;
BA_ "TimeoutValue" SG_ 104 CF_AVN_CluUSMReset "Default";
BA_ "Validity" SG_ 104 CF_AVN_CluUSMReset 2;
BA_REL_ "GenSigTimeoutTime" BU_SG_REL_ CLU SG_ 104 CF_AVN_CluServiceReminderReset 0;
BA_ "Platform" SG_ 104 CF_AVN_CluServiceReminderReset "D-Audio,Integrated AVN1.0 High,Integrated AVN1.0 Mid,Premium AVN 2.0";
BA_ "GenSigSendType" SG_ 104 CF_AVN_CluServiceReminderReset 3;
BA_ "TimeoutValue" SG_ 104 CF_AVN_CluServiceReminderReset "Default";
BA_ "Validity" SG_ 104 CF_AVN_CluServiceReminderReset 2;
BA_REL_ "GenSigTimeoutTime" BU_SG_REL_ CLU SG_ 104 CF_AVN_IcyRoadWarn 0;
BA_ "Platform" SG_ 104 CF_AVN_IcyRoadWarn "D-Audio,Integrated AVN1.0 High,Integrated AVN1.0 Mid,Premium AVN 2.0";
BA_ "GenSigSendType" SG_ 104 CF_AVN_IcyRoadWarn 3;
BA_ "Validity" SG_ 104 CF_AVN_IcyRoadWarn 2;
BA_REL_ "GenSigTimeoutTime" BU_SG_REL_ CGW SG_ 104 CF_AVN_UnitReset 0;
BA_REL_ "GenSigTimeoutTime" BU_SG_REL_ CLU SG_ 104 CF_AVN_UnitReset 0;
BA_ "Platform" SG_ 104 CF_AVN_UnitReset "D-Audio,Integrated AVN1.0 High,Integrated AVN1.0 Mid,Premium AVN 2.0";
BA_ "GenSigSendType" SG_ 104 CF_AVN_UnitReset 3;
BA_ "Validity" SG_ 104 CF_AVN_UnitReset 2;
BA_ "GenMsgILSupport" BO_ 1165 0;
BA_ "TpMessage" BO_ 1165 1;
BA_ "TpTxIndex" BO_ 1165 2;
BA_REL_ "GenSigTimeoutTime" BU_SG_REL_ CLU SG_ 1165 Byte0_TCP_48D 0;
BA_ "Platform" SG_ 1165 Byte0_TCP_48D "";
BA_ "GenMsgILSupport" BO_ 1165 0;
BA_ "TpMessage" BO_ 1165 1;
BA_ "TpTxIndex" BO_ 1165 2;
BA_REL_ "GenSigTimeoutTime" BU_SG_REL_ CLU SG_ 1165 Byte1_Data_48D 0;
BA_ "Platform" SG_ 1165 Byte1_Data_48D "";
BA_ "GenMsgILSupport" BO_ 1165 0;
BA_ "TpMessage" BO_ 1165 1;
BA_ "TpTxIndex" BO_ 1165 2;
BA_REL_ "GenSigTimeoutTime" BU_SG_REL_ CLU SG_ 1165 Byte2_Data_48D 0;
BA_ "Platform" SG_ 1165 Byte2_Data_48D "";
BA_ "GenMsgILSupport" BO_ 1165 0;
BA_ "TpMessage" BO_ 1165 1;
BA_ "TpTxIndex" BO_ 1165 2;
BA_REL_ "GenSigTimeoutTime" BU_SG_REL_ CLU SG_ 1165 Byte3_Data_48D 0;
BA_ "Platform" SG_ 1165 Byte3_Data_48D "";
BA_ "GenMsgILSupport" BO_ 1165 0;
BA_ "TpMessage" BO_ 1165 1;
BA_ "TpTxIndex" BO_ 1165 2;
BA_REL_ "GenSigTimeoutTime" BU_SG_REL_ CLU SG_ 1165 Byte4_Data_48D 0;
BA_ "Platform" SG_ 1165 Byte4_Data_48D "";
BA_ "GenMsgILSupport" BO_ 1165 0;
BA_ "TpMessage" BO_ 1165 1;
BA_ "TpTxIndex" BO_ 1165 2;
BA_REL_ "GenSigTimeoutTime" BU_SG_REL_ CLU SG_ 1165 Byte5_Data_48D 0;
BA_ "Platform" SG_ 1165 Byte5_Data_48D "";
BA_ "GenMsgILSupport" BO_ 1165 0;
BA_ "TpMessage" BO_ 1165 1;
BA_ "TpTxIndex" BO_ 1165 2;
BA_REL_ "GenSigTimeoutTime" BU_SG_REL_ CLU SG_ 1165 Byte6_Data_48D 0;
BA_ "Platform" SG_ 1165 Byte6_Data_48D "";
BA_ "GenMsgILSupport" BO_ 1165 0;
BA_ "TpMessage" BO_ 1165 1;
BA_ "TpTxIndex" BO_ 1165 2;
BA_REL_ "GenSigTimeoutTime" BU_SG_REL_ CLU SG_ 1165 Byte7_Data_48D 0;
BA_ "Platform" SG_ 1165 Byte7_Data_48D "";
BA_ "GenMsgILSupport" BO_ 1207 0;
BA_ "TpMessage" BO_ 1207 1;
BA_ "TpTxIndex" BO_ 1207 40;
BA_REL_ "GenSigTimeoutTime" BU_SG_REL_ CLU SG_ 1207 Byte0_TCP_4B7 0;
BA_ "Platform" SG_ 1207 Byte0_TCP_4B7 "";
BA_ "GenMsgILSupport" BO_ 1207 0;
BA_ "TpMessage" BO_ 1207 1;
BA_ "TpTxIndex" BO_ 1207 40;
BA_REL_ "GenSigTimeoutTime" BU_SG_REL_ CLU SG_ 1207 Byte1_Data_4B7 0;
BA_ "Platform" SG_ 1207 Byte1_Data_4B7 "";
BA_ "GenMsgILSupport" BO_ 1207 0;
BA_ "TpMessage" BO_ 1207 1;
BA_ "TpTxIndex" BO_ 1207 40;
BA_REL_ "GenSigTimeoutTime" BU_SG_REL_ CLU SG_ 1207 Byte2_Data_4B7 0;
BA_ "Platform" SG_ 1207 Byte2_Data_4B7 "";
BA_ "GenMsgILSupport" BO_ 1207 0;
BA_ "TpMessage" BO_ 1207 1;
BA_ "TpTxIndex" BO_ 1207 40;
BA_REL_ "GenSigTimeoutTime" BU_SG_REL_ CLU SG_ 1207 Byte3_Data_4B7 0;
BA_ "Platform" SG_ 1207 Byte3_Data_4B7 "";
BA_ "GenMsgILSupport" BO_ 1207 0;
BA_ "TpMessage" BO_ 1207 1;
BA_ "TpTxIndex" BO_ 1207 40;
BA_REL_ "GenSigTimeoutTime" BU_SG_REL_ CLU SG_ 1207 Byte4_Data_4B7 0;
BA_ "Platform" SG_ 1207 Byte4_Data_4B7 "";
BA_ "GenMsgILSupport" BO_ 1207 0;
BA_ "TpMessage" BO_ 1207 1;
BA_ "TpTxIndex" BO_ 1207 40;
BA_REL_ "GenSigTimeoutTime" BU_SG_REL_ CLU SG_ 1207 Byte5_Data_4B7 0;
BA_ "Platform" SG_ 1207 Byte5_Data_4B7 "";
BA_ "GenMsgILSupport" BO_ 1207 0;
BA_ "TpMessage" BO_ 1207 1;
BA_ "TpTxIndex" BO_ 1207 40;
BA_REL_ "GenSigTimeoutTime" BU_SG_REL_ CLU SG_ 1207 Byte6_Data_4B7 0;
BA_ "Platform" SG_ 1207 Byte6_Data_4B7 "";
BA_ "GenMsgILSupport" BO_ 1207 0;
BA_ "TpMessage" BO_ 1207 1;
BA_ "TpTxIndex" BO_ 1207 40;
BA_REL_ "GenSigTimeoutTime" BU_SG_REL_ CLU SG_ 1207 Byte7_Data_4B7 0;
BA_ "Platform" SG_ 1207 Byte7_Data_4B7 "";
BA_ "GenMsgILSupport" BO_ 1204 0;
BA_ "TpMessage" BO_ 1204 1;
BA_ "TpTxIndex" BO_ 1204 3;
BA_REL_ "GenSigTimeoutTime" BU_SG_REL_ CLU SG_ 1204 Byte0_TCP_4B4 0;
BA_ "Platform" SG_ 1204 Byte0_TCP_4B4 "";
BA_ "GenMsgILSupport" BO_ 1204 0;
BA_ "TpMessage" BO_ 1204 1;
BA_ "TpTxIndex" BO_ 1204 3;
BA_REL_ "GenSigTimeoutTime" BU_SG_REL_ CLU SG_ 1204 Byte1_Data_4B4 0;
BA_ "Platform" SG_ 1204 Byte1_Data_4B4 "";
BA_ "GenMsgILSupport" BO_ 1204 0;
BA_ "TpMessage" BO_ 1204 1;
BA_ "TpTxIndex" BO_ 1204 3;
BA_REL_ "GenSigTimeoutTime" BU_SG_REL_ CLU SG_ 1204 Byte2_Data_4B4 0;
BA_ "Platform" SG_ 1204 Byte2_Data_4B4 "";
BA_ "GenMsgILSupport" BO_ 1204 0;
BA_ "TpMessage" BO_ 1204 1;
BA_ "TpTxIndex" BO_ 1204 3;
BA_REL_ "GenSigTimeoutTime" BU_SG_REL_ CLU SG_ 1204 Byte3_Data_4B4 0;
BA_ "Platform" SG_ 1204 Byte3_Data_4B4 "";
BA_ "GenMsgILSupport" BO_ 1204 0;
BA_ "TpMessage" BO_ 1204 1;
BA_ "TpTxIndex" BO_ 1204 3;
BA_REL_ "GenSigTimeoutTime" BU_SG_REL_ CLU SG_ 1204 Byte4_Data_4B4 0;
BA_ "Platform" SG_ 1204 Byte4_Data_4B4 "";
BA_ "GenMsgILSupport" BO_ 1204 0;
BA_ "TpMessage" BO_ 1204 1;
BA_ "TpTxIndex" BO_ 1204 3;
BA_REL_ "GenSigTimeoutTime" BU_SG_REL_ CLU SG_ 1204 Byte5_Data_4B4 0;
BA_ "Platform" SG_ 1204 Byte5_Data_4B4 "";
BA_ "GenMsgILSupport" BO_ 1204 0;
BA_ "TpMessage" BO_ 1204 1;
BA_ "TpTxIndex" BO_ 1204 3;
BA_REL_ "GenSigTimeoutTime" BU_SG_REL_ CLU SG_ 1204 Byte6_Data_4B4 0;
BA_ "Platform" SG_ 1204 Byte6_Data_4B4 "";
BA_ "GenMsgILSupport" BO_ 1204 0;
BA_ "TpMessage" BO_ 1204 1;
BA_ "TpTxIndex" BO_ 1204 3;
BA_REL_ "GenSigTimeoutTime" BU_SG_REL_ CLU SG_ 1204 Byte7_Data_4B4 0;
BA_ "Platform" SG_ 1204 Byte7_Data_4B4 "";
BA_ "GenMsgILSupport" BO_ 1166 0;
BA_ "TpMessage" BO_ 1166 1;
BA_ "TpTxIndex" BO_ 1166 28;
BA_REL_ "GenSigTimeoutTime" BU_SG_REL_ CLU SG_ 1166 Byte0_TCP_48E 0;
BA_ "Platform" SG_ 1166 Byte0_TCP_48E "";
BA_ "GenMsgILSupport" BO_ 1166 0;
BA_ "TpMessage" BO_ 1166 1;
BA_ "TpTxIndex" BO_ 1166 28;
BA_REL_ "GenSigTimeoutTime" BU_SG_REL_ CLU SG_ 1166 Byte1_Data_48E 0;
BA_ "Platform" SG_ 1166 Byte1_Data_48E "";
BA_ "GenMsgILSupport" BO_ 1166 0;
BA_ "TpMessage" BO_ 1166 1;
BA_ "TpTxIndex" BO_ 1166 28;
BA_REL_ "GenSigTimeoutTime" BU_SG_REL_ CLU SG_ 1166 Byte2_Data_48E 0;
BA_ "Platform" SG_ 1166 Byte2_Data_48E "";
BA_ "GenMsgILSupport" BO_ 1166 0;
BA_ "TpMessage" BO_ 1166 1;
BA_ "TpTxIndex" BO_ 1166 28;
BA_REL_ "GenSigTimeoutTime" BU_SG_REL_ CLU SG_ 1166 Byte3_Data_48E 0;
BA_ "Platform" SG_ 1166 Byte3_Data_48E "";
BA_ "GenMsgILSupport" BO_ 1166 0;
BA_ "TpMessage" BO_ 1166 1;
BA_ "TpTxIndex" BO_ 1166 28;
BA_REL_ "GenSigTimeoutTime" BU_SG_REL_ CLU SG_ 1166 Byte4_Data_48E 0;
BA_ "Platform" SG_ 1166 Byte4_Data_48E "";
BA_ "GenMsgILSupport" BO_ 1166 0;
BA_ "TpMessage" BO_ 1166 1;
BA_ "TpTxIndex" BO_ 1166 28;
BA_REL_ "GenSigTimeoutTime" BU_SG_REL_ CLU SG_ 1166 Byte5_Data_48E 0;
BA_ "Platform" SG_ 1166 Byte5_Data_48E "";
BA_ "GenMsgILSupport" BO_ 1166 0;
BA_ "TpMessage" BO_ 1166 1;
BA_ "TpTxIndex" BO_ 1166 28;
BA_REL_ "GenSigTimeoutTime" BU_SG_REL_ CLU SG_ 1166 Byte6_Data_48E 0;
BA_ "Platform" SG_ 1166 Byte6_Data_48E "";
BA_ "GenMsgILSupport" BO_ 1166 0;
BA_ "TpMessage" BO_ 1166 1;
BA_ "TpTxIndex" BO_ 1166 28;
BA_REL_ "GenSigTimeoutTime" BU_SG_REL_ CLU SG_ 1166 Byte7_Data_48E 0;
BA_ "Platform" SG_ 1166 Byte7_Data_48E "";
BA_ "GenMsgILSupport" BO_ 1157 0;
BA_ "TpMessage" BO_ 1157 1;
BA_ "TpTxIndex" BO_ 1157 10;
BA_REL_ "GenSigTimeoutTime" BU_SG_REL_ CLU SG_ 1157 Byte0_TCP_485 0;
BA_ "Platform" SG_ 1157 Byte0_TCP_485 "";
BA_ "GenMsgILSupport" BO_ 1157 0;
BA_ "TpMessage" BO_ 1157 1;
BA_ "TpTxIndex" BO_ 1157 10;
BA_REL_ "GenSigTimeoutTime" BU_SG_REL_ CLU SG_ 1157 Byte1_Data_485 0;
BA_ "Platform" SG_ 1157 Byte1_Data_485 "";
BA_ "GenMsgILSupport" BO_ 1157 0;
BA_ "TpMessage" BO_ 1157 1;
BA_ "TpTxIndex" BO_ 1157 10;
BA_REL_ "GenSigTimeoutTime" BU_SG_REL_ CLU SG_ 1157 Byte2_Data_485 0;
BA_ "Platform" SG_ 1157 Byte2_Data_485 "";
BA_ "GenMsgILSupport" BO_ 1157 0;
BA_ "TpMessage" BO_ 1157 1;
BA_ "TpTxIndex" BO_ 1157 10;
BA_REL_ "GenSigTimeoutTime" BU_SG_REL_ CLU SG_ 1157 Byte3_Data_485 0;
BA_ "Platform" SG_ 1157 Byte3_Data_485 "";
BA_ "GenMsgILSupport" BO_ 1157 0;
BA_ "TpMessage" BO_ 1157 1;
BA_ "TpTxIndex" BO_ 1157 10;
BA_REL_ "GenSigTimeoutTime" BU_SG_REL_ CLU SG_ 1157 Byte4_Data_485 0;
BA_ "Platform" SG_ 1157 Byte4_Data_485 "";
BA_ "GenMsgILSupport" BO_ 1157 0;
BA_ "TpMessage" BO_ 1157 1;
BA_ "TpTxIndex" BO_ 1157 10;
BA_REL_ "GenSigTimeoutTime" BU_SG_REL_ CLU SG_ 1157 Byte5_Data_485 0;
BA_ "Platform" SG_ 1157 Byte5_Data_485 "";
BA_ "GenMsgILSupport" BO_ 1157 0;
BA_ "TpMessage" BO_ 1157 1;
BA_ "TpTxIndex" BO_ 1157 10;
BA_REL_ "GenSigTimeoutTime" BU_SG_REL_ CLU SG_ 1157 Byte6_Data_485 0;
BA_ "Platform" SG_ 1157 Byte6_Data_485 "";
BA_ "GenMsgILSupport" BO_ 1157 0;
BA_ "TpMessage" BO_ 1157 1;
BA_ "TpTxIndex" BO_ 1157 10;
BA_REL_ "GenSigTimeoutTime" BU_SG_REL_ CLU SG_ 1157 Byte7_Data_485 0;
BA_ "Platform" SG_ 1157 Byte7_Data_485 "";
BA_ "GenMsgILSupport" BO_ 1167 0;
BA_ "TpMessage" BO_ 1167 1;
BA_ "TpTxIndex" BO_ 1167 8;
BA_REL_ "GenSigTimeoutTime" BU_SG_REL_ CLU SG_ 1167 Byte0_TCP_48F 0;
BA_ "Platform" SG_ 1167 Byte0_TCP_48F "";
BA_ "GenMsgILSupport" BO_ 1167 0;
BA_ "TpMessage" BO_ 1167 1;
BA_ "TpTxIndex" BO_ 1167 8;
BA_REL_ "GenSigTimeoutTime" BU_SG_REL_ CLU SG_ 1167 Byte1_Data_48F 0;
BA_ "Platform" SG_ 1167 Byte1_Data_48F "";
BA_ "GenMsgILSupport" BO_ 1167 0;
BA_ "TpMessage" BO_ 1167 1;
BA_ "TpTxIndex" BO_ 1167 8;
BA_REL_ "GenSigTimeoutTime" BU_SG_REL_ CLU SG_ 1167 Byte2_Data_48F 0;
BA_ "Platform" SG_ 1167 Byte2_Data_48F "";
BA_ "GenMsgILSupport" BO_ 1167 0;
BA_ "TpMessage" BO_ 1167 1;
BA_ "TpTxIndex" BO_ 1167 8;
BA_REL_ "GenSigTimeoutTime" BU_SG_REL_ CLU SG_ 1167 Byte3_Data_48F 0;
BA_ "Platform" SG_ 1167 Byte3_Data_48F "";
BA_ "GenMsgILSupport" BO_ 1167 0;
BA_ "TpMessage" BO_ 1167 1;
BA_ "TpTxIndex" BO_ 1167 8;
BA_REL_ "GenSigTimeoutTime" BU_SG_REL_ CLU SG_ 1167 Byte4_Data_48F 0;
BA_ "Platform" SG_ 1167 Byte4_Data_48F "";
BA_ "GenMsgILSupport" BO_ 1167 0;
BA_ "TpMessage" BO_ 1167 1;
BA_ "TpTxIndex" BO_ 1167 8;
BA_REL_ "GenSigTimeoutTime" BU_SG_REL_ CLU SG_ 1167 Byte5_Data_48F 0;
BA_ "Platform" SG_ 1167 Byte5_Data_48F "";
BA_ "GenMsgILSupport" BO_ 1167 0;
BA_ "TpMessage" BO_ 1167 1;
BA_ "TpTxIndex" BO_ 1167 8;
BA_REL_ "GenSigTimeoutTime" BU_SG_REL_ CLU SG_ 1167 Byte6_Data_48F 0;
BA_ "Platform" SG_ 1167 Byte6_Data_48F "";
BA_ "GenMsgILSupport" BO_ 1167 0;
BA_ "TpMessage" BO_ 1167 1;
BA_ "TpTxIndex" BO_ 1167 8;
BA_REL_ "GenSigTimeoutTime" BU_SG_REL_ CLU SG_ 1167 Byte7_Data_48F 0;
BA_ "Platform" SG_ 1167 Byte7_Data_48F "";
BA_ "GenMsgILSupport" BO_ 1179 0;
BA_ "TpMessage" BO_ 1179 1;
BA_ "TpTxIndex" BO_ 1179 9;
BA_REL_ "GenSigTimeoutTime" BU_SG_REL_ CLU SG_ 1179 Byte0_TCP_49B 0;
BA_ "Platform" SG_ 1179 Byte0_TCP_49B "";
BA_ "GenMsgILSupport" BO_ 1179 0;
BA_ "TpMessage" BO_ 1179 1;
BA_ "TpTxIndex" BO_ 1179 9;
BA_REL_ "GenSigTimeoutTime" BU_SG_REL_ CLU SG_ 1179 Byte1_Data_49B 0;
BA_ "Platform" SG_ 1179 Byte1_Data_49B "";
BA_ "GenMsgILSupport" BO_ 1179 0;
BA_ "TpMessage" BO_ 1179 1;
BA_ "TpTxIndex" BO_ 1179 9;
BA_REL_ "GenSigTimeoutTime" BU_SG_REL_ CLU SG_ 1179 Byte2_Data_49B 0;
BA_ "Platform" SG_ 1179 Byte2_Data_49B "";
BA_ "GenMsgILSupport" BO_ 1179 0;
BA_ "TpMessage" BO_ 1179 1;
BA_ "TpTxIndex" BO_ 1179 9;
BA_REL_ "GenSigTimeoutTime" BU_SG_REL_ CLU SG_ 1179 Byte3_Data_49B 0;
BA_ "Platform" SG_ 1179 Byte3_Data_49B "";
BA_ "GenMsgILSupport" BO_ 1179 0;
BA_ "TpMessage" BO_ 1179 1;
BA_ "TpTxIndex" BO_ 1179 9;
BA_REL_ "GenSigTimeoutTime" BU_SG_REL_ CLU SG_ 1179 Byte4_Data_49B 0;
BA_ "Platform" SG_ 1179 Byte4_Data_49B "";
BA_ "GenMsgILSupport" BO_ 1179 0;
BA_ "TpMessage" BO_ 1179 1;
BA_ "TpTxIndex" BO_ 1179 9;
BA_REL_ "GenSigTimeoutTime" BU_SG_REL_ CLU SG_ 1179 Byte5_Data_49B 0;
BA_ "Platform" SG_ 1179 Byte5_Data_49B "";
BA_ "GenMsgILSupport" BO_ 1179 0;
BA_ "TpMessage" BO_ 1179 1;
BA_ "TpTxIndex" BO_ 1179 9;
BA_REL_ "GenSigTimeoutTime" BU_SG_REL_ CLU SG_ 1179 Byte6_Data_49B 0;
BA_ "Platform" SG_ 1179 Byte6_Data_49B "";
BA_ "GenMsgILSupport" BO_ 1179 0;
BA_ "TpMessage" BO_ 1179 1;
BA_ "TpTxIndex" BO_ 1179 9;
BA_REL_ "GenSigTimeoutTime" BU_SG_REL_ CLU SG_ 1179 Byte7_Data_49B 0;
BA_ "Platform" SG_ 1179 Byte7_Data_49B "";
BA_ "GenMsgILSupport" BO_ 1168 0;
BA_ "TpMessage" BO_ 1168 1;
BA_ "TpTxIndex" BO_ 1168 14;
BA_REL_ "GenSigTimeoutTime" BU_SG_REL_ CLU SG_ 1168 Byte0_TCP_490 0;
BA_ "Platform" SG_ 1168 Byte0_TCP_490 "";
BA_ "GenMsgILSupport" BO_ 1168 0;
BA_ "TpMessage" BO_ 1168 1;
BA_ "TpTxIndex" BO_ 1168 14;
BA_REL_ "GenSigTimeoutTime" BU_SG_REL_ CLU SG_ 1168 Byte1_Data_490 0;
BA_ "Platform" SG_ 1168 Byte1_Data_490 "";
BA_ "GenMsgILSupport" BO_ 1168 0;
BA_ "TpMessage" BO_ 1168 1;
BA_ "TpTxIndex" BO_ 1168 14;
BA_REL_ "GenSigTimeoutTime" BU_SG_REL_ CLU SG_ 1168 Byte2_Data_490 0;
BA_ "Platform" SG_ 1168 Byte2_Data_490 "";
BA_ "GenMsgILSupport" BO_ 1168 0;
BA_ "TpMessage" BO_ 1168 1;
BA_ "TpTxIndex" BO_ 1168 14;
BA_REL_ "GenSigTimeoutTime" BU_SG_REL_ CLU SG_ 1168 Byte3_Data_490 0;
BA_ "Platform" SG_ 1168 Byte3_Data_490 "";
BA_ "GenMsgILSupport" BO_ 1168 0;
BA_ "TpMessage" BO_ 1168 1;
BA_ "TpTxIndex" BO_ 1168 14;
BA_REL_ "GenSigTimeoutTime" BU_SG_REL_ CLU SG_ 1168 Byte4_Data_490 0;
BA_ "Platform" SG_ 1168 Byte4_Data_490 "";
BA_ "GenMsgILSupport" BO_ 1168 0;
BA_ "TpMessage" BO_ 1168 1;
BA_ "TpTxIndex" BO_ 1168 14;
BA_REL_ "GenSigTimeoutTime" BU_SG_REL_ CLU SG_ 1168 Byte5_Data_490 0;
BA_ "Platform" SG_ 1168 Byte5_Data_490 "";
BA_ "GenMsgILSupport" BO_ 1168 0;
BA_ "TpMessage" BO_ 1168 1;
BA_ "TpTxIndex" BO_ 1168 14;
BA_REL_ "GenSigTimeoutTime" BU_SG_REL_ CLU SG_ 1168 Byte6_Data_490 0;
BA_ "Platform" SG_ 1168 Byte6_Data_490 "";
BA_ "GenMsgILSupport" BO_ 1168 0;
BA_ "TpMessage" BO_ 1168 1;
BA_ "TpTxIndex" BO_ 1168 14;
BA_REL_ "GenSigTimeoutTime" BU_SG_REL_ CLU SG_ 1168 Byte7_Data_490 0;
BA_ "Platform" SG_ 1168 Byte7_Data_490 "";
BA_ "GenMsgILSupport" BO_ 1206 0;
BA_ "TpMessage" BO_ 1206 1;
BA_ "TpTxIndex" BO_ 1206 4;
BA_REL_ "GenSigTimeoutTime" BU_SG_REL_ CLU SG_ 1206 Byte0_TCP_4B6 0;
BA_ "Platform" SG_ 1206 Byte0_TCP_4B6 "";
BA_ "GenMsgILSupport" BO_ 1206 0;
BA_ "TpMessage" BO_ 1206 1;
BA_ "TpTxIndex" BO_ 1206 4;
BA_REL_ "GenSigTimeoutTime" BU_SG_REL_ CLU SG_ 1206 Byte1_Data_4B6 0;
BA_ "Platform" SG_ 1206 Byte1_Data_4B6 "";
BA_ "GenMsgILSupport" BO_ 1206 0;
BA_ "TpMessage" BO_ 1206 1;
BA_ "TpTxIndex" BO_ 1206 4;
BA_REL_ "GenSigTimeoutTime" BU_SG_REL_ CLU SG_ 1206 Byte2_Data_4B6 0;
BA_ "Platform" SG_ 1206 Byte2_Data_4B6 "";
BA_ "GenMsgILSupport" BO_ 1206 0;
BA_ "TpMessage" BO_ 1206 1;
BA_ "TpTxIndex" BO_ 1206 4;
BA_REL_ "GenSigTimeoutTime" BU_SG_REL_ CLU SG_ 1206 Byte3_Data_4B6 0;
BA_ "Platform" SG_ 1206 Byte3_Data_4B6 "";
BA_ "GenMsgILSupport" BO_ 1206 0;
BA_ "TpMessage" BO_ 1206 1;
BA_ "TpTxIndex" BO_ 1206 4;
BA_REL_ "GenSigTimeoutTime" BU_SG_REL_ CLU SG_ 1206 Byte4_Data_4B6 0;
BA_ "Platform" SG_ 1206 Byte4_Data_4B6 "";
BA_ "GenMsgILSupport" BO_ 1206 0;
BA_ "TpMessage" BO_ 1206 1;
BA_ "TpTxIndex" BO_ 1206 4;
BA_REL_ "GenSigTimeoutTime" BU_SG_REL_ CLU SG_ 1206 Byte5_Data_4B6 0;
BA_ "Platform" SG_ 1206 Byte5_Data_4B6 "";
BA_ "GenMsgILSupport" BO_ 1206 0;
BA_ "TpMessage" BO_ 1206 1;
BA_ "TpTxIndex" BO_ 1206 4;
BA_REL_ "GenSigTimeoutTime" BU_SG_REL_ CLU SG_ 1206 Byte6_Data_4B6 0;
BA_ "Platform" SG_ 1206 Byte6_Data_4B6 "";
BA_ "GenMsgILSupport" BO_ 1206 0;
BA_ "TpMessage" BO_ 1206 1;
BA_ "TpTxIndex" BO_ 1206 4;
BA_REL_ "GenSigTimeoutTime" BU_SG_REL_ CLU SG_ 1206 Byte7_Data_4B6 0;
BA_ "Platform" SG_ 1206 Byte7_Data_4B6 "";
BA_ "NmMessage" BO_ 1101 1;
BA_ "GenMsgILSupport" BO_ 1101 0;
BA_ "NmMessage" BO_ 1096 1;
BA_ "GenMsgILSupport" BO_ 1096 0;
BA_ "NmMessage" BO_ 1088 1;
BA_ "GenMsgILSupport" BO_ 1088 0;
BA_ "NmMessage" BO_ 1109 1;
BA_ "GenMsgILSupport" BO_ 1109 0;
BA_ "NmMessage" BO_ 1099 1;
BA_ "GenMsgILSupport" BO_ 1099 0;
VAL_ 1408 AMP_Support_ElecSound 0 "Null" 1 "False" 2 "True" 3 "Invalid" ;
VAL_ 362 C_AV_Tail 0 "Default" 1 "Deactived" 2 "Actived" 3 "Invalid" ;
VAL_ 362 C_IGN1 0 "IGN1 OFF" 1 "IGN1 ON" 3 "Invalid" ;
VAL_ 491 C_OSMirrorStatus 0 "Stop" 1 "Fold" 2 "Unfold" 3 "Invalid" ;
VAL_ 378 CF_DAW_OptUSM 0 "None DAW Option" 1 "System Disable(OFF)" 2 "Reserved" 3 "System Enable(Normal)" 4 "System Enable(Early)" 5 "Reserved" 6 "Reserved" 7 "Invalid" ;
VAL_ 378 FCA_DrvSetState 0 "Default(None FCA)" 1 "Late" 2 "Normal" 3 "Reserved" 4 "Reserved" 5 "Reserved" 6 "Reserved" 7 "Invalid" ;
VAL_ 378 CF_BCW_DrvSetState 0 "Default" 1 "Late" 2 "Normal" 3 "Reserved" 4 "Reserved" 5 "Reserved" 6 "Reserved" 7 "Invalid" ;
VAL_ 378 NSCC_Camera_USM 0 "Not Applied" 1 "Function Off" 2 "Function On" 3 "Invalid" ;
VAL_ 378 CF_SEA_USM 0 "Default" 1 "Disable" 2 "Enable" 3 "Invalid" ;
VAL_ 378 SCCDrvModeRValue 0 "Default" 1 "Comfort Mode" 2 "Normal Mode" 3 "Dynamic Mode" 4 "Reserved" 5 "Reserved" 6 "Reserved" 7 "Invalid" ;
VAL_ 378 CF_LKA_Opt_USM 0 "Default(None LDW/LKA Option" 1 "LDW" 2 "LKA" 3 "Reserved" 4 "LDW only ON(None LKA)" 5 "LDW only OFF" 6 "LDW/LKA OFF" 7 "Invalid" ;
VAL_ 378 NSCC_Curve_USM 0 "Not Applied" 1 "Function Off" 2 "Function On" 3 "Invalid" ;
VAL_ 378 CF_RCCW_USM 0 "Default" 1 "Off" 2 "Warning" 3 "Invalid" ;
VAL_ 378 CF_TirePressure_Unit 0 "Psi" 1 "Kpa" 2 "Bar" 3 "Invalid" ;
VAL_ 378 FCA_USM 0 "Default(None FCA)" 1 "Off" 2 "Warning" 3 "Assist" 4 "Reserved" 5 "Reserved" 6 "Reserved" 7 "Invalid" ;
VAL_ 378 CF_BCA_USM 0 "Default" 1 "Off" 2 "Warning" 3 "Assist" 4 "Reserved" 5 "Reserved" 6 "Reserved" 7 "Invalid" ;
VAL_ 378 CF_BCW_USM 0 "Default" 1 "Off" 2 "On" 3 "Invalid" ;
VAL_ 378 CF_LFA_Opt_USM 0 "Default" 1 "Off" 2 "On" 3 "Invalid" ;
VAL_ 379 CF_Gway_ADrLRValue 0 "Default" 1 "Off" 2 "Vehicle Spped ON(15km)" 3 "Shift Lever ON" 4 "Reserved" 5 "Reserved" 6 "Reserved" 7 "Invalid" ;
VAL_ 379 CF_Gway_WPCRValue 0 "Default" 1 "Off(Disable)" 2 "ON(Enable)" 3 "Invalid" ;
VAL_ 379 CF_Gway_ADrURValue 0 "Default" 1 "Off" 2 "Key Out ON(All Doors)" 3 "Shift Lever ON(All Doors)" 4 "Override" 5 "Invalid" 6 "Key Out ON(Driver Door)" 7 "Shift Lever ON(Driver Door)" ;
VAL_ 379 C_WelcomeSysTitleOption 0 "Default" 1 "Welcome Mirror Light" 2 "Welcome Mirror" 3 "Welcome Light(Reserved)" 4 "Reserved" 5 "Reserved" 6 "Reserved" 7 "Invalid" ;
VAL_ 379 CF_Gway_OTTurnRValue 0 "Default" 1 "One Touch Turn Off" 2 "3 Flashing" 3 "5 Flashing" 4 "7 Flashing" 5 "Invalid" 6 "Reserved" 7 "Reserved" ;
VAL_ 379 CF_Gway_EscortHLRValue 0 "Default" 1 "Escort OFF" 2 "Escort ON" 3 "Invalid" ;
VAL_ 379 C_UnlockWelcomeRValue 0 "Default" 1 "Off" 2 "On" 3 "Invalid" ;
VAL_ 379 C_SmartWelcomRValue 0 "Default" 1 "Off" 2 "On" 3 "Invalid" ;
VAL_ 379 C_RearWiperRValue 0 "Default" 1 "Rear Wiper(Reverse) Off" 2 "Rear Wiper(Reverse) On" 3 "Invalid" ;
VAL_ 379 CF_Gway_TTUnlockRValue 0 "Default" 1 "Off" 2 "On" 3 "Invalid" ;
VAL_ 379 CR_Datc_DRSeatWheel_USM_State 0 "Not Apply" 1 "Off" 2 "On" 3 "Invalid" ;
VAL_ 379 CR_Datc_DRSeatHeat_USM_State 0 "Not Apply" 1 "Off" 2 "On" 3 "Invalid" ;
VAL_ 468 Clu_Usm_VoiceVolume 0 "Default" 1 "Level0 (mute)" 2 "Level1" 3 "Level2" 4 "Level3" 5 "Reserved" 6 "Reserved" 7 "Invalid" ;
VAL_ 468 Clu_Usm_AutoinitFuelEconomy 0 "Default" 1 "Off" 2 "Driving" 3 "Refuel" 4 "Reserved" 5 "Reserved" 6 "Reserved" 7 "Invalid" ;
VAL_ 468 Clu_Usm_WelcomeSound 0 "Default" 1 "Off" 2 "On" 3 "Invalid" ;
VAL_ 468 CLU_Usm_Roadinfoguide 0 "Default" 1 "Off" 2 "On" 3 "Invalid" ;
VAL_ 468 CLU_Usm_WiperLight 0 "Default" 1 "Off" 2 "On" 3 "Invalid" ;
VAL_ 468 Clu_Usm_TransmissionDisp 0 "Default" 1 "Off" 2 "On" 3 "Invalid" ;
VAL_ 468 Clu_Usm_FuelEconUnit_km 0 "Default" 1 "km/L" 2 "L/100km" 3 "Reserved" ;
VAL_ 468 Clu_Usm_AdasVolume 0 "Default" 1 "Level1" 2 "Level2" 3 "Level3" 4 "Reserved" 5 "Reserved" 6 "OFF" 7 "Invalid" ;
VAL_ 468 Clu_Usm_SubspeedometerDisp 0 "Default" 1 "Off" 2 "On" 3 "Invalid" ;
VAL_ 468 Clu_Usm_FuelEconUnit_mi 0 "Default" 1 "US gallon" 2 "UK gallon" 3 "Reserved" ;
VAL_ 468 Clu_Usm_IcyRoadWarn 0 "Default" 1 "Off" 2 "On" 3 "Invalid" ;
VAL_ 468 Warn_Sound_AdasVolumeFeedback 0 "Default" 1 "Level1" 2 "Level2" 3 "Level3" 4 "Reserved" 5 "Reserved" 6 "OFF" 7 "Invalid" ;
VAL_ 469 Clu_Usm_ServiceReminderMode 0 "Default" 1 "Customer Mode" 2 "Workshop Mode" 3 "Invalid" ;
VAL_ 469 Clu_Usm_ServiceReminderSet 0 "Default" 1 "Off" 2 "On" 3 "Invalid" ;
VAL_ 469 Clu_Usm_ServiceReminderUnit 0 "km" 1 "mile" ;
VAL_ 469 Clu_SrvRmndrAlrm 0 "No alarm" 1 "Alarm" 2 "reserved" 3 "Invalid" ;
VAL_ 469 Clu_Usm_ServiceUsersetPeriod 0 "0~99" 1 "0~99" 2 "0~99" 3 "0~99" 4 "0~99" 5 "0~99" 6 "0~99" 7 "0~99" 8 "0~99" 9 "0~99" 10 "0~99" 11 "0~99" 12 "0~99" 13 "0~99" 14 "0~99" 15 "0~99" 16 "0~99" 17 "0~99" 18 "0~99" 19 "0~99" 20 "0~99" 21 "0~99" 22 "0~99" 23 "0~99" 24 "0~99" 25 "0~99" 26 "0~99" 27 "0~99" 28 "0~99" 29 "0~99" 30 "0~99" 31 "0~99" 32 "0~99" 33 "0~99" 34 "0~99" 35 "0~99" 36 "0~99" 37 "0~99" 38 "0~99" 39 "0~99" 40 "0~99" 41 "0~99" 42 "0~99" 43 "0~99" 44 "0~99" 45 "0~99" 46 "0~99" 47 "0~99" 48 "0~99" 49 "0~99" 50 "0~99" 51 "0~99" 52 "0~99" 53 "0~99" 54 "0~99" 55 "0~99" 56 "0~99" 57 "0~99" 58 "0~99" 59 "0~99" 60 "0~99" 61 "0~99" 62 "0~99" 63 "0~99" 64 "0~99" 65 "0~99" 66 "0~99" 67 "0~99" 68 "0~99" 69 "0~99" 70 "0~99" 71 "0~99" 72 "0~99" 73 "0~99" 74 "0~99" 75 "0~99" 76 "0~99" 77 "0~99" 78 "0~99" 79 "0~99" 80 "0~99" 81 "0~99" 82 "0~99" 83 "0~99" 84 "0~99" 85 "0~99" 86 "0~99" 87 "0~99" 88 "0~99" 89 "0~99" 90 "0~99" 91 "0~99" 92 "0~99" 93 "0~99" 94 "0~99" 95 "0~99" 96 "0~99" 97 "0~99" 98 "0~99" 99 "0~99" ;
VAL_ 469 Clu_Usm_ServiceUsersetDistance 0 "0x00000~0x1869F:0~99999" 99999 "0x00000~0x1869F:0~99999" ;
VAL_ 469 Clu_Usm_ServiceRemainPeriod 0 "0x0000~0x270F:0~9999" 9999 "0x0000~0x270F:0~9999" ;
VAL_ 469 Clu_Usm_ServiceRemainDistance 0 "0x00000~0x1869F:0~9999" 99999 "0x00000~0x1869F:0~9999" ;
VAL_ 485 Navi_OverSpdAlarm 0 "None" 1 "Alarm" 2 "reserved" 3 "Invalid" ;
VAL_ 485 Navi_NonSpdTrap 0 "None" 1 "Red Light Trap" 2 "Bus Only Trap" 3 "Cut In Trap" 4 "Parking/Stopping Trap" 5 "Overloaded Trap" 6 "Badloaded Trap" 7 "Shoulder Trap" 8 "Plate Recogn. Camera" 9 "Traffic Camera" 10 "Intersection Block Trap" 11 "Ramp Metering Trap" 12 "User Registered Camera" 13 "Others" 31 "Invalid" ;
VAL_ 485 Navi_WarningZone2 0 "None" 1 "continuous decent" 16 "Steep decent" 17 "tunnel" 18 "Road floods" 19 "Uneven road surface" 20 "Unguarded railroad crossing" 21 "Zipper road" 22 "Two-way traffic" 23 "Cattle crossing" 24 "Hills on the right" 25 "Embankment on the right" 26 "Embankment on the left" 27 "Village" 28 "Pass left or right obstacle" 29 "pass left of obstacle" 30 "pass right of obstacle" 31 "Invarid" 2 "cross wind" 3 "Hills on the left" 4 "humpback bridge" 5 "Confluence from the left" 6 "confluence from the right" 7 "Stop to give way" 8 "Road narrows from both sides" 9 "Narrow bridge" 10 "Road narrows from the left" 11 "Road narrows from the right" 12 "Falling rocks on the left" 13 "Falling rocks on the right" 14 "slippery road" 15 "Steep ascent" ;
VAL_ 485 Navi_WarningZone 0 "None" 1 "Black Spot" 2 "School Zone" 3 "Falling Rocks" 4 "Railway Crossing" 5 "Foggy Area" 6 "Downhill" 7 "Roadkill" 8 "Speed Bump" 9 "Bottleneck" 10 "Under Construction" 15 "Invalid" ;
VAL_ 485 Navi_WarningZone3 0 "None" 1 "danger ahead" 2 "overtaking allowed" 3 "audible warning" 4 "text warning sign which ia not included in GB5768-1999" 5 "yield to oncoming traffic" 6 "yield" 7 "tunnel lights" 8 "tidal lane" 9 "road lying" 10 "Hov lane" 11 "Reserved" 12 "Reserved" 13 "Reserved" 14 "Reserved" 15 "Invalid" ;
VAL_ 485 Navi_CurveWarning 0 "None" 1 "Right" 2 "Left" 3 "Right Curve Continuously" 4 "Left Curve Continuously" 5 "Curve Continuously" 6 "Winding road" 7 "Reserved" 8 "Reserved" 9 "Reserved" 10 "Reserved" 11 "Reserved" 12 "Reserved" 13 "Reserved" 14 "Reserved" 15 "Invalid" ;
VAL_ 485 Navi_SpdLimit_Type 0 "None" 1 "US" 2 "Canada" 3 "Invalid" ;
VAL_ 485 Navi_SpdLimit_Unit 0 "None" 1 "Kilometer" 2 "Mile" 3 "Invalid" ;
VAL_ 485 Navi_SpdInfo_Type 0 "Off" 1 "FixedSpeedTrap" 2 "FixedSpeedTrapNoInfo" 3 "MobileSpeedTrap" 4 "MobileSpeedTrapNoInfo" 5 "SpeedRedlightTrap" 6 "SpeedRedlightTrapNoInfo" 7 "BusSpeedTrap" 8 "BusSpeedTrapNoInfo" 9 "SpeedLimitType1" 10 "SpeedLimitSchoolzoneType1" 11 "SpeedLimitType2" 12 "SpeedLimitSchoolzoneType2" 13 "EU Camera zone warning" 15 "Invalid" ;
VAL_ 485 Navi_SpdLimit 0 "None" 1 "0x01~0xFE:1~254" 254 "0x01~0xFE:1~254" 255 "Invalid" ;
VAL_ 487 NV_EstDist_F 0 "physical distance" 1 "physical distance" 2 "physical distance" 3 "physical distance" 4 "physical distance" 5 "physical distance" 6 "physical distance" 7 "physical distance" 8 "physical distance" 9 "physical distance" 10 "Reserved" 11 "Reserved" 12 "Reserved" 13 "Reserved" 14 "Reserved" 15 "invalid" ;
VAL_ 487 NV_EstDist_Unit 0 "meter" 1 "kilometer" 2 "mile" 3 "feet" 5 "Reserved" 6 "Reserved" 7 "Reserved" 8 "Reserved" 9 "Reserved" 10 "Reserved" 11 "Reserved" 12 "Reserved" 13 "Reserved" 14 "Reserved" 15 "invalid" 4 "yard" ;
VAL_ 487 NV_EstHour 0 "hour" 23 "hour" 255 "invalid" ;
VAL_ 487 NV_EstMin 0 "minutes" 59 "minutes" 255 "invalid" ;
VAL_ 487 NV_Azimuth 0 "Increase value (0~352.5 deg.)" 1 "Increase value (0~352.5 deg.)" 2 "Increase value (0~352.5 deg.)" 3 "Increase value (0~352.5 deg.)" 4 "Increase value (0~352.5 deg.)" 5 "Increase value (0~352.5 deg.)" 6 "Increase value (0~352.5 deg.)" 7 "Increase value (0~352.5 deg.)" 8 "Increase value (0~352.5 deg.)" 9 "Increase value (0~352.5 deg.)" 10 "Increase value (0~352.5 deg.)" 11 "Increase value (0~352.5 deg.)" 12 "Increase value (0~352.5 deg.)" 13 "Increase value (0~352.5 deg.)" 14 "Increase value (0~352.5 deg.)" 15 "Increase value (0~352.5 deg.)" 16 "Increase value (0~352.5 deg.)" 17 "Increase value (0~352.5 deg.)" 18 "Increase value (0~352.5 deg.)" 19 "Increase value (0~352.5 deg.)" 20 "Increase value (0~352.5 deg.)" 21 "Increase value (0~352.5 deg.)" 22 "Increase value (0~352.5 deg.)" 23 "Increase value (0~352.5 deg.)" 24 "Increase value (0~352.5 deg.)" 25 "Increase value (0~352.5 deg.)" 26 "Increase value (0~352.5 deg.)" 27 "Increase value (0~352.5 deg.)" 28 "Increase value (0~352.5 deg.)" 29 "Increase value (0~352.5 deg.)" 30 "Increase value (0~352.5 deg.)" 31 "Increase value (0~352.5 deg.)" 32 "Increase value (0~352.5 deg.)" 33 "Increase value (0~352.5 deg.)" 34 "Increase value (0~352.5 deg.)" 35 "Increase value (0~352.5 deg.)" 36 "Increase value (0~352.5 deg.)" 37 "Increase value (0~352.5 deg.)" 38 "Increase value (0~352.5 deg.)" 39 "Increase value (0~352.5 deg.)" 40 "Increase value (0~352.5 deg.)" 41 "Increase value (0~352.5 deg.)" 42 "Increase value (0~352.5 deg.)" 43 "Increase value (0~352.5 deg.)" 44 "Increase value (0~352.5 deg.)" 45 "Increase value (0~352.5 deg.)" 46 "Increase value (0~352.5 deg.)" 47 "Increase value (0~352.5 deg.)" 255 "Invalid" ;
VAL_ 487 NV_EstDist_I 0 "0" 65534 "65534" 65535 "invalid" ;
VAL_ 487 NV_EstimTimeType 0 "None" 1 "Estimate Time of Arrival" 2 "Remaining Time to Arrive" 3 "Invalid" ;
VAL_ 487 NV_EstimTimeFormat 0 "None" 1 "12 hour" 2 "24 hour" 3 "Invalid" ;
VAL_ 487 NV_EstPointType 0 "destination" 1 "waypoint1" 2 "waypoint2" 3 "waypoint3" 4 "waypoint4" 5 "reserved" 6 "reserved" 7 "reserved" 8 "reserved" 9 "reserved" 10 "reserved" 11 "reserved" 12 "reserved" 13 "reserved" 14 "reserved" 15 "invalid" ;
VAL_ 369 HU_VehiclePwr 0 "Key out or Audio OFF" 1 "Not used" 2 "ACC or Audio ON" 3 "KBD Wake-up" 4 "Not used" 5 "Not used" 6 "Not used" 7 "Not used" 8 "Not used" 9 "Not used" 10 "Not used" 11 "Not used" 12 "Not used" 13 "Not used" 14 "Not used" 15 "Invalid" ;
VAL_ 448 HU_VRActivity 0 "Deactivated" 1 "Activated" 2 "reserved" 3 "Invalid" ;
VAL_ 448 HU_PhoneActivity 0 "Deactivated" 1 "Activated" 2 "reserved" 3 "Invalid" ;
VAL_ 371 HU_AliveStatus 0 "Not Ready" 1 "On Mode" 2 "Head Unit Update Mode" 3 "Invalid" ;
VAL_ 371 HU_DistanceUnit 0 "Km" 1 "Mile" 2 "Reserved" 3 "Invalid" ;
VAL_ 371 HU_TempUnit 0 "Off" 1 "¡É(Centigrade)" 2 "¢µ(Fahrenheit)" 3 "Invalid" ;
VAL_ 458 POS_MessageType 0 "Reserved" 1 "Position" 2 "Segment" 3 "Stub" 4 "Profile Short" 5 "Profile Long" 6 "Meta Data" 7 "Invalid" ;
VAL_ 458 POS_Offset 0 "0x0~0x1FFE:Distance" 8190 "0x0~0x1FFE:Distance" 8191 "Invalid" ;
VAL_ 458 POS_PathIndex 0 "Unknown" 1 "Reserved" 2 "Reserved" 3 "Reserved" 4 "Reserved" 5 "Reserved" 6 "Reserved" 7 "Reserved" 8 "General Path Index" 9 "General Path Index" 10 "General Path Index" 11 "General Path Index" 12 "General Path Index" 13 "General Path Index" 14 "General Path Index" 15 "General Path Index" 16 "General Path Index" 17 "General Path Index" 18 "General Path Index" 19 "General Path Index" 20 "General Path Index" 21 "General Path Index" 22 "General Path Index" 23 "General Path Index" 24 "General Path Index" 25 "General Path Index" 26 "General Path Index" 27 "General Path Index" 28 "General Path Index" 29 "General Path Index" 30 "General Path Index" 31 "General Path Index" 32 "General Path Index" 33 "General Path Index" 34 "General Path Index" 35 "General Path Index" 36 "General Path Index" 37 "General Path Index" 38 "General Path Index" 39 "General Path Index" 40 "General Path Index" 41 "General Path Index" 42 "General Path Index" 43 "General Path Index" 44 "General Path Index" 45 "General Path Index" 46 "General Path Index" 47 "General Path Index" 48 "General Path Index" 49 "General Path Index" 50 "General Path Index" 51 "General Path Index" 52 "General Path Index" 53 "General Path Index" 54 "General Path Index" 55 "General Path Index" 56 "General Path Index" 57 "General Path Index" 58 "General Path Index" 59 "General Path Index" 60 "General Path Index" 61 "General Path Index" 62 "General Path Index" 63 "General Path Index" ;
VAL_ 458 POS_CyclicCounter 0 "Cyclic Counter" 1 "Cyclic Counter" 2 "Cyclic Counter" 3 "Cyclic Counter" ;
VAL_ 458 POS_PositionProbability 0 "Unknown" 1 "Position Probability" 2 "Position Probability" 3 "Position Probability" 4 "Position Probability" 5 "Position Probability" 6 "Position Probability" 7 "Position Probability" 8 "Position Probability" 9 "Position Probability" 10 "Position Probability" 11 "Position Probability" 12 "Position Probability" 13 "Position Probability" 14 "Position Probability" 15 "Position Probability" 16 "Position Probability" 17 "Position Probability" 18 "Position Probability" 19 "Position Probability" 20 "Position Probability" 21 "Position Probability" 22 "Position Probability" 23 "Position Probability" 24 "Position Probability" 25 "Position Probability" 26 "Position Probability" 27 "Position Probability" 28 "Position Probability" 29 "Position Probability" 30 "Position Probability" 31 "Invalid" ;
VAL_ 458 POS_PositionIndex 0 "Most probable position" 1 "Second candidate" 2 "Third candidate" 3 "Invalid" ;
VAL_ 458 POS_PositionAge 0 "Unknown" 1 "0x1~0xFE:Position Age" 254 "0x1~0xFE:Position Age" 511 "Invalid" ;
VAL_ 458 POS_CurrentLane 0 "Unknown" 1 "Energency lane" 2 "Single lane road" 3 "Left most lane" 4 "Right most lane" 5 "One of middle lanes on the road with three or more lanes" 6 "Reserved" 7 "Invalid" ;
VAL_ 458 POS_PositionConfidence 0 "Highest confidence" 1 "Position confidence" 2 "Position confidence" 3 "Position confidence" 4 "Position confidence" 5 "Position confidence" 6 "lowest confidence" 7 "Invalid" ;
VAL_ 458 POS_RangeAvgSpeed 0 "0x0~0xFD:Range Camera Average Speed" 253 "0x0~0xFD:Range Camera Average Speed" 254 "0xFE~0x1FE:Reserved" 510 "0xFE~0x1FE:Reserved" 511 "Invalid" ;
VAL_ 458 POS_RelativeHeading 0 "In path direction" 1 "1.417 degrees right" 2 "0x2~0x7D:Right from path direction" 125 "0x2~0x7D:Right from path direction" 126 "178.583 degrees right" 127 "Opposite direction" 128 "178.583 degrees left" 129 "0x81~0xFC:Left from path direction" 252 "0x81~0xFC:Left from path direction" 253 "1.417 degrees left" 254 "Unknown" 255 "Invalid" ;
VAL_ 202 SEG_MessageType 0 "Reserved" 1 "Position" 2 "Segment" 3 "Stub" 4 "Profile Short" 5 "Profile Long" 6 "Meta Data" 7 "Invalid" ;
VAL_ 202 SEG_Offset 0 "0x0~0x1FFE:Distance" 8190 "0x0~0x1FFE:Distance" 8191 "Invalid" ;
VAL_ 202 SEG_PathIndex 0 "Unknown" 1 "Reserved" 2 "Reserved" 3 "Reserved" 4 "Reserved" 5 "Reserved" 6 "Reserved" 7 "Reserved" 8 "General Path Index" 9 "General Path Index" 10 "General Path Index" 11 "General Path Index" 12 "General Path Index" 13 "General Path Index" 14 "General Path Index" 15 "General Path Index" 16 "General Path Index" 17 "General Path Index" 18 "General Path Index" 19 "General Path Index" 20 "General Path Index" 21 "General Path Index" 22 "General Path Index" 23 "General Path Index" 24 "General Path Index" 25 "General Path Index" 26 "General Path Index" 27 "General Path Index" 28 "General Path Index" 29 "General Path Index" 30 "General Path Index" 31 "General Path Index" 32 "General Path Index" 33 "General Path Index" 34 "General Path Index" 35 "General Path Index" 36 "General Path Index" 37 "General Path Index" 38 "General Path Index" 39 "General Path Index" 40 "General Path Index" 41 "General Path Index" 42 "General Path Index" 43 "General Path Index" 44 "General Path Index" 45 "General Path Index" 46 "General Path Index" 47 "General Path Index" 48 "General Path Index" 49 "General Path Index" 50 "General Path Index" 51 "General Path Index" 52 "General Path Index" 53 "General Path Index" 54 "General Path Index" 55 "General Path Index" 56 "General Path Index" 57 "General Path Index" 58 "General Path Index" 59 "General Path Index" 60 "General Path Index" 61 "General Path Index" 62 "General Path Index" 63 "General Path Index" ;
VAL_ 202 SEG_CyclicCounter 0 "Cyclic Counter" 1 "Cyclic Counter" 2 "Cyclic Counter" 3 "Cyclic Counter" ;
VAL_ 202 SEG_Update 0 "False" 1 "True" ;
VAL_ 202 SEG_Retransmission 0 "False" 1 "True" ;
VAL_ 202 SEG_BuiltUpArea 0 "Not part of built-up area" 1 "Part of built-up area" 2 "Unknown" 3 "Invalid" ;
VAL_ 202 SEG_Bridge 0 "Not part of a bridge" 1 "Part of a bridge" 2 "Unknown" 3 "Invalid" ;
VAL_ 202 SEG_Tunnel 0 "Not part of a tunnel" 1 "Part of a tunnel" 2 "Unknown" 3 "Invalid" ;
VAL_ 202 SEG_FunctionalRoadClass 0 "Unknown" 1 "Freeway" 2 "Arterial(City freeway)" 3 "County" 4 "Collector" 5 "Local" 6 "Etc(ferry, unpaved)" 7 "Invalid" ;
VAL_ 202 SEG_RelativeProbability 0 "Driving not allowed" 1 "Relative probability" 2 "Relative probability" 3 "Relative probability" 4 "Relative probability" 5 "Relative probability" 6 "Relative probability" 7 "Relative probability" 8 "Relative probability" 9 "Relative probability" 10 "Relative probability" 11 "Relative probability" 12 "Relative probability" 13 "Relative probability" 14 "Relative probability" 15 "Relative probability" 16 "Relative probability" 17 "Relative probability" 18 "Relative probability" 19 "Relative probability" 20 "Relative probability" 21 "Relative probability" 22 "Relative probability" 23 "Relative probability" 24 "Relative probability" 25 "Relative probability" 26 "Relative probability" 27 "Relative probability" 28 "Relative probability" 29 "Relative probability" 30 "Relative probability" 31 "Invalid" ;
VAL_ 202 SEG_FormOfWay 0 "Unkonwn" 1 "Main road(nondisjunction)" 2 "Main road(disjunction)" 3 "JC" 4 "Plural Junction M" 5 "IC" 6 "Reserved" 7 "Service Area" 8 "Reserved" 9 "Roundabout" 10 "P turn" 11 "U trun" 12 "Pedestrian" 13 "Frontage Road" 14 "Intersection internal(Plural Junction)" 15 "Invalid" ;
VAL_ 202 SEG_ComplexIntersection 0 "Not part of complex intersection" 1 "Part of of complex intersection" 2 "Unknown" 3 "Invalid" ;
VAL_ 202 SEG_CalculatedRoute 0 "Not Calculated Route(MPP)" 1 "Part of Calculated Route" 2 "Off Route or Recalculating" 3 "Invalid" ;
VAL_ 202 SEG_SpeedLimitType 0 "Implicit(default)" 1 "Explicit(on traffic sign)" 2 "Explicit(by night)" 3 "Explicit(by day)" 4 "Explicit(time of day)" 5 "Explicit(rain)" 6 "Explicit(snow)" 7 "Unknown" ;
VAL_ 202 SEG_SpeedLimit 0 "Unknown" 1 "Under 5kph(mph)" 2 "7kph(mph)" 3 "10kph(mph)" 4 "15kph(mph)" 5 "20kph(mph)" 6 "25kph(mph)" 7 "30kph(mph)" 8 "35kph(mph)" 9 "40kph(mph)" 10 "45kph(mph)" 11 "50kph(mph)" 12 "55kph(mph)" 13 "60kph(mph)" 14 "65kph(mph)" 15 "70kph(mph)" 16 "75kph(mph)" 17 "80kph(mph)" 18 "85kph(mph)" 19 "90kph(mph)" 20 "95kph(mph)" 21 "100kph(mph)" 22 "105kph(mph)" 23 "110kph(mph)" 24 "115kph(mph)" 25 "120kph(mph)" 26 "130kph(mph)" 27 "140kph(mph)" 28 "150kph(mph)" 29 "160kph(mph)" 30 "Unlimited" 31 "Invalid" ;
VAL_ 202 SEG_DirectionLanes 0 "Unknown" 1 "Lane count" 2 "Lane count" 3 "Lane count" 4 "Lane count" 5 "Lane count" 6 "6 or more lanes" 7 "Invalid" ;
VAL_ 202 SEG_SpeedLimitUnder5 0 "0 kph(mph)" 1 "1 kph(mph)" 2 "2 kph(mph)" 3 "3 kph(mph)" 4 "4 kph(mph)" 5 "Reserved" 6 "Reserved" 7 "Invalid" ;
VAL_ 203 STUB_MessageType 0 "Reserved" 1 "Position" 2 "Segment" 3 "Stub" 4 "Profile Short" 5 "Profile Long" 6 "Meta Data" 7 "Invalid" ;
VAL_ 203 STUB_Offset 0 "0x0~0x1FFE:Distance" 8190 "0x0~0x1FFE:Distance" 8191 "Invalid" ;
VAL_ 203 STUB_PathIndex 0 "first path in the Horizon" 1 "Reserved" 2 "Reserved" 3 "Reserved" 4 "Reserved" 5 "Reserved" 6 "Reserved" 7 "Reserved" 8 "General Path Index" 9 "General Path Index" 10 "General Path Index" 11 "General Path Index" 12 "General Path Index" 13 "General Path Index" 14 "General Path Index" 15 "General Path Index" 16 "General Path Index" 17 "General Path Index" 18 "General Path Index" 19 "General Path Index" 20 "General Path Index" 21 "General Path Index" 22 "General Path Index" 23 "General Path Index" 24 "General Path Index" 25 "General Path Index" 26 "General Path Index" 27 "General Path Index" 28 "General Path Index" 29 "General Path Index" 30 "General Path Index" 31 "General Path Index" 32 "General Path Index" 33 "General Path Index" 34 "General Path Index" 35 "General Path Index" 36 "General Path Index" 37 "General Path Index" 38 "General Path Index" 39 "General Path Index" 40 "General Path Index" 41 "General Path Index" 42 "General Path Index" 43 "General Path Index" 44 "General Path Index" 45 "General Path Index" 46 "General Path Index" 47 "General Path Index" 48 "General Path Index" 49 "General Path Index" 50 "General Path Index" 51 "General Path Index" 52 "General Path Index" 53 "General Path Index" 54 "General Path Index" 55 "General Path Index" 56 "General Path Index" 57 "General Path Index" 58 "General Path Index" 59 "General Path Index" 60 "General Path Index" 61 "General Path Index" 62 "General Path Index" 63 "General Path Index" ;
VAL_ 203 STUB_CyclicCounter 0 "Cyclic Counter" 1 "Cyclic Counter" 2 "Cyclic Counter" 3 "Cyclic Counter" ;
VAL_ 203 STUB_Update 0 "False" 1 "True" ;
VAL_ 203 STUB_Retransmission 0 "False" 1 "True" ;
VAL_ 203 STUB_SubPathIndex 0 "Unknown" 1 "Reserved" 2 "Reserved" 3 "Reserved" 4 "Reserved" 5 "Reserved" 6 "Reserved" 7 "Reserved" 8 "General Path Index" 9 "General Path Index" 10 "General Path Index" 11 "General Path Index" 12 "General Path Index" 13 "General Path Index" 14 "General Path Index" 15 "General Path Index" 16 "General Path Index" 17 "General Path Index" 18 "General Path Index" 19 "General Path Index" 20 "General Path Index" 21 "General Path Index" 22 "General Path Index" 23 "General Path Index" 24 "General Path Index" 25 "General Path Index" 26 "General Path Index" 27 "General Path Index" 28 "General Path Index" 29 "General Path Index" 30 "General Path Index" 31 "General Path Index" 32 "General Path Index" 33 "General Path Index" 34 "General Path Index" 35 "General Path Index" 36 "General Path Index" 37 "General Path Index" 38 "General Path Index" 39 "General Path Index" 40 "General Path Index" 41 "General Path Index" 42 "General Path Index" 43 "General Path Index" 44 "General Path Index" 45 "General Path Index" 46 "General Path Index" 47 "General Path Index" 48 "General Path Index" 49 "General Path Index" 50 "General Path Index" 51 "General Path Index" 52 "General Path Index" 53 "General Path Index" 54 "General Path Index" 55 "General Path Index" 56 "General Path Index" 57 "General Path Index" 58 "General Path Index" 59 "General Path Index" 60 "General Path Index" 61 "General Path Index" 62 "General Path Index" 63 "General Path Index" ;
VAL_ 203 STUB_FunctionalRoadClass 0 "Unknown" 1 "Freeway" 2 "Arterial(City freeway)" 3 "County" 4 "Collector" 5 "Local" 6 "Etc(ferry, unpaved)" 7 "Invalid" ;
VAL_ 203 STUB_RelativeProbability 0 "Turn not allowed" 1 "Relative probability" 2 "Relative probability" 3 "Relative probability" 4 "Relative probability" 5 "Relative probability" 6 "Relative probability" 7 "Relative probability" 8 "Relative probability" 9 "Relative probability" 10 "Relative probability" 11 "Relative probability" 12 "Relative probability" 13 "Relative probability" 14 "Relative probability" 15 "Relative probability" 16 "Relative probability" 17 "Relative probability" 18 "Relative probability" 19 "Relative probability" 20 "Relative probability" 21 "Relative probability" 22 "Relative probability" 23 "Relative probability" 24 "Relative probability" 25 "Relative probability" 26 "Relative probability" 27 "Relative probability" 28 "Relative probability" 29 "Relative probability" 30 "Relative probability" 31 "Invalid" ;
VAL_ 203 STUB_FormOfWay 0 "Unknown" 1 "Main path(nondisjunction)" 2 "Main path(disjunction)" 3 "JC" 4 "Plural Junction M" 5 "IC" 6 "Reserved" 7 "Service Area" 8 "Reserved" 9 "Roundabout" 10 "P turn" 11 "U trun" 12 "Pedestrian" 13 "Frontage Road" 14 "Intersection internal(Plural Junction C)" 15 "Invalid" ;
VAL_ 203 STUB_ComplexIntersection 0 "Not part of complex intersection" 1 "Part of of complex intersection" 2 "Unknown" 3 "Invalid" ;
VAL_ 203 STUB_CalculatedRoute 0 "Not Calculated Route(MPP)" 1 "Part of Calculated Route" 2 "Off Route or Recalculating Route" 3 "Invalid" ;
VAL_ 203 STUB_TurnAngle 0 "In path direction" 1 "1.417 degrees right" 2 "0x2~0x7D:Right from relative to parent path direction" 125 "0x2~0x7D:Right from relative to parent path direction" 126 "178.583 degrees right(181.417 degrees left)" 127 "Opposite direction" 128 "178.583 degrees left" 129 "0x81~0xFC:Left from relative to parent path direction" 252 "0x81~0xFC:Left from relative to parent path direction" 253 "1.417 degrees left(358.583 degrees right)" 254 "Unknown" 255 "Invalid" ;
VAL_ 203 STUB_DirectionLanes 0 "Unknown" 1 "Lane count" 2 "Lane count" 3 "Lane count" 4 "Lane count" 5 "Lane count" 6 "6 or more lanes" 7 "Invalid" ;
VAL_ 203 STUB_RightOfWay 0 "Parent path has right of way" 1 "Sub-path has right of way" 2 "Unknown" 3 "Invalid" ;
VAL_ 203 STUB_LastStubAtOffset 0 "more STUB messages will be sent" 1 "last one of given parent" ;
VAL_ 88 HU_RVM_CameraOff 0 "Default" 1 "Camera Off" 2 "Not Used" 3 "Invalid" ;
VAL_ 101 CF_AVN_LFANValueSet 0 "Default" 1 "Off" 2 "On" 3 "Invalid" ;
VAL_ 101 CF_AVN_FCANValueSet 0 "Default(None FCA)" 1 "Off" 2 "Warning" 3 "Assist" 4 "Reserved" 5 "Reserved" 6 "Reserved" 7 "Invalid" ;
VAL_ 101 CF_AVN_HDANValueSet 0 "Default" 1 "Off" 2 "On" 3 "Invalid" ;
VAL_ 101 CF_AVN_DAWModeNValueSet 0 "Default" 1 "Off" 2 "Reserved" 3 "Normal" 4 "Early" 5 "Reserved" 6 "Reserved" 7 "Invalid" ;
VAL_ 101 CF_AVN_SCCDrvModeNValueSet 0 "Default" 1 "Comfort" 2 "Normal" 3 "Dynamic" 4 "Reserved" 5 "Reserved" 6 "Reserved" 7 "Invalid" ;
VAL_ 101 CF_AVN_NSCCCamNValueSet 0 "Default" 1 "Disable" 2 "Enable" 3 "Invalid" ;
VAL_ 101 CF_AVN_SEANValueSet 0 "Default" 1 "Disable" 2 "Enable" 3 "Invalid" ;
VAL_ 101 CF_AVN_BCWNValueSet 0 "Default" 1 "Off" 2 "Warning" 3 "Invalid" ;
VAL_ 101 CF_AVN_WarningTimingNValueSet 0 "Default" 1 "Late" 2 "Normal" 3 "Reserved" 4 "Reserved" 5 "Reserved" 6 "Reserved" 7 "Invalid" ;
VAL_ 101 CF_AVN_ISLWNValueSet 0 "Default" 1 "Off" 2 "Warning" 3 "Invalid" ;
VAL_ 101 CF_AVN_BCANValueSet 0 "Default" 1 "Off" 2 "Warning" 3 "Assist" 4 "Reserved" 5 "Reserved" 6 "Reserved" 7 "Invalid" ;
VAL_ 101 CF_AVN_RCCWNValueSet 0 "Default" 1 "Off" 2 "Warning" 3 "Invalid" ;
VAL_ 101 CF_AVN_BCWSndWanNValueSet 0 "Off" 1 "Disable" 2 "Enable" 3 "Invalid" ;
VAL_ 101 CF_AVN_NSCCCrvNValueSet 0 "Default" 1 "Disable" 2 "Enable" 3 "Invalid" ;
VAL_ 101 CF_SccFrVehDptNotiNValueSet 0 "Default" 1 "Off" 2 "On" 3 "Invalid" ;
VAL_ 101 CF_AVN_LkaModeNValueSet 0 "Default" 1 "LDW mode" 2 "LKA" 3 "Reserved" 4 "LDW Only ON(None LKA)" 5 "LDW only OFF" 6 "LDW/LKA OFF" 7 "Invalid" ;
VAL_ 101 CF_AVN_AdasVolumeNValueSet 0 "Default" 1 "Level 1" 2 "Level 2" 3 "Level 3" 4 "Reserved" 5 "Reserved" 6 "Off" 7 "Invalid" ;
VAL_ 102 CF_AVN_PTGSpeedNValueSet 0 "Default" 1 "Fast" 2 "Slow" 3 "Invalid" ;
VAL_ 102 CF_Avn_HAPTICWARNINGNValueSet 0 "Default" 1 "Weak" 2 "Medium" 3 "Strong" 4 "Reserved" 5 "Reserved" 6 "Reserved" 7 "Invalid" ;
VAL_ 104 CF_AVN_CluVoiceVolume 0 "Default" 1 "Level0" 2 "Level1" 3 "Level2" 4 "Level3" 5 "Reserved" 6 "Reserved" 7 "Invalid" ;
VAL_ 104 CF_AVN_CluAutoInitFuelEconomy 0 "Default" 1 "Off" 2 "Driving" 3 "Refuel" 4 "Reserved" 5 "Reserved" 6 "Reserved" 7 "Invalid" ;
VAL_ 104 CF_AVN_CluWelcomeSnd 0 "Default" 1 "Off" 2 "On" 3 "Invalid" ;
VAL_ 104 CF_AVN_CluRoadInfoGuide 0 "Default" 1 "Off" 2 "On" 3 "Invalid" ;
VAL_ 104 CF_AVN_CluWiperLight 0 "Default" 1 "Off" 2 "On" 3 "Invalid" ;
VAL_ 104 CF_AVN_CluTransmissionDisp 0 "Default" 1 "Off" 2 "On" 3 "Invalid" ;
VAL_ 104 CF_AVN_CluServiceReminderSet 0 "Default" 1 "Off" 2 "On" 3 "Invalid" ;
VAL_ 104 CF_AVN_CluUserSettingPeriod 0 "0~99month" 1 "0~99month" 2 "0~99month" 3 "0~99month" 4 "0~99month" 5 "0~99month" 6 "0~99month" 7 "0~99month" 8 "0~99month" 9 "0~99month" 10 "0~99month" 11 "0~99month" 12 "0~99month" 13 "0~99month" 14 "0~99month" 15 "0~99month" 16 "0~99month" 17 "0~99month" 18 "0~99month" 19 "0~99month" 20 "0~99month" 21 "0~99month" 22 "0~99month" 23 "0~99month" 24 "0~99month" 25 "0~99month" 26 "0~99month" 27 "0~99month" 28 "0~99month" 29 "0~99month" 30 "0~99month" 31 "0~99month" 32 "0~99month" 33 "0~99month" 34 "0~99month" 35 "0~99month" 36 "0~99month" 37 "0~99month" 38 "0~99month" 39 "0~99month" 40 "0~99month" 41 "0~99month" 42 "0~99month" 43 "0~99month" 44 "0~99month" 45 "0~99month" 46 "0~99month" 47 "0~99month" 48 "0~99month" 49 "0~99month" 50 "0~99month" 51 "0~99month" 52 "0~99month" 53 "0~99month" 54 "0~99month" 55 "0~99month" 56 "0~99month" 57 "0~99month" 58 "0~99month" 59 "0~99month" 60 "0~99month" 61 "0~99month" 62 "0~99month" 63 "0~99month" 64 "0~99month" 65 "0~99month" 66 "0~99month" 67 "0~99month" 68 "0~99month" 69 "0~99month" 70 "0~99month" 71 "0~99month" 72 "0~99month" 73 "0~99month" 74 "0~99month" 75 "0~99month" 76 "0~99month" 77 "0~99month" 78 "0~99month" 79 "0~99month" 80 "0~99month" 81 "0~99month" 82 "0~99month" 83 "0~99month" 84 "0~99month" 85 "0~99month" 86 "0~99month" 87 "0~99month" 88 "0~99month" 89 "0~99month" 90 "0~99month" 91 "0~99month" 92 "0~99month" 93 "0~99month" 94 "0~99month" 95 "0~99month" 96 "0~99month" 97 "0~99month" 98 "0~99month" 99 "0~99month" 100 "Reserved" 101 "Reserved" 102 "Reserved" 103 "Reserved" 104 "Reserved" 105 "Reserved" 106 "Reserved" 107 "Reserved" 108 "Reserved" 109 "Reserved" 110 "Reserved" 111 "Reserved" 112 "Reserved" 113 "Reserved" 114 "Reserved" 115 "Reserved" 116 "Reserved" 117 "Reserved" 118 "Reserved" 119 "Reserved" 120 "Reserved" 121 "Reserved" 122 "Reserved" 123 "Reserved" 124 "Reserved" 125 "Reserved" 126 "Reserved" 127 "Invalid" ;
VAL_ 104 CF_AVN_CluFuelEconUnit_km 0 "Default" 1 "km/L" 2 "L/100km" 3 "Reserved" ;
VAL_ 104 CF_AVN_CluFuelEconUnit_mi 0 "Default" 1 "US gallon" 2 "UK gallon" 3 "Reserved" ;
VAL_ 104 CF_AVN_CluSubspeedOdometerDisp 0 "Default" 1 "Off" 2 "On" 3 "Invalid" ;
VAL_ 104 CF_AVN_CluUserSettingDistance 0 "0x0~0x1869F:0~9999km/mi" 99999 "0x0~0x1869F:0~9999km/mi" 131071 "Invalid" ;
VAL_ 104 CF_AVN_EVReset 0 "Default" 1 "USM Reset" 2 "Reserved" 3 "Invalid" ;
VAL_ 104 CF_AVN_CluUSMReset 0 "Default" 1 "USM Reset" 2 "Reserved" 3 "Invalid" ;
VAL_ 104 CF_AVN_CluServiceReminderReset 0 "Default" 1 "Service Reminder Reset" 2 "Reserved" 3 "Invalid" ;
VAL_ 104 CF_AVN_IcyRoadWarn 0 "Default" 1 "Off" 2 "On" 3 "Invalid" ;
VAL_ 104 CF_AVN_UnitReset 0 "Default" 1 "Unit Reset" 2 "Reserved" 3 "Invalid" ;
VAL_ 1101 NMSleepFlag_CLU 0 "Alive" 1 "SleepInd" 3 "SleepAck" ;
VAL_ 1101 NMCommandCode_CLU 1 "Alive" 2 "Ring" 4 "Limphome" ;
VAL_ 1096 NMSleepFlag_AMP 0 "Alive" 1 "SleepInd" 3 "SleepAck" ;
VAL_ 1096 NMCommandCode_AMP 1 "Alive" 2 "Ring" 4 "Limphome" ;
VAL_ 1088 NMSleepFlag_H_U 0 "Alive" 1 "SleepInd" 3 "SleepAck" ;
VAL_ 1088 NMCommandCode_H_U 1 "Alive" 2 "Ring" 4 "Limphome" ;
VAL_ 1109 NMSleepFlag_CGW 0 "Alive" 1 "SleepInd" 3 "SleepAck" ;
VAL_ 1109 NMCommandCode_CGW 1 "Alive" 2 "Ring" 4 "Limphome" ;
VAL_ 1099 NMSleepFlag_TMU 0 "Alive" 1 "SleepInd" 3 "SleepAck" ;
VAL_ 1099 NMCommandCode_TMU 1 "Alive" 2 "Ring" 4 "Limphome" ;
